VERSION "$Format:%h$"

NS_ :

BS_:

BU_: APB APP APS BCCEN BDY DAS DBG EAS EPAS EPAS2 EPAS3S EPB EPBM ESP GTW GTWU IBST IC MCU OCS PARK PARK3 RADAR RCM RT3000 SCCM SDM SEC TAS TAS2 TAS2DBG TOOL TPMS VCSEATD VCSEATP

BO_ 1412 SD_RS_SCCM: 8 SCCM
 SG_ SD_RS_SCCM : 7|64@0+ (1,0) [0|0] "" Vector__XXX

BO_ 1284 SG_APPL_SCCM: 8 SCCM
 SG_ SG_APPL_SCCM : 7|64@0+ (1,0) [0|0] "" Vector__XXX

BO_ 69 STW_ACTN_RQ: 8 SCCM
 SG_ SpdCtrlLvr_Stat : 0|6@1+ (1,0) [0|0] "" GTW,DAS,EPB
 SG_ VSL_Enbl_Rq : 6|1@1+ (1,0) [0|0] "" GTW,EPB,DAS
 SG_ SpdCtrlLvrStat_Inv : 7|1@1+ (1,0) [0|0] "" GTW
 SG_ DTR_Dist_Rq : 8|8@1+ (1,0) [0|200] "" GTW,DAS
 SG_ TurnIndLvr_Stat : 16|2@1+ (1,0) [0|0] "" DAS,BDY,GTW,PARK
 SG_ HiBmLvr_Stat : 18|2@1+ (1,0) [0|0] "" BDY,BCCEN,DAS,GTW
 SG_ WprWashSw_Psd : 20|2@1+ (1,0) [0|0] "" BDY,BCCEN,DAS,GTW
 SG_ WprWash_R_Sw_Posn_V2 : 22|2@1+ (1,0) [0|0] "" BDY,BCCEN,GTW
 SG_ StW_Lvr_Stat : 24|3@1+ (1,0) [0|0] "" GTW
 SG_ StW_Cond_Flt : 27|1@1+ (1,0) [0|0] "" GTW
 SG_ StW_Cond_Psd : 28|2@1+ (1,0) [0|0] "" GTW
 SG_ HrnSw_Psd : 30|2@1+ (1,0) [0|0] "" SEC,BDY,BCCEN,GTW,APP
 SG_ StW_Sw00_Psd : 32|1@1+ (1,0) [0|0] "" GTW,DAS
 SG_ StW_Sw01_Psd : 33|1@1+ (1,0) [0|0] "" GTW,DAS
 SG_ StW_Sw02_Psd : 34|1@1+ (1,0) [0|0] "" GTW,DAS
 SG_ StW_Sw03_Psd : 35|1@1+ (1,0) [0|0] "" GTW,DAS
 SG_ StW_Sw04_Psd : 36|1@1+ (1,0) [0|0] "" GTW,DAS
 SG_ StW_Sw05_Psd : 37|1@1+ (1,0) [0|0] "" GTW,DAS
 SG_ StW_Sw06_Psd : 38|1@1+ (1,0) [0|0] "" GTW,DAS
 SG_ StW_Sw07_Psd : 39|1@1+ (1,0) [0|0] "" GTW,DAS
 SG_ StW_Sw08_Psd : 40|1@1+ (1,0) [0|0] "" GTW,DAS
 SG_ StW_Sw09_Psd : 41|1@1+ (1,0) [0|0] "" GTW,DAS
 SG_ StW_Sw10_Psd : 42|1@1+ (1,0) [0|0] "" GTW,DAS
 SG_ StW_Sw11_Psd : 43|1@1+ (1,0) [0|0] "" GTW,DAS
 SG_ StW_Sw12_Psd : 44|1@1+ (1,0) [0|0] "" GTW,DAS
 SG_ StW_Sw13_Psd : 45|1@1+ (1,0) [0|0] "" GTW,DAS
 SG_ StW_Sw14_Psd : 46|1@1+ (1,0) [0|0] "" GTW
 SG_ StW_Sw15_Psd : 47|1@1+ (1,0) [0|0] "" GTW
 SG_ WprSw6Posn : 48|3@1+ (1,0) [0|0] "" BDY,BCCEN,GTW,APP
 SG_ MC_STW_ACTN_RQ : 52|4@1+ (1,0) [0|15] "" GTW
 SG_ CRC_STW_ACTN_RQ : 56|8@1+ (1,0) [0|0] "" GTW

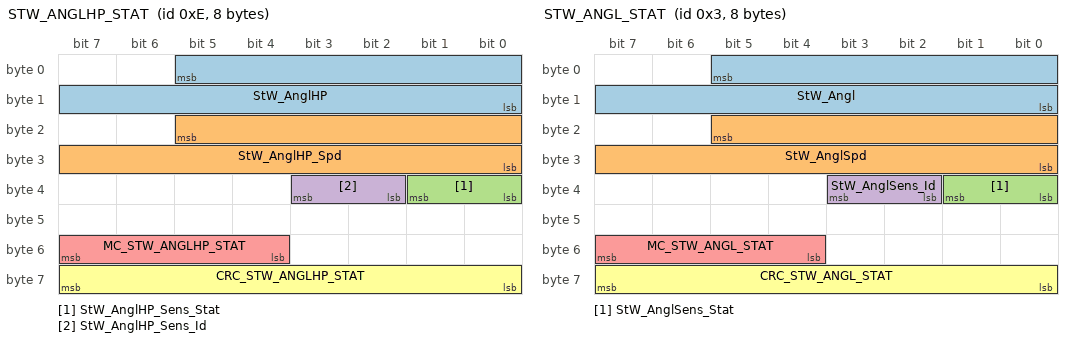
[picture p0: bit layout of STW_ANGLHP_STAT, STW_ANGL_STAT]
BO_ 14 STW_ANGLHP_STAT: 8 SCCM
 SG_ StW_AnglHP : 5|14@0+ (0.1,-819.2) [-819.2|819] "deg" DAS,GTW,ESP,RCM,PARK,EPAS,EPAS2,EPAS3S,TAS
 SG_ StW_AnglHP_Spd : 21|14@0+ (0.5,-4096) [-4096|4095.5] "deg/s" GTW,DAS,PARK,EPAS,EPAS2,EPAS3S,TAS
 SG_ StW_AnglHP_Sens_Stat : 33|2@0+ (1,0) [0|0] "" DAS,GTW,ESP,PARK,EPAS,EPAS2,EPAS3S,TAS,RCM
 SG_ StW_AnglHP_Sens_Id : 35|2@0+ (1,0) [0|0] "" GTW,PARK,EPAS,EPAS2,EPAS3S
 SG_ MC_STW_ANGLHP_STAT : 55|4@0+ (1,0) [0|15] "" GTW,ESP,RCM,PARK,EPAS,EPAS2,EPAS3S,TAS
 SG_ CRC_STW_ANGLHP_STAT : 63|8@0+ (1,0) [0|0] "" ESP,GTW,RCM,PARK,EPAS,EPAS2,EPAS3S,TAS

BO_ 3 STW_ANGL_STAT: 8 SCCM
 SG_ StW_Angl : 5|14@0+ (0.5,-2048) [-2048|2047] "deg" SDM,BDY,BCCEN,GTW
 SG_ StW_AnglSpd : 21|14@0+ (0.5,-2048) [-2048|2047] "/s" GTW
 SG_ StW_AnglSens_Stat : 33|2@0+ (1,0) [0|0] "" SDM,BDY,BCCEN,GTW
 SG_ StW_AnglSens_Id : 35|2@0+ (1,0) [0|0] "" GTW
 SG_ MC_STW_ANGL_STAT : 55|4@0+ (1,0) [0|15] "" SDM,GTW
 SG_ CRC_STW_ANGL_STAT : 63|8@0+ (1,0) [0|0] "" SDM,GTW

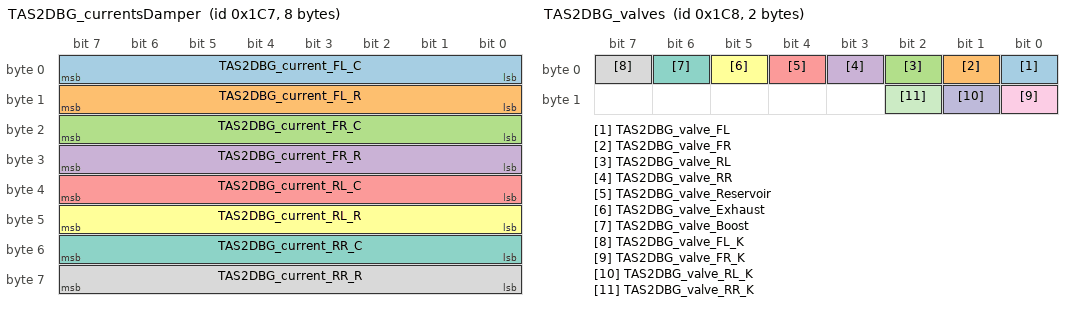
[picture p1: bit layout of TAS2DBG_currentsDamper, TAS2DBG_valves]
BO_ 455 TAS2DBG_currentsDamper: 8 TAS2DBG
 SG_ TAS2DBG_current_FL_C : 0|8@1+ (0.0075,0) [0|1.9125] "A" TAS2
 SG_ TAS2DBG_current_FL_R : 8|8@1+ (0.0075,0) [0|1.9125] "A" TAS2
 SG_ TAS2DBG_current_FR_C : 16|8@1+ (0.0075,0) [0|1.9125] "A" TAS2
 SG_ TAS2DBG_current_FR_R : 24|8@1+ (0.0075,0) [0|1.9125] "A" TAS2
 SG_ TAS2DBG_current_RL_C : 32|8@1+ (0.0075,0) [0|1.9125] "A" TAS2
 SG_ TAS2DBG_current_RL_R : 40|8@1+ (0.0075,0) [0|1.9125] "A" TAS2
 SG_ TAS2DBG_current_RR_C : 48|8@1+ (0.0075,0) [0|1.9125] "A" TAS2
 SG_ TAS2DBG_current_RR_R : 56|8@1+ (0.0075,0) [0|1.9125] "A" TAS2

BO_ 456 TAS2DBG_valves: 2 TAS2DBG
 SG_ TAS2DBG_valve_FL : 0|1@1+ (1,0) [0|1] "" TAS2
 SG_ TAS2DBG_valve_FR : 1|1@1+ (1,0) [0|1] "" TAS2
 SG_ TAS2DBG_valve_RL : 2|1@1+ (1,0) [0|1] "" TAS2
 SG_ TAS2DBG_valve_RR : 3|1@1+ (1,0) [0|1] "" TAS2
 SG_ TAS2DBG_valve_Reservoir : 4|1@1+ (1,0) [0|1] "" TAS2
 SG_ TAS2DBG_valve_Exhaust : 5|1@1+ (1,0) [0|1] "" TAS2
 SG_ TAS2DBG_valve_Boost : 6|1@1+ (1,0) [0|1] "" TAS2
 SG_ TAS2DBG_valve_FL_K : 7|1@1+ (1,0) [0|1] "" TAS2
 SG_ TAS2DBG_valve_FR_K : 8|1@1+ (1,0) [0|1] "" TAS2
 SG_ TAS2DBG_valve_RL_K : 9|1@1+ (1,0) [0|1] "" TAS2
 SG_ TAS2DBG_valve_RR_K : 10|1@1+ (1,0) [0|1] "" TAS2

BO_ 1340 TAS2_alertCleared: 2 TAS2
 SG_ TAS2_alertClearedID : 0|9@1+ (1,0) [0|317] "" Vector__XXX

BO_ 1293 TAS2_alertLog: 8 TAS2
 SG_ TAS2_alertID M : 0|9@1+ (1,0) [0|317] "" GTW
 SG_ TAS2_alertType : 15|1@1+ (1,0) [0|1] "" GTW
 SG_ TAS2_a000_alertDataW0 m0 : 16|16@1+ (1,0) [0|65535] "" Vector__XXX
 SG_ TAS2_a000_alertDataW1 m0 : 32|16@1+ (1,0) [0|65535] "" Vector__XXX
 SG_ TAS2_a000_alertDataW2 m0 : 48|16@1+ (1,0) [0|65535] "" Vector__XXX
 SG_ TAS2_a001_InternalWatchdog m1 : 16|1@1+ (1,0) [0|1] "" GTW
 SG_ TAS2_a002_CPUUndervoltage m2 : 16|1@1+ (1,0) [0|1] "" GTW
 SG_ TAS2_a002_PowerOnReset m2 : 17|1@1+ (1,0) [0|1] "" GTW
 SG_ TAS2_a003_AssertID m3 : 16|16@1+ (1,0) [0|65535] "" GTW
 SG_ TAS2_a003_LineNumber m3 : 32|16@1+ (1,0) [0|65535] "" GTW
 SG_ TAS2_a003_Data m3 : 48|16@1+ (1,0) [0|65535] "" GTW
 SG_ TAS2_a012_ClockError m12 : 16|1@1+ (1,0) [0|1] "" GTW
 SG_ TAS2_a012_FlashError m12 : 17|1@1+ (1,0) [0|1] "" GTW
 SG_ TAS2_a012_SoftwareReset m12 : 18|1@1+ (1,0) [0|1] "" GTW
 SG_ TAS2_a012_CheckstopReset m12 : 19|1@1+ (1,0) [0|1] "" GTW
 SG_ TAS2_a012_DebugReset m12 : 20|1@1+ (1,0) [0|1] "" GTW
 SG_ TAS2_a012_ExternalReset m12 : 21|1@1+ (1,0) [0|1] "" GTW
 SG_ TAS2_a015_NVMMRecordNotFound m15 : 16|1@1+ (1,0) [0|1] "" GTW
 SG_ TAS2_a015_NVMMCRCMismatch m15 : 17|1@1+ (1,0) [0|1] "" GTW
 SG_ TAS2_a015_NVMMVersionMismatch m15 : 18|1@1+ (1,0) [0|1] "" GTW
 SG_ TAS2_a015_NVMMRecordUpgraded m15 : 19|1@1+ (1,0) [0|1] "" GTW
 SG_ TAS2_a015_NVMMMemOverflow m15 : 20|1@1+ (1,0) [0|1] "" GTW
 SG_ TAS2_a015_NVMMWriteFailed m15 : 21|1@1+ (1,0) [0|1] "" GTW
 SG_ TAS2_a021_Task1msLate m21 : 16|1@1+ (1,0) [0|1] "" GTW
 SG_ TAS2_a021_Task1msStarved m21 : 17|1@1+ (1,0) [0|1] "" GTW
 SG_ TAS2_a021_Task1msMissed m21 : 18|1@1+ (1,0) [0|1] "" GTW
 SG_ TAS2_a021_Task10msLate m21 : 19|1@1+ (1,0) [0|1] "" GTW
 SG_ TAS2_a021_Task10msStarved m21 : 20|1@1+ (1,0) [0|1] "" GTW
 SG_ TAS2_a021_Task10msMissed m21 : 21|1@1+ (1,0) [0|1] "" GTW
 SG_ TAS2_a021_Task100msLate m21 : 22|1@1+ (1,0) [0|1] "" GTW
 SG_ TAS2_a021_Task100msStarved m21 : 23|1@1+ (1,0) [0|1] "" GTW
 SG_ TAS2_a021_Task100msMissed m21 : 24|1@1+ (1,0) [0|1] "" GTW
 SG_ TAS2_a021_Task1000msLate m21 : 25|1@1+ (1,0) [0|1] "" GTW
 SG_ TAS2_a021_Task1000msStarved m21 : 26|1@1+ (1,0) [0|1] "" GTW
 SG_ TAS2_a021_Task1000msMissed m21 : 27|1@1+ (1,0) [0|1] "" GTW
 SG_ TAS2_a022_TaskInitErrorCount m22 : 16|8@1+ (1,0) [0|255] "" GTW
 SG_ TAS2_a022_TaskInitError0 m22 : 24|8@1+ (1,0) [0|255] "" GTW
 SG_ TAS2_a022_TaskInitError1 m22 : 32|8@1+ (1,0) [0|255] "" GTW
 SG_ TAS2_a022_TaskInitError2 m22 : 40|8@1+ (1,0) [0|255] "" GTW
 SG_ TAS2_a022_TaskInitError3 m22 : 48|8@1+ (1,0) [0|255] "" GTW
 SG_ TAS2_a022_TaskInitError4 m22 : 56|8@1+ (1,0) [0|255] "" GTW
 SG_ TAS2_a025_vehicleLockAtCrash m25 : 16|1@1+ (1,0) [0|1] "" GTW
 SG_ TAS2_a025_CANCrashIsActive m25 : 17|1@1+ (1,0) [0|1] "" GTW
 SG_ TAS2_a025_appCrashIsActive m25 : 18|1@1+ (1,0) [0|1] "" GTW
 SG_ TAS2_a025_lastCrashEvent m25 : 24|32@1+ (1,0) [0|4294967295] "" GTW
 SG_ TAS2_a030_PWMdutyCycleFL m30 : 16|16@1+ (0.0025,0) [0|100] "%" GTW
 SG_ TAS2_a030_PWMfrequencyFL m30 : 32|16@1+ (0.025,0) [0|1000] "Hz" GTW
 SG_ TAS2_a030_PWMfaultFL m30 : 48|3@1+ (1,0) [0|6] "" GTW
 SG_ TAS2_a031_PWMdutyCycleFR m31 : 16|16@1+ (0.0025,0) [0|100] "%" GTW
 SG_ TAS2_a031_PWMfrequencyFR m31 : 32|16@1+ (0.025,0) [0|1000] "Hz" GTW
 SG_ TAS2_a031_PWMfaultFR m31 : 48|3@1+ (1,0) [0|6] "" GTW
 SG_ TAS2_a032_PWMdutyCycleRL m32 : 16|16@1+ (0.0025,0) [0|100] "%" GTW
 SG_ TAS2_a032_PWMfrequencyRL m32 : 32|16@1+ (0.025,0) [0|1000] "Hz" GTW
 SG_ TAS2_a032_PWMfaultRL m32 : 48|3@1+ (1,0) [0|6] "" GTW
 SG_ TAS2_a033_PWMdutyCycleRR m33 : 16|16@1+ (0.0025,0) [0|100] "%" GTW
 SG_ TAS2_a033_PWMfrequencyRR m33 : 32|16@1+ (0.025,0) [0|1000] "Hz" GTW
 SG_ TAS2_a033_PWMfaultRR m33 : 48|3@1+ (1,0) [0|6] "" GTW
 SG_ TAS2_a034_PWMdutyCycleFL m34 : 16|16@1+ (0.0025,0) [0|100] "%" GTW
 SG_ TAS2_a034_PWMfrequencyFL m34 : 32|16@1+ (0.025,0) [0|1000] "Hz" GTW
 SG_ TAS2_a034_PWMfaultFL m34 : 48|3@1+ (1,0) [0|6] "" GTW
 SG_ TAS2_a035_PWMdutyCycleFR m35 : 16|16@1+ (0.0025,0) [0|100] "%" GTW
 SG_ TAS2_a035_PWMfrequencyFR m35 : 32|16@1+ (0.025,0) [0|1000] "Hz" GTW
 SG_ TAS2_a035_PWMfaultFR m35 : 48|3@1+ (1,0) [0|6] "" GTW
 SG_ TAS2_a036_PWMdutyCycleRL m36 : 16|16@1+ (0.0025,0) [0|100] "%" GTW
 SG_ TAS2_a036_PWMfrequencyRL m36 : 32|16@1+ (0.025,0) [0|1000] "Hz" GTW
 SG_ TAS2_a036_PWMfaultRL m36 : 48|3@1+ (1,0) [0|6] "" GTW
 SG_ TAS2_a037_PWMdutyCycleRR m37 : 16|16@1+ (0.0025,0) [0|100] "%" GTW
 SG_ TAS2_a037_PWMfrequencyRR m37 : 32|16@1+ (0.025,0) [0|1000] "Hz" GTW
 SG_ TAS2_a037_PWMfaultRR m37 : 48|3@1+ (1,0) [0|6] "" GTW
 SG_ TAS2_a038_PWMdutyCycleFL m38 : 16|16@1+ (0.0025,0) [0|100] "%" GTW
 SG_ TAS2_a038_PWMfrequencyFL m38 : 32|16@1+ (0.025,0) [0|1000] "Hz" GTW
 SG_ TAS2_a038_PWMfaultFL m38 : 48|3@1+ (1,0) [0|6] "" GTW
 SG_ TAS2_a039_PWMdutyCycleFR m39 : 16|16@1+ (0.0025,0) [0|100] "%" GTW
 SG_ TAS2_a039_PWMfrequencyFR m39 : 32|16@1+ (0.025,0) [0|1000] "Hz" GTW
 SG_ TAS2_a039_PWMfaultFR m39 : 48|3@1+ (1,0) [0|6] "" GTW
 SG_ TAS2_a040_PWMdutyCycleRL m40 : 16|16@1+ (0.0025,0) [0|100] "%" GTW
 SG_ TAS2_a040_PWMfrequencyRL m40 : 32|16@1+ (0.025,0) [0|1000] "Hz" GTW
 SG_ TAS2_a040_PWMfaultRL m40 : 48|3@1+ (1,0) [0|6] "" GTW
 SG_ TAS2_a041_PWMdutyCycleRR m41 : 16|16@1+ (0.0025,0) [0|100] "%" GTW
 SG_ TAS2_a041_PWMfrequencyRR m41 : 32|16@1+ (0.025,0) [0|1000] "Hz" GTW
 SG_ TAS2_a041_PWMfaultRR m41 : 48|3@1+ (1,0) [0|6] "" GTW
 SG_ TAS2_a043_CallTrace0 m43 : 16|24@1+ (1,0) [0|16777215] "" GTW
 SG_ TAS2_a043_CallTrace1 m43 : 40|24@1+ (1,0) [0|16777215] "" GTW
 SG_ TAS2_a044_CallTrace0 m44 : 16|24@1+ (1,0) [0|16777215] "" GTW
 SG_ TAS2_a044_CallTrace1 m44 : 40|24@1+ (1,0) [0|16777215] "" GTW
 SG_ TAS2_a045_CallTrace0 m45 : 16|24@1+ (1,0) [0|16777215] "" GTW
 SG_ TAS2_a045_CallTrace1 m45 : 40|24@1+ (1,0) [0|16777215] "" GTW
 SG_ TAS2_a046_CallTrace0 m46 : 16|24@1+ (1,0) [0|16777215] "" GTW
 SG_ TAS2_a046_CallTrace1 m46 : 40|24@1+ (1,0) [0|16777215] "" GTW
 SG_ TAS2_a070_voltage12V m70 : 16|16@1+ (0.001,0) [0|32] "V" GTW
 SG_ TAS2_a071_voltage12V m71 : 16|16@1+ (0.001,0) [0|32] "V" GTW
 SG_ TAS2_a072_voltage5VOnBoard m72 : 16|16@1+ (0.001,0) [0|32] "V" GTW
 SG_ TAS2_a073_voltage5VOnBoard m73 : 16|16@1+ (0.001,0) [0|32] "V" GTW
 SG_ TAS2_a077_sensorVoltage m77 : 16|16@1+ (0.001,0) [0|32] "V" GTW
 SG_ TAS2_a077_sensorRefVoltage m77 : 32|16@1+ (0.001,0) [0|32] "V" GTW
 SG_ TAS2_a078_sensorVoltage m78 : 16|16@1+ (0.001,0) [0|32] "V" GTW
 SG_ TAS2_a078_sensorRefVoltage m78 : 32|16@1+ (0.001,0) [0|32] "V" GTW
 SG_ TAS2_a080_voltage5VHeight m80 : 16|16@1+ (0.001,0) [0|32] "V" GTW
 SG_ TAS2_a081_voltage5VHeight m81 : 16|16@1+ (0.001,0) [0|32] "V" GTW
 SG_ TAS2_a082_voltage5VHeight m82 : 16|16@1+ (0.001,0) [0|32] "V" GTW
 SG_ TAS2_a083_voltage5VAnalog m83 : 16|16@1+ (0.001,0) [0|32] "V" GTW
 SG_ TAS2_a084_voltage5VAnalog m84 : 16|16@1+ (0.001,0) [0|32] "V" GTW
 SG_ TAS2_a085_voltage5VAnalog m85 : 16|16@1+ (0.001,0) [0|32] "V" GTW
 SG_ TAS2_a086_voltage12VSwitched m86 : 16|16@1+ (0.001,0) [0|32] "V" GTW
 SG_ TAS2_a087_voltage12VSwitched m87 : 16|16@1+ (0.001,0) [0|32] "V" GTW
 SG_ TAS2_a093_readError m93 : 16|1@1+ (1,0) [0|1] "" GTW
 SG_ TAS2_a093_IVOR2Exception m93 : 17|1@1+ (1,0) [0|1] "" GTW
 SG_ TAS2_a094_DAS_status_MIA m94 : 16|1@1+ (1,0) [0|1] "" GTW
 SG_ TAS2_a095_DIS_torque1_MIA m95 : 16|1@1+ (1,0) [0|1] "" GTW
 SG_ TAS2_a096_IMU_ID1_MIA m96 : 16|1@1+ (1,0) [0|1] "" GTW
 SG_ TAS2_a096_IMU_ID2_MIA m96 : 17|1@1+ (1,0) [0|1] "" GTW
 SG_ TAS2_a096_IMU_ID5_MIA m96 : 18|1@1+ (1,0) [0|1] "" GTW
 SG_ TAS2_a096_IMU_ID6_MIA m96 : 19|1@1+ (1,0) [0|1] "" GTW
 SG_ TAS2_a097_RCM_ID1_MIA m97 : 16|1@1+ (1,0) [0|1] "" GTW
 SG_ TAS2_a097_RCM_ID2_MIA m97 : 17|1@1+ (1,0) [0|1] "" GTW
 SG_ TAS2_a097_RCM_ID5_MIA m97 : 18|1@1+ (1,0) [0|1] "" GTW
 SG_ TAS2_a097_RCM_ID6_MIA m97 : 19|1@1+ (1,0) [0|1] "" GTW
 SG_ TAS2_a098_MCU_chassisControl_MIA m98 : 16|1@1+ (1,0) [0|1] "" GTW
 SG_ TAS2_a098_MCU_utcTime_MIA m98 : 17|1@1+ (1,0) [0|1] "" GTW
 SG_ TAS2_a098_UI_drvrAsstMapData_MIA m98 : 18|1@1+ (1,0) [0|1] "" GTW
 SG_ TAS2_a098_UI_suspControl_MIA m98 : 19|1@1+ (1,0) [0|1] "" GTW
 SG_ TAS2_a099_EFUSE_status_MIA m99 : 16|1@1+ (1,0) [0|1] "" GTW
 SG_ TAS2_a100_STW_ANGLHP_STAT_MIA m100 : 16|1@1+ (1,0) [0|1] "" GTW
 SG_ TAS2_a101_ESP_115h_MIA m101 : 16|1@1+ (1,0) [0|1] "" GTW
 SG_ TAS2_a101_ESP_145h_MIA m101 : 17|1@1+ (1,0) [0|1] "" GTW
 SG_ TAS2_a101_ESP_B_MIA m101 : 18|1@1+ (1,0) [0|1] "" GTW
 SG_ TAS2_a101_ESP_C_MIA m101 : 19|1@1+ (1,0) [0|1] "" GTW
 SG_ TAS2_a101_ESP_brakeTorque_MIA m101 : 20|1@1+ (1,0) [0|1] "" GTW
 SG_ TAS2_a101_ESP_wheelSpeeds_MIA m101 : 21|1@1+ (1,0) [0|1] "" GTW
 SG_ TAS2_a102_DI_espControl_MIA m102 : 16|1@1+ (1,0) [0|1] "" GTW
 SG_ TAS2_a102_DI_state_MIA m102 : 17|1@1+ (1,0) [0|1] "" GTW
 SG_ TAS2_a102_DI_state2_MIA m102 : 18|1@1+ (1,0) [0|1] "" GTW
 SG_ TAS2_a102_DI_torque1_MIA m102 : 19|1@1+ (1,0) [0|1] "" GTW
 SG_ TAS2_a102_DI_torque2_MIA m102 : 20|1@1+ (1,0) [0|1] "" GTW
 SG_ TAS2_a103_GTW_ESP1_MIA m103 : 16|1@1+ (1,0) [0|1] "" GTW
 SG_ TAS2_a103_GTW_carConfig_MIA m103 : 17|1@1+ (1,0) [0|1] "" GTW
 SG_ TAS2_a103_GTW_carState_MIA m103 : 18|1@1+ (1,0) [0|1] "" GTW
 SG_ TAS2_a103_GTW_chNm_MIA m103 : 19|1@1+ (1,0) [0|1] "" GTW
 SG_ TAS2_a103_GTW_odo_MIA m103 : 20|1@1+ (1,0) [0|1] "" GTW
 SG_ TAS2_a103_GTW_status_MIA m103 : 21|1@1+ (1,0) [0|1] "" GTW
 SG_ TAS2_a103_VIN_MIA m103 : 22|1@1+ (1,0) [0|1] "" GTW
 SG_ TAS2_a106_CPULoadTotal m106 : 16|8@1+ (1,0) [0|255] "" GTW
 SG_ TAS2_a106_CPULoad1msTask m106 : 24|8@1+ (1,0) [0|255] "" GTW
 SG_ TAS2_a106_CPULoad10msTask m106 : 32|8@1+ (1,0) [0|255] "" GTW
 SG_ TAS2_a106_CPULoad100msTask m106 : 40|8@1+ (1,0) [0|255] "" GTW
 SG_ TAS2_a106_CPULoad1000msTask m106 : 48|8@1+ (1,0) [0|255] "" GTW
 SG_ TAS2_a106_CPULoadNVMMTask m106 : 56|8@1+ (1,0) [0|255] "" GTW
 SG_ TAS2_a107_Usage1msTask m107 : 16|8@1+ (1,0) [0|255] "" GTW
 SG_ TAS2_a107_Usage10msTask m107 : 24|8@1+ (1,0) [0|255] "" GTW
 SG_ TAS2_a107_Usage100msTask m107 : 32|8@1+ (1,0) [0|255] "" GTW
 SG_ TAS2_a107_Usage1000msTask m107 : 40|8@1+ (1,0) [0|255] "" GTW
 SG_ TAS2_a107_UsageUDSTask m107 : 48|8@1+ (1,0) [0|255] "" GTW
 SG_ TAS2_a107_UsageNVMMTask m107 : 56|8@1+ (1,0) [0|255] "" GTW
 SG_ TAS2_a121_dutyCycleFL m121 : 16|8@1+ (1,0) [0|100] "%" GTW
 SG_ TAS2_a121_ambientTemperature m121 : 24|8@1+ (1,-40) [-40|215] "degC" GTW
 SG_ TAS2_a121_12VtoValve m121 : 32|16@1+ (0.001,0) [0|32] "V" GTW
 SG_ TAS2_a122_dutyCycleFR m122 : 16|8@1+ (1,0) [0|100] "%" GTW
 SG_ TAS2_a122_ambientTemperature m122 : 24|8@1+ (1,-40) [-40|215] "degC" GTW
 SG_ TAS2_a122_12VtoValve m122 : 32|16@1+ (0.001,0) [0|32] "V" GTW
 SG_ TAS2_a123_dutyCycleRL m123 : 16|8@1+ (1,0) [0|100] "%" GTW
 SG_ TAS2_a123_ambientTemperature m123 : 24|8@1+ (1,-40) [-40|215] "degC" GTW
 SG_ TAS2_a123_12VtoValve m123 : 32|16@1+ (0.001,0) [0|32] "V" GTW
 SG_ TAS2_a124_dutyCycleRR m124 : 16|8@1+ (1,0) [0|100] "%" GTW
 SG_ TAS2_a124_ambientTemperature m124 : 24|8@1+ (1,-40) [-40|215] "degC" GTW
 SG_ TAS2_a124_12VtoValve m124 : 32|16@1+ (0.001,0) [0|32] "V" GTW
 SG_ TAS2_a125_dutyCycleReservoir m125 : 16|8@1+ (1,0) [0|100] "%" GTW
 SG_ TAS2_a125_ambientTemperature m125 : 24|8@1+ (1,-40) [-40|215] "degC" GTW
 SG_ TAS2_a125_12VtoValve m125 : 32|16@1+ (0.001,0) [0|32] "V" GTW
 SG_ TAS2_a126_dutyCycleExhaust m126 : 16|8@1+ (1,0) [0|100] "%" GTW
 SG_ TAS2_a126_ambientTemperature m126 : 24|8@1+ (1,-40) [-40|215] "degC" GTW
 SG_ TAS2_a126_12VtoValve m126 : 32|16@1+ (0.001,0) [0|32] "V" GTW
 SG_ TAS2_a127_dutyCycleBoost m127 : 16|8@1+ (1,0) [0|100] "%" GTW
 SG_ TAS2_a127_ambientTemperature m127 : 24|8@1+ (1,-40) [-40|215] "degC" GTW
 SG_ TAS2_a127_12VtoValve m127 : 32|16@1+ (0.001,0) [0|32] "V" GTW
 SG_ TAS2_a128_dutyCycleCompressor m128 : 16|8@1+ (1,0) [0|100] "%" GTW
 SG_ TAS2_a128_ambientTemperature m128 : 24|8@1+ (1,-40) [-40|215] "degC" GTW
 SG_ TAS2_a128_12VtoValve m128 : 32|16@1+ (0.001,0) [0|32] "V" GTW
 SG_ TAS2_a129_valveFaultType m129 : 16|3@1+ (1,0) [0|7] "" GTW
 SG_ TAS2_a129_valveVoltage m129 : 24|16@1+ (0.001,0) [0|32] "V" GTW
 SG_ TAS2_a129_valveCurrent m129 : 40|16@1+ (0.001,0) [0|32] "A" GTW
 SG_ TAS2_a130_valveFaultType m130 : 16|3@1+ (1,0) [0|7] "" GTW
 SG_ TAS2_a130_valveVoltage m130 : 24|16@1+ (0.001,0) [0|32] "V" GTW
 SG_ TAS2_a130_valveCurrent m130 : 40|16@1+ (0.001,0) [0|32] "A" GTW
 SG_ TAS2_a131_valveFaultType m131 : 16|3@1+ (1,0) [0|7] "" GTW
 SG_ TAS2_a131_valveVoltage m131 : 24|16@1+ (0.001,0) [0|32] "V" GTW
 SG_ TAS2_a131_valveCurrent m131 : 40|16@1+ (0.001,0) [0|32] "A" GTW
 SG_ TAS2_a132_valveFaultType m132 : 16|3@1+ (1,0) [0|7] "" GTW
 SG_ TAS2_a132_valveVoltage m132 : 24|16@1+ (0.001,0) [0|32] "V" GTW
 SG_ TAS2_a132_valveCurrent m132 : 40|16@1+ (0.001,0) [0|32] "A" GTW
 SG_ TAS2_a133_valveFaultType m133 : 16|3@1+ (1,0) [0|7] "" GTW
 SG_ TAS2_a133_valveVoltage m133 : 24|16@1+ (0.001,0) [0|32] "V" GTW
 SG_ TAS2_a133_valveCurrent m133 : 40|16@1+ (0.001,0) [0|32] "A" GTW
 SG_ TAS2_a134_valveFaultType m134 : 16|3@1+ (1,0) [0|7] "" GTW
 SG_ TAS2_a134_valveVoltage m134 : 24|16@1+ (0.001,0) [0|32] "V" GTW
 SG_ TAS2_a134_valveCurrent m134 : 40|16@1+ (0.001,0) [0|32] "A" GTW
 SG_ TAS2_a135_valveFaultType m135 : 16|3@1+ (1,0) [0|7] "" GTW
 SG_ TAS2_a135_valveVoltage m135 : 24|16@1+ (0.001,0) [0|32] "V" GTW
 SG_ TAS2_a135_valveCurrent m135 : 40|16@1+ (0.001,0) [0|32] "A" GTW
 SG_ TAS2_a136_valveFaultType m136 : 16|3@1+ (1,0) [0|7] "" GTW
 SG_ TAS2_a136_valveVoltage m136 : 24|16@1+ (0.001,0) [0|32] "V" GTW
 SG_ TAS2_a136_valveCurrent m136 : 40|16@1+ (0.001,0) [0|32] "A" GTW
 SG_ TAS2_a137_valveFaultType m137 : 16|3@1+ (1,0) [0|7] "" GTW
 SG_ TAS2_a137_valveVoltage m137 : 24|16@1+ (0.001,0) [0|32] "V" GTW
 SG_ TAS2_a137_valveCurrent m137 : 40|16@1+ (0.001,0) [0|32] "A" GTW
 SG_ TAS2_a138_valveFaultType m138 : 16|3@1+ (1,0) [0|7] "" GTW
 SG_ TAS2_a138_valveVoltage m138 : 24|16@1+ (0.001,0) [0|32] "V" GTW
 SG_ TAS2_a138_valveCurrent m138 : 40|16@1+ (0.001,0) [0|32] "A" GTW
 SG_ TAS2_a139_valveFaultType m139 : 16|3@1+ (1,0) [0|7] "" GTW
 SG_ TAS2_a139_valveVoltage m139 : 24|16@1+ (0.001,0) [0|32] "V" GTW
 SG_ TAS2_a139_valveCurrent m139 : 40|16@1+ (0.001,0) [0|32] "A" GTW
 SG_ TAS2_a140_valveFaultType m140 : 16|3@1+ (1,0) [0|7] "" GTW
 SG_ TAS2_a140_valveVoltage m140 : 24|16@1+ (0.001,0) [0|32] "V" GTW
 SG_ TAS2_a140_valveCurrent m140 : 40|16@1+ (0.001,0) [0|32] "A" GTW
 SG_ TAS2_a141_valveFaultType m141 : 16|3@1+ (1,0) [0|7] "" GTW
 SG_ TAS2_a141_valveVoltage m141 : 24|16@1+ (0.001,0) [0|32] "V" GTW
 SG_ TAS2_a141_valveCurrent m141 : 40|16@1+ (0.001,0) [0|32] "A" GTW
 SG_ TAS2_a142_valveFaultType m142 : 16|3@1+ (1,0) [0|7] "" GTW
 SG_ TAS2_a142_valveVoltage m142 : 24|16@1+ (0.001,0) [0|32] "V" GTW
 SG_ TAS2_a142_valveCurrent m142 : 40|16@1+ (0.001,0) [0|32] "A" GTW
 SG_ TAS2_a143_valveFaultType m143 : 16|3@1+ (1,0) [0|7] "" GTW
 SG_ TAS2_a143_valveVoltage m143 : 24|16@1+ (0.001,0) [0|32] "V" GTW
 SG_ TAS2_a143_valveCurrent m143 : 40|16@1+ (0.001,0) [0|32] "A" GTW
 SG_ TAS2_a144_valveFaultType m144 : 16|3@1+ (1,0) [0|7] "" GTW
 SG_ TAS2_a144_valveVoltage m144 : 24|16@1+ (0.001,0) [0|32] "V" GTW
 SG_ TAS2_a144_valveCurrent m144 : 40|16@1+ (0.001,0) [0|32] "A" GTW
 SG_ TAS2_a145_valveFaultType m145 : 16|3@1+ (1,0) [0|7] "" GTW
 SG_ TAS2_a145_valveVoltage m145 : 24|16@1+ (0.001,0) [0|32] "V" GTW
 SG_ TAS2_a145_valveCurrent m145 : 40|16@1+ (0.001,0) [0|32] "A" GTW
 SG_ TAS2_a146_valveFaultType m146 : 16|3@1+ (1,0) [0|7] "" GTW
 SG_ TAS2_a146_valveVoltage m146 : 24|16@1+ (0.001,0) [0|32] "V" GTW
 SG_ TAS2_a146_valveCurrent m146 : 40|16@1+ (0.001,0) [0|32] "A" GTW
 SG_ TAS2_a147_valveFaultType m147 : 16|3@1+ (1,0) [0|7] "" GTW
 SG_ TAS2_a147_valveVoltage m147 : 24|16@1+ (0.001,0) [0|32] "V" GTW
 SG_ TAS2_a147_valveCurrent m147 : 40|16@1+ (0.001,0) [0|32] "A" GTW
 SG_ TAS2_a148_valveFaultType m148 : 16|3@1+ (1,0) [0|7] "" GTW
 SG_ TAS2_a148_valveVoltage m148 : 24|16@1+ (0.001,0) [0|32] "V" GTW
 SG_ TAS2_a148_valveCurrent m148 : 40|16@1+ (0.001,0) [0|32] "A" GTW
 SG_ TAS2_a149_valveFaultType m149 : 16|3@1+ (1,0) [0|7] "" GTW
 SG_ TAS2_a149_valveVoltage m149 : 24|16@1+ (0.001,0) [0|32] "V" GTW
 SG_ TAS2_a149_valveCurrent m149 : 40|16@1+ (0.001,0) [0|32] "A" GTW
 SG_ TAS2_a150_valveFaultType m150 : 16|3@1+ (1,0) [0|7] "" GTW
 SG_ TAS2_a150_valveVoltage m150 : 24|16@1+ (0.001,0) [0|32] "V" GTW
 SG_ TAS2_a150_valveCurrent m150 : 40|16@1+ (0.001,0) [0|32] "A" GTW
 SG_ TAS2_a151_valveFaultType m151 : 16|3@1+ (1,0) [0|7] "" GTW
 SG_ TAS2_a151_valveVoltage m151 : 24|16@1+ (0.001,0) [0|32] "V" GTW
 SG_ TAS2_a151_valveCurrent m151 : 40|16@1+ (0.001,0) [0|32] "A" GTW
 SG_ TAS2_a152_valveFaultType m152 : 16|3@1+ (1,0) [0|7] "" GTW
 SG_ TAS2_a152_valveVoltage m152 : 24|16@1+ (0.001,0) [0|32] "V" GTW
 SG_ TAS2_a152_valveCurrent m152 : 40|16@1+ (0.001,0) [0|32] "A" GTW
 SG_ TAS2_a153_valveFaultType m153 : 16|3@1+ (1,0) [0|7] "" GTW
 SG_ TAS2_a153_valveVoltage m153 : 24|16@1+ (0.001,0) [0|32] "V" GTW
 SG_ TAS2_a153_valveCurrent m153 : 40|16@1+ (0.001,0) [0|32] "A" GTW
 SG_ TAS2_a154_valveFaultType m154 : 16|3@1+ (1,0) [0|7] "" GTW
 SG_ TAS2_a154_valveVoltage m154 : 24|16@1+ (0.001,0) [0|32] "V" GTW
 SG_ TAS2_a154_valveCurrent m154 : 40|16@1+ (0.001,0) [0|32] "A" GTW
 SG_ TAS2_a155_valveFaultType m155 : 16|3@1+ (1,0) [0|7] "" GTW
 SG_ TAS2_a155_valveVoltage m155 : 24|16@1+ (0.001,0) [0|32] "V" GTW
 SG_ TAS2_a155_valveCurrent m155 : 40|16@1+ (0.001,0) [0|32] "A" GTW
 SG_ TAS2_a156_valveFaultType m156 : 16|3@1+ (1,0) [0|7] "" GTW
 SG_ TAS2_a156_valveVoltage m156 : 24|16@1+ (0.001,0) [0|32] "V" GTW
 SG_ TAS2_a156_valveCurrent m156 : 40|16@1+ (0.001,0) [0|32] "A" GTW
 SG_ TAS2_a157_valveFaultType m157 : 16|3@1+ (1,0) [0|7] "" GTW
 SG_ TAS2_a157_valveVoltage m157 : 24|16@1+ (0.001,0) [0|32] "V" GTW
 SG_ TAS2_a157_valveCurrent m157 : 40|16@1+ (0.001,0) [0|32] "A" GTW
 SG_ TAS2_a158_valveFaultType m158 : 16|3@1+ (1,0) [0|7] "" GTW
 SG_ TAS2_a158_valveVoltage m158 : 24|16@1+ (0.001,0) [0|32] "V" GTW
 SG_ TAS2_a158_valveCurrent m158 : 40|16@1+ (0.001,0) [0|32] "A" GTW
 SG_ TAS2_a159_valveFaultType m159 : 16|3@1+ (1,0) [0|7] "" GTW
 SG_ TAS2_a159_valveVoltage m159 : 24|16@1+ (0.001,0) [0|32] "V" GTW
 SG_ TAS2_a159_valveCurrent m159 : 40|16@1+ (0.001,0) [0|32] "A" GTW
 SG_ TAS2_a160_valveFaultType m160 : 16|3@1+ (1,0) [0|7] "" GTW
 SG_ TAS2_a160_valveVoltage m160 : 24|16@1+ (0.001,0) [0|32] "V" GTW
 SG_ TAS2_a160_valveCurrent m160 : 40|16@1+ (0.001,0) [0|32] "A" GTW
 SG_ TAS2_a165_damperValveFault m165 : 16|4@1+ (1,0) [0|10] "" GTW
 SG_ TAS2_a166_damperValveFault m166 : 16|4@1+ (1,0) [0|10] "" GTW
 SG_ TAS2_a167_damperValveFault m167 : 16|4@1+ (1,0) [0|10] "" GTW
 SG_ TAS2_a168_damperValveFault m168 : 16|4@1+ (1,0) [0|10] "" GTW
 SG_ TAS2_a169_damperValveFault m169 : 16|4@1+ (1,0) [0|10] "" GTW
 SG_ TAS2_a170_damperValveFault m170 : 16|4@1+ (1,0) [0|10] "" GTW
 SG_ TAS2_a171_damperValveFault m171 : 16|4@1+ (1,0) [0|10] "" GTW
 SG_ TAS2_a172_damperValveFault m172 : 16|4@1+ (1,0) [0|10] "" GTW
 SG_ TAS2_a173_heightDelta_mm m173 : 16|8@1+ (1,-128) [-128|127] "mm" GTW
 SG_ TAS2_a174_heightDelta_mm m174 : 16|8@1+ (1,-128) [-128|127] "mm" GTW
 SG_ TAS2_a175_heightDelta_mm m175 : 16|8@1+ (1,-128) [-128|127] "mm" GTW
 SG_ TAS2_a176_heightDelta_mm m176 : 16|8@1+ (1,-128) [-128|127] "mm" GTW
 SG_ TAS2_a210_heightSensorDeltaFL m210 : 16|8@1+ (1,-128) [-128|127] "mm" GTW
 SG_ TAS2_a210_heightSensorDeltaFR m210 : 24|8@1+ (1,-128) [-128|127] "mm" GTW
 SG_ TAS2_a210_heightSensorDeltaRL m210 : 32|8@1+ (1,-128) [-128|127] "mm" GTW
 SG_ TAS2_a210_heightSensorDeltaRR m210 : 40|8@1+ (1,-128) [-128|127] "mm" GTW
 SG_ TAS2_a220_galleryPressure m220 : 16|8@1+ (0.1,0) [0|25.5] "bara" GTW
 SG_ TAS2_a221_galleryPressureDelta m221 : 16|8@1+ (0.1,0) [0|25.5] "bar" GTW
 SG_ TAS2_a221_timeInIdle m221 : 24|32@1+ (1,0) [0|4294967295] "" GTW
 SG_ TAS2_a222_galleryPressureDelta m222 : 16|8@1+ (0.1,0) [0|25.5] "bar" GTW
 SG_ TAS2_a223_galleryPressure m223 : 16|8@1+ (0.1,0) [0|25.5] "bara" GTW
 SG_ TAS2_a223_valveOnFL m223 : 24|1@1+ (1,0) [0|1] "" GTW
 SG_ TAS2_a223_valveOnFR m223 : 25|1@1+ (1,0) [0|1] "" GTW
 SG_ TAS2_a223_valveOnRL m223 : 26|1@1+ (1,0) [0|1] "" GTW
 SG_ TAS2_a223_valveOnRR m223 : 27|1@1+ (1,0) [0|1] "" GTW
 SG_ TAS2_a223_valveOnReservoir m223 : 28|1@1+ (1,0) [0|1] "" GTW
 SG_ TAS2_a224_galleryPressure m224 : 16|8@1+ (0.1,0) [0|25.5] "bara" GTW
 SG_ TAS2_a224_valveOnFL m224 : 24|1@1+ (1,0) [0|1] "" GTW
 SG_ TAS2_a224_valveOnFR m224 : 25|1@1+ (1,0) [0|1] "" GTW
 SG_ TAS2_a224_valveOnRL m224 : 26|1@1+ (1,0) [0|1] "" GTW
 SG_ TAS2_a224_valveOnRR m224 : 27|1@1+ (1,0) [0|1] "" GTW
 SG_ TAS2_a224_valveOnReservoir m224 : 28|1@1+ (1,0) [0|1] "" GTW
 SG_ TAS2_a225_galleryPressure m225 : 16|8@1+ (0.1,0) [0|25.5] "bara" GTW
 SG_ TAS2_a226_PWMdutyCycleFL m226 : 16|16@1+ (0.0025,0) [0|100] "%" GTW
 SG_ TAS2_a226_PWMfrequencyFL m226 : 32|16@1+ (0.025,0) [0|1000] "Hz" GTW
 SG_ TAS2_a226_PWMfaultFL m226 : 48|3@1+ (1,0) [0|6] "" GTW
 SG_ TAS2_a227_PWMdutyCycleFR m227 : 16|16@1+ (0.0025,0) [0|100] "%" GTW
 SG_ TAS2_a227_PWMfrequencyFR m227 : 32|16@1+ (0.025,0) [0|1000] "Hz" GTW
 SG_ TAS2_a227_PWMfaultFR m227 : 48|3@1+ (1,0) [0|6] "" GTW
 SG_ TAS2_a228_PWMdutyCycleRL m228 : 16|16@1+ (0.0025,0) [0|100] "%" GTW
 SG_ TAS2_a228_PWMfrequencyRL m228 : 32|16@1+ (0.025,0) [0|1000] "Hz" GTW
 SG_ TAS2_a228_PWMfaultRL m228 : 48|3@1+ (1,0) [0|6] "" GTW
 SG_ TAS2_a229_PWMdutyCycleRR m229 : 16|16@1+ (0.0025,0) [0|100] "%" GTW
 SG_ TAS2_a229_PWMfrequencyRR m229 : 32|16@1+ (0.025,0) [0|1000] "Hz" GTW
 SG_ TAS2_a229_PWMfaultRR m229 : 48|3@1+ (1,0) [0|6] "" GTW
 SG_ TAS2_a286_inflationCountFL m286 : 16|8@1+ (1,0) [0|255] "times" GTW
 SG_ TAS2_a286_inflationCountFR m286 : 24|8@1+ (1,0) [0|255] "times" GTW
 SG_ TAS2_a286_inflationCountRL m286 : 32|8@1+ (1,0) [0|255] "times" GTW
 SG_ TAS2_a286_inflationCountRR m286 : 40|8@1+ (1,0) [0|255] "times" GTW
 SG_ TAS2_a286_driveCycleLength m286 : 48|16@1+ (1,0) [0|65535] "s" GTW
 SG_ TAS2_a287_deflationCountFL m287 : 16|8@1+ (1,0) [0|255] "times" GTW
 SG_ TAS2_a287_deflationCountFR m287 : 24|8@1+ (1,0) [0|255] "times" GTW
 SG_ TAS2_a287_deflationCountRL m287 : 32|8@1+ (1,0) [0|255] "times" GTW
 SG_ TAS2_a287_deflationCountRR m287 : 40|8@1+ (1,0) [0|255] "times" GTW
 SG_ TAS2_a287_crossPressure m287 : 48|8@1+ (0.05,-6.4) [-6.4|6.35] "bara" GTW
 SG_ TAS2_a288_inflationTimeFL m288 : 16|12@1+ (1,0) [0|4095] "sec" GTW
 SG_ TAS2_a288_inflationTimeFR m288 : 28|12@1+ (1,0) [0|4095] "sec" GTW
 SG_ TAS2_a288_inflationTimeRL m288 : 40|12@1+ (1,0) [0|4095] "sec" GTW
 SG_ TAS2_a288_inflationTimeRR m288 : 52|12@1+ (1,0) [0|4095] "sec" GTW
 SG_ TAS2_a289_deflationTimeFL m289 : 16|12@1+ (1,0) [0|4095] "sec" GTW
 SG_ TAS2_a289_deflationTimeFR m289 : 28|12@1+ (1,0) [0|4095] "sec" GTW
 SG_ TAS2_a289_deflationTimeRL m289 : 40|12@1+ (1,0) [0|4095] "sec" GTW
 SG_ TAS2_a289_deflationTimeRR m289 : 52|12@1+ (1,0) [0|4095] "sec" GTW
 SG_ TAS2_a290_twistLevel m290 : 16|8@1+ (1,-128) [-128|127] "mm" GTW
 SG_ TAS2_a291_frontAxleHeight m291 : 16|8@1+ (1,-128) [-128|127] "mm" GTW
 SG_ TAS2_a292_rearAxleHeight m292 : 16|8@1+ (1,-128) [-128|127] "mm" GTW
 SG_ TAS2_a293_frontAxleHeight m293 : 16|8@1+ (1,-128) [-128|127] "mm" GTW
 SG_ TAS2_a294_rearAxleHeight m294 : 16|8@1+ (1,-128) [-128|127] "mm" GTW
 SG_ TAS2_a295_targetHeight m295 : 16|8@1+ (1,-128) [-128|127] "mm" GTW
 SG_ TAS2_a296_detectedChassisType m296 : 16|2@1+ (1,0) [0|3] "" GTW
 SG_ TAS2_a296_expectedChassisType m296 : 18|2@1+ (1,0) [0|3] "" GTW
 SG_ TAS2_a299_corner m299 : 16|2@1+ (1,0) [0|3] "" GTW
 SG_ TAS2_a299_type m299 : 18|1@1+ (1,0) [0|1] "" GTW
 SG_ TAS2_a299_massEstimate m299 : 19|12@1+ (1,1000) [1000|5095] "kg" GTW
 SG_ TAS2_a299_vehicleSpeed m299 : 32|12@1+ (0.0625,-55) [-55|200] "mph" GTW
 SG_ TAS2_a299_currentRideHeight m299 : 44|3@1+ (1,0) [0|4] "" GTW
 SG_ TAS2_a299_twistDetected m299 : 47|1@1+ (1,0) [0|1] "" GTW
 SG_ TAS2_a300_offsetFL m300 : 16|12@1- (0.001,0) [-2|2] "m" GTW
 SG_ TAS2_a300_offsetFR m300 : 28|12@1- (0.001,0) [-2|2] "m" GTW
 SG_ TAS2_a300_offsetRL m300 : 40|12@1- (0.001,0) [-2|2] "m" GTW
 SG_ TAS2_a300_offsetRR m300 : 52|12@1- (0.001,0) [-2|2] "m" GTW
 SG_ TAS2_a301_steadyStateOffsetFL m301 : 16|12@1- (0.001,0) [-2|2] "m" GTW
 SG_ TAS2_a301_steadyStateOffsetFR m301 : 28|12@1- (0.001,0) [-2|2] "m" GTW
 SG_ TAS2_a301_steadyStateOffsetRL m301 : 40|12@1- (0.001,0) [-2|2] "m" GTW
 SG_ TAS2_a301_steadyStateOffsetRR m301 : 52|12@1- (0.001,0) [-2|2] "m" GTW
 SG_ TAS2_a303_massEstimate m303 : 16|12@1+ (1,1000) [1000|5095] "kg" GTW
 SG_ TAS2_a303_heaveForceFromHeights m303 : 28|12@1- (0.025,0) [-50|50] "kN" GTW
 SG_ TAS2_a303_heaveForceFromDynamics m303 : 40|12@1- (0.025,0) [-50|50] "kN" GTW
 SG_ TAS2_a303_currentRideHeight m303 : 52|3@1+ (1,0) [0|4] "" GTW
 SG_ TAS2_a303_twistDetected m303 : 55|1@1+ (1,0) [0|1] "" GTW
 SG_ TAS2_a304_springForceFL m304 : 16|12@1+ (0.002,2) [2|10] "kN" GTW
 SG_ TAS2_a304_springForceFR m304 : 28|12@1+ (0.002,2) [2|10] "kN" GTW
 SG_ TAS2_a304_springForceRL m304 : 40|12@1+ (0.002,2) [2|10] "kN" GTW
 SG_ TAS2_a304_springForceRR m304 : 52|12@1+ (0.002,2) [2|10] "kN" GTW
 SG_ TAS2_a305_corner m305 : 16|2@1+ (1,0) [0|3] "" GTW
 SG_ TAS2_a305_position m305 : 18|12@1- (0.00075,0) [-1.5|1.5] "m" GTW
 SG_ TAS2_a306_corner m306 : 16|2@1+ (1,0) [0|3] "" GTW
 SG_ TAS2_a306_direction m306 : 18|1@1+ (1,0) [0|1] "" GTW
 SG_ TAS2_a306_currentTarget m306 : 19|12@1+ (0.0005,0) [0|1.8] "A" GTW
 SG_ TAS2_a307_compressionFL m307 : 16|12@1- (0.05,0) [-102.4|102.3] "mm" GTW
 SG_ TAS2_a307_compressionFR m307 : 28|12@1- (0.05,0) [-102.4|102.3] "mm" GTW
 SG_ TAS2_a307_compressionRL m307 : 40|12@1- (0.05,0) [-102.4|102.3] "mm" GTW
 SG_ TAS2_a307_compressionRR m307 : 52|12@1- (0.05,0) [-102.4|102.3] "mm" GTW
 SG_ TAS2_a308_reboundFL m308 : 16|12@1- (0.05,0) [-102.4|102.3] "mm" GTW
 SG_ TAS2_a308_reboundFR m308 : 28|12@1- (0.05,0) [-102.4|102.3] "mm" GTW
 SG_ TAS2_a308_reboundRL m308 : 40|12@1- (0.05,0) [-102.4|102.3] "mm" GTW
 SG_ TAS2_a308_reboundRR m308 : 52|12@1- (0.05,0) [-102.4|102.3] "mm" GTW
 SG_ TAS2_a309_corner m309 : 16|2@1+ (1,0) [0|3] "" GTW
 SG_ TAS2_a309_direction m309 : 18|1@1+ (1,0) [0|1] "" GTW
 SG_ TAS2_a309_currentCommand m309 : 19|12@1+ (0.0005,0) [0|1.8] "A" GTW
 SG_ TAS2_a309_arbitrationBase m309 : 32|12@1+ (0.0005,0) [0|1.8] "A" GTW
 SG_ TAS2_a309_currentRideHeight m309 : 44|3@1+ (1,0) [0|4] "" GTW
 SG_ TAS2_a309_roadCondition m309 : 48|8@1+ (0.005,0) [0|1.275] "-" GTW
 SG_ TAS2_a310_feedForwardLo m310 : 16|12@1+ (0.0005,0) [0|1.8] "A" GTW
 SG_ TAS2_a310_feedBackLo m310 : 28|12@1+ (0.0005,0) [0|1.8] "A" GTW
 SG_ TAS2_a310_modeTransitionHi m310 : 40|12@1+ (0.0005,0) [0|1.8] "A" GTW
 SG_ TAS2_a310_modeTransitionLo m310 : 52|12@1+ (0.0005,0) [0|1.8] "A" GTW
 SG_ TAS2_a315_temperature m315 : 16|8@1+ (1,-40) [-40|125] "C" GTW
 SG_ TAS2_a316_distanceTraveled m316 : 16|8@1+ (5,0) [0|1275] "km" GTW
 SG_ TAS2_a316_offsetAx m316 : 24|9@1- (0.01,0) [-2.56|2.55] "mps2" GTW
 SG_ TAS2_a316_offsetAy m316 : 33|9@1- (0.01,0) [-2.56|2.55] "mps2" GTW
 SG_ TAS2_a316_offsetAz m316 : 42|9@1- (0.01,0) [-2.56|2.55] "mps2" GTW
 SG_ TAS2_a317_offsetRollRate m317 : 16|8@1- (0.01,0) [-0.128|0.127] "rps" GTW
 SG_ TAS2_a317_offsetPitchRate m317 : 24|8@1- (0.01,0) [-0.128|0.127] "rps" GTW
 SG_ TAS2_a317_offsetYawRate m317 : 32|8@1- (0.01,0) [-0.128|0.127] "rps" GTW

BO_ 1292 TAS2_alertMatrix: 8 TAS2
 SG_ TAS2_matrixIndex M : 0|4@1+ (1,0) [0|15] "" GTW
 SG_ TAS2_a001_WatchdogReset m0 : 4|1@1+ (1,0) [0|1] "" GTW
 SG_ TAS2_a002_PowerLossReset m0 : 5|1@1+ (1,0) [0|1] "" GTW
 SG_ TAS2_a003_SWAssertion m0 : 6|1@1+ (1,0) [0|1] "" GTW
 SG_ TAS2_a012_CPUReset m0 : 15|1@1+ (1,0) [0|1] "" GTW
 SG_ TAS2_a015_NVMMAlert m0 : 18|1@1+ (1,0) [0|1] "" GTW
 SG_ TAS2_a021_TaskSchedulerError m0 : 24|1@1+ (1,0) [0|1] "" GTW
 SG_ TAS2_a022_TaskInitError m0 : 25|1@1+ (1,0) [0|1] "" GTW
 SG_ TAS2_a025_CrashEvent m0 : 28|1@1+ (1,0) [0|1] "" GTW
 SG_ TAS2_a030_PWMerrorFL m0 : 33|1@1+ (1,0) [0|1] "" GTW
 SG_ TAS2_a031_PWMerrorFR m0 : 34|1@1+ (1,0) [0|1] "" GTW
 SG_ TAS2_a032_PWMerrorRL m0 : 35|1@1+ (1,0) [0|1] "" GTW
 SG_ TAS2_a033_PWMerrorRR m0 : 36|1@1+ (1,0) [0|1] "" GTW
 SG_ TAS2_a034_PWMshortFL m0 : 37|1@1+ (1,0) [0|1] "" GTW
 SG_ TAS2_a035_PWMshortFR m0 : 38|1@1+ (1,0) [0|1] "" GTW
 SG_ TAS2_a036_PWMshortRL m0 : 39|1@1+ (1,0) [0|1] "" GTW
 SG_ TAS2_a037_PWMshortRR m0 : 40|1@1+ (1,0) [0|1] "" GTW
 SG_ TAS2_a038_PWMopenFL m0 : 41|1@1+ (1,0) [0|1] "" GTW
 SG_ TAS2_a039_PWMopenFR m0 : 42|1@1+ (1,0) [0|1] "" GTW
 SG_ TAS2_a040_PWMopenRL m0 : 43|1@1+ (1,0) [0|1] "" GTW
 SG_ TAS2_a041_PWMopenRR m0 : 44|1@1+ (1,0) [0|1] "" GTW
 SG_ TAS2_a043_Task1msError m0 : 46|1@1+ (1,0) [0|1] "" GTW
 SG_ TAS2_a044_Task10msError m0 : 47|1@1+ (1,0) [0|1] "" GTW
 SG_ TAS2_a045_Task100msError m0 : 48|1@1+ (1,0) [0|1] "" GTW
 SG_ TAS2_a046_Task1000msError m0 : 49|1@1+ (1,0) [0|1] "" GTW
 SG_ TAS2_a061_XCPConnected m1 : 4|1@1+ (1,0) [0|1] "" GTW
 SG_ TAS2_a062_XCPWasConnected m1 : 5|1@1+ (1,0) [0|1] "" GTW
 SG_ TAS2_a070_underVoltage12V m1 : 13|1@1+ (1,0) [0|1] "" GTW
 SG_ TAS2_a071_overVoltage12V m1 : 14|1@1+ (1,0) [0|1] "" GTW
 SG_ TAS2_a072_shortCircuit5VOnBoard m1 : 15|1@1+ (1,0) [0|1] "" GTW
 SG_ TAS2_a073_underVoltage5VOnBoard m1 : 16|1@1+ (1,0) [0|1] "" GTW
 SG_ TAS2_a077_pressureSigVTooLow m1 : 20|1@1+ (1,0) [0|1] "" GTW
 SG_ TAS2_a078_pressureSigVTooHigh m1 : 21|1@1+ (1,0) [0|1] "" GTW
 SG_ TAS2_a080_shortCircuit5VHeight m1 : 23|1@1+ (1,0) [0|1] "" GTW
 SG_ TAS2_a081_underVoltage5VHeight m1 : 24|1@1+ (1,0) [0|1] "" GTW
 SG_ TAS2_a082_overVoltage5VHeight m1 : 25|1@1+ (1,0) [0|1] "" GTW
 SG_ TAS2_a083_shortCircuit5VAnalog m1 : 26|1@1+ (1,0) [0|1] "" GTW
 SG_ TAS2_a084_underVoltage5VAnalog m1 : 27|1@1+ (1,0) [0|1] "" GTW
 SG_ TAS2_a085_overVoltage5VAnalog m1 : 28|1@1+ (1,0) [0|1] "" GTW
 SG_ TAS2_a086_underVoltage12VSwtchd m1 : 29|1@1+ (1,0) [0|1] "" GTW
 SG_ TAS2_a087_overVoltage12VSwtchd m1 : 30|1@1+ (1,0) [0|1] "" GTW
 SG_ TAS2_a093_OTPError m1 : 36|1@1+ (1,0) [0|1] "" GTW
 SG_ TAS2_a094_DAS_MIA m1 : 37|1@1+ (1,0) [0|1] "" GTW
 SG_ TAS2_a095_DIS_MIA m1 : 38|1@1+ (1,0) [0|1] "" GTW
 SG_ TAS2_a096_IMU_MIA m1 : 39|1@1+ (1,0) [0|1] "" GTW
 SG_ TAS2_a097_RCM_MIA m1 : 40|1@1+ (1,0) [0|1] "" GTW
 SG_ TAS2_a098_MCU_MIA m1 : 41|1@1+ (1,0) [0|1] "" GTW
 SG_ TAS2_a099_EFUSE_MIA m1 : 42|1@1+ (1,0) [0|1] "" GTW
 SG_ TAS2_a100_SCCM_MIA m1 : 43|1@1+ (1,0) [0|1] "" GTW
 SG_ TAS2_a101_ESP_MIA m1 : 44|1@1+ (1,0) [0|1] "" GTW
 SG_ TAS2_a102_DI_MIA m1 : 45|1@1+ (1,0) [0|1] "" GTW
 SG_ TAS2_a103_GTW_MIA m1 : 46|1@1+ (1,0) [0|1] "" GTW
 SG_ TAS2_a106_HighCPULoad m1 : 49|1@1+ (1,0) [0|1] "" GTW
 SG_ TAS2_a107_HighStackUsage m1 : 50|1@1+ (1,0) [0|1] "" GTW
 SG_ TAS2_a121_maxDutyFL m2 : 4|1@1+ (1,0) [0|1] "" GTW
 SG_ TAS2_a122_maxDutyFR m2 : 5|1@1+ (1,0) [0|1] "" GTW
 SG_ TAS2_a123_maxDutyRL m2 : 6|1@1+ (1,0) [0|1] "" GTW
 SG_ TAS2_a124_maxDutyRR m2 : 7|1@1+ (1,0) [0|1] "" GTW
 SG_ TAS2_a125_maxDutyReservoir m2 : 8|1@1+ (1,0) [0|1] "" GTW
 SG_ TAS2_a126_maxDutyExhaust m2 : 9|1@1+ (1,0) [0|1] "" GTW
 SG_ TAS2_a127_maxDutyBoost m2 : 10|1@1+ (1,0) [0|1] "" GTW
 SG_ TAS2_a128_maxDutyCompressor m2 : 11|1@1+ (1,0) [0|1] "" GTW
 SG_ TAS2_a129_openCircuitFL m2 : 12|1@1+ (1,0) [0|1] "" GTW
 SG_ TAS2_a130_openCircuitFR m2 : 13|1@1+ (1,0) [0|1] "" GTW
 SG_ TAS2_a131_openCircuitRL m2 : 14|1@1+ (1,0) [0|1] "" GTW
 SG_ TAS2_a132_openCircuitRR m2 : 15|1@1+ (1,0) [0|1] "" GTW
 SG_ TAS2_a133_openCircuitReservoir m2 : 16|1@1+ (1,0) [0|1] "" GTW
 SG_ TAS2_a134_openCircuitExhaust m2 : 17|1@1+ (1,0) [0|1] "" GTW
 SG_ TAS2_a135_openCircuitBoost m2 : 18|1@1+ (1,0) [0|1] "" GTW
 SG_ TAS2_a136_openCircuitCompressor m2 : 19|1@1+ (1,0) [0|1] "" GTW
 SG_ TAS2_a137_shortCircuitFL m2 : 20|1@1+ (1,0) [0|1] "" GTW
 SG_ TAS2_a138_shortCircuitFR m2 : 21|1@1+ (1,0) [0|1] "" GTW
 SG_ TAS2_a139_shortCircuitRL m2 : 22|1@1+ (1,0) [0|1] "" GTW
 SG_ TAS2_a140_shortCircuitRR m2 : 23|1@1+ (1,0) [0|1] "" GTW
 SG_ TAS2_a141_shortCircuitReservoir m2 : 24|1@1+ (1,0) [0|1] "" GTW
 SG_ TAS2_a142_shortCircuitExhaust m2 : 25|1@1+ (1,0) [0|1] "" GTW
 SG_ TAS2_a143_shortCircuitBoost m2 : 26|1@1+ (1,0) [0|1] "" GTW
 SG_ TAS2_a144_shortCircuitCompressor m2 : 27|1@1+ (1,0) [0|1] "" GTW
 SG_ TAS2_a145_boardFaultFL m2 : 28|1@1+ (1,0) [0|1] "" GTW
 SG_ TAS2_a146_boardFaultFR m2 : 29|1@1+ (1,0) [0|1] "" GTW
 SG_ TAS2_a147_boardFaultRL m2 : 30|1@1+ (1,0) [0|1] "" GTW
 SG_ TAS2_a148_boardFaultRR m2 : 31|1@1+ (1,0) [0|1] "" GTW
 SG_ TAS2_a149_boardFaultReservoir m2 : 32|1@1+ (1,0) [0|1] "" GTW
 SG_ TAS2_a150_boardFaultExhaust m2 : 33|1@1+ (1,0) [0|1] "" GTW
 SG_ TAS2_a151_boardFaultBoost m2 : 34|1@1+ (1,0) [0|1] "" GTW
 SG_ TAS2_a152_boardFaultCompressor m2 : 35|1@1+ (1,0) [0|1] "" GTW
 SG_ TAS2_a153_otherCircuitFL m2 : 36|1@1+ (1,0) [0|1] "" GTW
 SG_ TAS2_a154_otherCircuitFR m2 : 37|1@1+ (1,0) [0|1] "" GTW
 SG_ TAS2_a155_otherCircuitRL m2 : 38|1@1+ (1,0) [0|1] "" GTW
 SG_ TAS2_a156_otherCircuitRR m2 : 39|1@1+ (1,0) [0|1] "" GTW
 SG_ TAS2_a157_otherCircuitReservoir m2 : 40|1@1+ (1,0) [0|1] "" GTW
 SG_ TAS2_a158_otherCircuitExhaust m2 : 41|1@1+ (1,0) [0|1] "" GTW
 SG_ TAS2_a159_otherCircuitBoost m2 : 42|1@1+ (1,0) [0|1] "" GTW
 SG_ TAS2_a160_otherCircuitCompressor m2 : 43|1@1+ (1,0) [0|1] "" GTW
 SG_ TAS2_a161_valveBlockOpenGND m2 : 44|1@1+ (1,0) [0|1] "" GTW
 SG_ TAS2_a162_compressorValveOpenGND m2 : 45|1@1+ (1,0) [0|1] "" GTW
 SG_ TAS2_a163_reservoirFillDisabled m2 : 46|1@1+ (1,0) [0|1] "" GTW
 SG_ TAS2_a165_damperValveCompFL m2 : 48|1@1+ (1,0) [0|1] "" GTW
 SG_ TAS2_a166_damperValveRbndFL m2 : 49|1@1+ (1,0) [0|1] "" GTW
 SG_ TAS2_a167_damperValveCompFR m2 : 50|1@1+ (1,0) [0|1] "" GTW
 SG_ TAS2_a168_damperValveRbndFR m2 : 51|1@1+ (1,0) [0|1] "" GTW
 SG_ TAS2_a169_damperValveCompRL m2 : 52|1@1+ (1,0) [0|1] "" GTW
 SG_ TAS2_a170_damperValveRbndRL m2 : 53|1@1+ (1,0) [0|1] "" GTW
 SG_ TAS2_a171_damperValveCompRR m2 : 54|1@1+ (1,0) [0|1] "" GTW
 SG_ TAS2_a172_damperValveRbndRR m2 : 55|1@1+ (1,0) [0|1] "" GTW
 SG_ TAS2_a173_staticLeakDetectFL m2 : 56|1@1+ (1,0) [0|1] "" GTW
 SG_ TAS2_a174_staticLeakDetectFR m2 : 57|1@1+ (1,0) [0|1] "" GTW
 SG_ TAS2_a175_staticLeakDetectRL m2 : 58|1@1+ (1,0) [0|1] "" GTW
 SG_ TAS2_a176_staticLeakDetectRR m2 : 59|1@1+ (1,0) [0|1] "" GTW
 SG_ TAS2_a200_jackModeActive m3 : 23|1@1+ (1,0) [0|1] "" GTW
 SG_ TAS2_a201_lowHVBattery m3 : 24|1@1+ (1,0) [0|1] "" GTW
 SG_ TAS2_a210_outOfRangeCalibration m3 : 33|1@1+ (1,0) [0|1] "" GTW
 SG_ TAS2_a211_noRideHeightCalib m3 : 34|1@1+ (1,0) [0|1] "" GTW
 SG_ TAS2_a213_yellowWarningLamp m3 : 36|1@1+ (1,0) [0|1] "" GTW
 SG_ TAS2_a214_redWarningLamp m3 : 37|1@1+ (1,0) [0|1] "" GTW
 SG_ TAS2_a215_limpHomeMode10 m3 : 38|1@1+ (1,0) [0|1] "" GTW
 SG_ TAS2_a216_limpHomeMode20 m3 : 39|1@1+ (1,0) [0|1] "" GTW
 SG_ TAS2_a217_limpHomeMode30 m3 : 40|1@1+ (1,0) [0|1] "" GTW
 SG_ TAS2_a218_limpHomeMode40 m3 : 41|1@1+ (1,0) [0|1] "" GTW
 SG_ TAS2_a220_exhaustGalleryFault m3 : 43|1@1+ (1,0) [0|1] "" GTW
 SG_ TAS2_a221_valveLeakDetected m3 : 44|1@1+ (1,0) [0|1] "" GTW
 SG_ TAS2_a222_compressorPrefillFault m3 : 45|1@1+ (1,0) [0|1] "" GTW
 SG_ TAS2_a223_blockedAirline m3 : 46|1@1+ (1,0) [0|1] "" GTW
 SG_ TAS2_a224_openAirline m3 : 47|1@1+ (1,0) [0|1] "" GTW
 SG_ TAS2_a225_galleryPressureTooHigh m3 : 48|1@1+ (1,0) [0|1] "" GTW
 SG_ TAS2_a226_PWMfastDetectFL m3 : 49|1@1+ (1,0) [0|1] "" GTW
 SG_ TAS2_a227_PWMfastDetectFR m3 : 50|1@1+ (1,0) [0|1] "" GTW
 SG_ TAS2_a228_PWMfastDetectRL m3 : 51|1@1+ (1,0) [0|1] "" GTW
 SG_ TAS2_a229_PWMfastDetectRR m3 : 52|1@1+ (1,0) [0|1] "" GTW
 SG_ TAS2_a230_geofenceNotification m3 : 53|1@1+ (1,0) [0|1] "" GTW
 SG_ TAS2_a286_driveCycleStats1 m4 : 49|1@1+ (1,0) [0|1] "" GTW
 SG_ TAS2_a287_driveCycleStats2 m4 : 50|1@1+ (1,0) [0|1] "" GTW
 SG_ TAS2_a288_driveCycleStats3 m4 : 51|1@1+ (1,0) [0|1] "" GTW
 SG_ TAS2_a289_driveCycleStats4 m4 : 52|1@1+ (1,0) [0|1] "" GTW
 SG_ TAS2_a290_twistSustainedAtSpeed m4 : 53|1@1+ (1,0) [0|1] "" GTW
 SG_ TAS2_a291_frontAxleTooHigh m4 : 54|1@1+ (1,0) [0|1] "" GTW
 SG_ TAS2_a292_rearAxleTooHigh m4 : 55|1@1+ (1,0) [0|1] "" GTW
 SG_ TAS2_a293_frontAxleTooLow m4 : 56|1@1+ (1,0) [0|1] "" GTW
 SG_ TAS2_a294_rearAxleTooLow m4 : 57|1@1+ (1,0) [0|1] "" GTW
 SG_ TAS2_a295_targetHeightNotMet m4 : 58|1@1+ (1,0) [0|1] "" GTW
 SG_ TAS2_a296_chassisTypeMismatch m4 : 59|1@1+ (1,0) [0|1] "" GTW
 SG_ TAS2_a297_vinMismatch m4 : 60|1@1+ (1,0) [0|1] "" GTW
 SG_ TAS2_a298_vinNotLearned m4 : 61|1@1+ (1,0) [0|1] "" GTW
 SG_ TAS2_a299_offsetEstimateTooLarge m4 : 62|1@1+ (1,0) [0|1] "" GTW
 SG_ TAS2_a300_offsetEstimateData1 m4 : 63|1@1+ (1,0) [0|1] "" GTW
 SG_ TAS2_a301_offsetEstimateData2 m5 : 4|1@1+ (1,0) [0|1] "" GTW
 SG_ TAS2_a303_massEstimateFrozen m5 : 6|1@1+ (1,0) [0|1] "" GTW
 SG_ TAS2_a304_massEstimateFrozenData m5 : 7|1@1+ (1,0) [0|1] "" GTW
 SG_ TAS2_a305_newEndstopPosition m5 : 8|1@1+ (1,0) [0|1] "" GTW
 SG_ TAS2_a306_endstopProtectFrozen m5 : 9|1@1+ (1,0) [0|1] "" GTW
 SG_ TAS2_a307_endstopBoundaryComp m5 : 10|1@1+ (1,0) [0|1] "" GTW
 SG_ TAS2_a308_endstopBoundaryRbnd m5 : 11|1@1+ (1,0) [0|1] "" GTW
 SG_ TAS2_a309_controlFrozen m5 : 12|1@1+ (1,0) [0|1] "" GTW
 SG_ TAS2_a310_controlFrozenData m5 : 13|1@1+ (1,0) [0|1] "" GTW
 SG_ TAS2_a311_accelsMIA m5 : 14|1@1+ (1,0) [0|1] "" GTW
 SG_ TAS2_a312_rotationalRatesMIA m5 : 15|1@1+ (1,0) [0|1] "" GTW
 SG_ TAS2_a313_dampingCntrlDisabled m5 : 16|1@1+ (1,0) [0|1] "" GTW
 SG_ TAS2_a314_dampingReduced m5 : 17|1@1+ (1,0) [0|1] "" GTW
 SG_ TAS2_a315_pcbaHighTemp m5 : 18|1@1+ (1,0) [0|1] "" GTW
 SG_ TAS2_a316_offsetsAccels m5 : 19|1@1+ (1,0) [0|1] "" GTW
 SG_ TAS2_a317_offsetsRotationalRates m5 : 20|1@1+ (1,0) [0|1] "" GTW

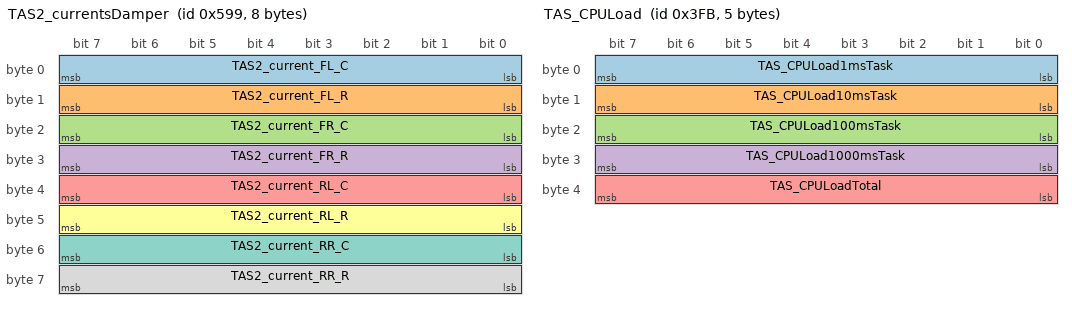
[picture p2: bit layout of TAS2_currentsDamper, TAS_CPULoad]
BO_ 1433 TAS2_currentsDamper: 8 TAS2
 SG_ TAS2_current_FL_C : 0|8@1+ (0.01,0) [0|2.55] "A" Vector__XXX
 SG_ TAS2_current_FL_R : 8|8@1+ (0.01,0) [0|2.55] "A" Vector__XXX
 SG_ TAS2_current_FR_C : 16|8@1+ (0.01,0) [0|2.55] "A" Vector__XXX
 SG_ TAS2_current_FR_R : 24|8@1+ (0.01,0) [0|2.55] "A" Vector__XXX
 SG_ TAS2_current_RL_C : 32|8@1+ (0.01,0) [0|2.55] "A" Vector__XXX
 SG_ TAS2_current_RL_R : 40|8@1+ (0.01,0) [0|2.55] "A" Vector__XXX
 SG_ TAS2_current_RR_C : 48|8@1+ (0.01,0) [0|2.55] "A" Vector__XXX
 SG_ TAS2_current_RR_R : 56|8@1+ (0.01,0) [0|2.55] "A" Vector__XXX

BO_ 1398 TAS2_dampingStates: 7 TAS2
 SG_ TAS2_endstopState : 0|1@1+ (1,0) [0|1] "" GTW
 SG_ TAS2_continuousControlState : 1|1@1+ (1,0) [0|1] "" GTW
 SG_ TAS2_roadCondition : 8|8@1+ (0.005,0) [0|1.275] "-" APP,GTW
 SG_ TAS2_McQueenBoostAxleFront : 16|2@1+ (1,0) [0|3] "" GTW
 SG_ TAS2_McQueenBoostAxleRear : 18|2@1+ (1,0) [0|3] "" GTW
 SG_ TAS2_speedBumpAxleFront : 20|2@1+ (1,0) [0|3] "" APP,GTW
 SG_ TAS2_speedBumpAxleRear : 22|2@1+ (1,0) [0|3] "" GTW
 SG_ TAS2_holeProtectFL : 24|2@1+ (1,0) [0|3] "" APP,GTW
 SG_ TAS2_holeProtectFR : 26|2@1+ (1,0) [0|3] "" APP,GTW
 SG_ TAS2_holeProtectRL : 28|2@1+ (1,0) [0|3] "" GTW
 SG_ TAS2_holeProtectRR : 30|2@1+ (1,0) [0|3] "" GTW
 SG_ TAS2_stepProtectFL : 32|2@1+ (1,0) [0|3] "" APP,GTW
 SG_ TAS2_stepProtectFR : 34|2@1+ (1,0) [0|3] "" APP,GTW
 SG_ TAS2_stepProtectRL : 36|2@1+ (1,0) [0|3] "" GTW
 SG_ TAS2_stepProtectRR : 38|2@1+ (1,0) [0|3] "" GTW
 SG_ TAS2_FDUTorqueCorruptionScale : 40|4@1+ (0.075,0) [0|1.125] "-" GTW
 SG_ TAS2_dampingStatesCounter : 44|4@1+ (1,0) [0|15] "" GTW
 SG_ TAS2_dampingStatesChecksum : 48|8@1+ (1,0) [0|255] "" GTW

BO_ 1019 TAS_CPULoad: 5 TAS
 SG_ TAS_CPULoad1msTask : 0|8@1+ (1,0) [0|255] "" Vector__XXX
 SG_ TAS_CPULoad10msTask : 8|8@1+ (1,0) [0|255] "" Vector__XXX
 SG_ TAS_CPULoad100msTask : 16|8@1+ (1,0) [0|255] "" Vector__XXX
 SG_ TAS_CPULoad1000msTask : 24|8@1+ (1,0) [0|255] "" Vector__XXX
 SG_ TAS_CPULoadTotal : 32|8@1+ (1,0) [0|255] "" Vector__XXX

BO_ 1339 TAS_alertCleared: 2 TAS
 SG_ TAS_alertClearedID : 0|16@1+ (1,0) [0|65535] "" Vector__XXX

BO_ 1291 TAS_alertLog: 8 TAS
 SG_ TAS_alertID M : 0|9@1+ (1,0) [0|295] "" GTW
 SG_ TAS_alertType : 15|1@1+ (1,0) [0|1] "" GTW
 SG_ TAS_a000_alertDataW0 m0 : 16|16@1+ (1,0) [0|65535] "" Vector__XXX
 SG_ TAS_a000_alertDataW1 m0 : 32|16@1+ (1,0) [0|65535] "" Vector__XXX
 SG_ TAS_a000_alertDataW2 m0 : 48|16@1+ (1,0) [0|65535] "" Vector__XXX
 SG_ TAS_a001_InternalWatchdog m1 : 16|1@1+ (1,0) [0|1] "" GTW
 SG_ TAS_a002_CPUUndervoltage m2 : 16|1@1+ (1,0) [0|1] "" GTW
 SG_ TAS_a002_PowerOnReset m2 : 17|1@1+ (1,0) [0|1] "" GTW
 SG_ TAS_a003_AssertID m3 : 16|16@1+ (1,0) [0|65535] "" GTW
 SG_ TAS_a003_LineNumber m3 : 32|16@1+ (1,0) [0|65535] "" GTW
 SG_ TAS_a003_Data m3 : 48|16@1+ (1,0) [0|65535] "" GTW
 SG_ TAS_a012_ClockError m12 : 16|1@1+ (1,0) [0|1] "" GTW
 SG_ TAS_a012_FlashError m12 : 17|1@1+ (1,0) [0|1] "" GTW
 SG_ TAS_a012_SoftwareReset m12 : 18|1@1+ (1,0) [0|1] "" GTW
 SG_ TAS_a012_CheckstopReset m12 : 19|1@1+ (1,0) [0|1] "" GTW
 SG_ TAS_a012_DebugReset m12 : 20|1@1+ (1,0) [0|1] "" GTW
 SG_ TAS_a012_ExternalReset m12 : 21|1@1+ (1,0) [0|1] "" GTW
 SG_ TAS_a015_NVMMRecordNotFound m15 : 16|1@1+ (1,0) [0|1] "" GTW
 SG_ TAS_a015_NVMMCRCMismatch m15 : 17|1@1+ (1,0) [0|1] "" GTW
 SG_ TAS_a015_NVMMVersionMismatch m15 : 18|1@1+ (1,0) [0|1] "" GTW
 SG_ TAS_a015_NVMMRecordUpgraded m15 : 19|1@1+ (1,0) [0|1] "" GTW
 SG_ TAS_a015_NVMMMemOverflow m15 : 20|1@1+ (1,0) [0|1] "" GTW
 SG_ TAS_a015_NVMMWriteFailed m15 : 21|1@1+ (1,0) [0|1] "" GTW
 SG_ TAS_a021_Task1msLate m21 : 16|1@1+ (1,0) [0|1] "" GTW
 SG_ TAS_a021_Task1msStarved m21 : 17|1@1+ (1,0) [0|1] "" GTW
 SG_ TAS_a021_Task1msMissed m21 : 18|1@1+ (1,0) [0|1] "" GTW
 SG_ TAS_a021_Task10msLate m21 : 19|1@1+ (1,0) [0|1] "" GTW
 SG_ TAS_a021_Task10msStarved m21 : 20|1@1+ (1,0) [0|1] "" GTW
 SG_ TAS_a021_Task10msMissed m21 : 21|1@1+ (1,0) [0|1] "" GTW
 SG_ TAS_a021_Task100msLate m21 : 22|1@1+ (1,0) [0|1] "" GTW
 SG_ TAS_a021_Task100msStarved m21 : 23|1@1+ (1,0) [0|1] "" GTW
 SG_ TAS_a021_Task100msMissed m21 : 24|1@1+ (1,0) [0|1] "" GTW
 SG_ TAS_a021_Task1000msLate m21 : 25|1@1+ (1,0) [0|1] "" GTW
 SG_ TAS_a021_Task1000msStarved m21 : 26|1@1+ (1,0) [0|1] "" GTW
 SG_ TAS_a021_Task1000msMissed m21 : 27|1@1+ (1,0) [0|1] "" GTW
 SG_ TAS_a022_TaskInitErrorCount m22 : 16|8@1+ (1,0) [0|255] "" GTW
 SG_ TAS_a022_TaskInitError0 m22 : 24|8@1+ (1,0) [0|255] "" GTW
 SG_ TAS_a022_TaskInitError1 m22 : 32|8@1+ (1,0) [0|255] "" GTW
 SG_ TAS_a022_TaskInitError2 m22 : 40|8@1+ (1,0) [0|255] "" GTW
 SG_ TAS_a022_TaskInitError3 m22 : 48|8@1+ (1,0) [0|255] "" GTW
 SG_ TAS_a022_TaskInitError4 m22 : 56|8@1+ (1,0) [0|255] "" GTW
 SG_ TAS_a025_vehicleLockAtCrash m25 : 16|1@1+ (1,0) [0|1] "" GTW
 SG_ TAS_a025_CANCrashIsActive m25 : 17|1@1+ (1,0) [0|1] "" GTW
 SG_ TAS_a025_appCrashIsActive m25 : 18|1@1+ (1,0) [0|1] "" GTW
 SG_ TAS_a025_lastCrashEvent m25 : 24|32@1+ (1,0) [0|4294967295] "" GTW
 SG_ TAS_a030_PWMdutyCycleFL m30 : 16|16@1+ (0.0025,0) [0|100] "%" GTW
 SG_ TAS_a030_PWMfrequencyFL m30 : 32|16@1+ (0.025,0) [0|1000] "Hz" GTW
 SG_ TAS_a030_PWMfaultFL m30 : 48|3@1+ (1,0) [0|6] "" GTW
 SG_ TAS_a031_PWMdutyCycleFR m31 : 16|16@1+ (0.0025,0) [0|100] "%" GTW
 SG_ TAS_a031_PWMfrequencyFR m31 : 32|16@1+ (0.025,0) [0|1000] "Hz" GTW
 SG_ TAS_a031_PWMfaultFR m31 : 48|3@1+ (1,0) [0|6] "" GTW
 SG_ TAS_a032_PWMdutyCycleRL m32 : 16|16@1+ (0.0025,0) [0|100] "%" GTW
 SG_ TAS_a032_PWMfrequencyRL m32 : 32|16@1+ (0.025,0) [0|1000] "Hz" GTW
 SG_ TAS_a032_PWMfaultRL m32 : 48|3@1+ (1,0) [0|6] "" GTW
 SG_ TAS_a033_PWMdutyCycleRR m33 : 16|16@1+ (0.0025,0) [0|100] "%" GTW
 SG_ TAS_a033_PWMfrequencyRR m33 : 32|16@1+ (0.025,0) [0|1000] "Hz" GTW
 SG_ TAS_a033_PWMfaultRR m33 : 48|3@1+ (1,0) [0|6] "" GTW
 SG_ TAS_a034_PWMdutyCycleFL m34 : 16|16@1+ (0.0025,0) [0|100] "%" GTW
 SG_ TAS_a034_PWMfrequencyFL m34 : 32|16@1+ (0.025,0) [0|1000] "Hz" GTW
 SG_ TAS_a034_PWMfaultFL m34 : 48|3@1+ (1,0) [0|6] "" GTW
 SG_ TAS_a035_PWMdutyCycleFR m35 : 16|16@1+ (0.0025,0) [0|100] "%" GTW
 SG_ TAS_a035_PWMfrequencyFR m35 : 32|16@1+ (0.025,0) [0|1000] "Hz" GTW
 SG_ TAS_a035_PWMfaultFR m35 : 48|3@1+ (1,0) [0|6] "" GTW
 SG_ TAS_a036_PWMdutyCycleRL m36 : 16|16@1+ (0.0025,0) [0|100] "%" GTW
 SG_ TAS_a036_PWMfrequencyRL m36 : 32|16@1+ (0.025,0) [0|1000] "Hz" GTW
 SG_ TAS_a036_PWMfaultRL m36 : 48|3@1+ (1,0) [0|6] "" GTW
 SG_ TAS_a037_PWMdutyCycleRR m37 : 16|16@1+ (0.0025,0) [0|100] "%" GTW
 SG_ TAS_a037_PWMfrequencyRR m37 : 32|16@1+ (0.025,0) [0|1000] "Hz" GTW
 SG_ TAS_a037_PWMfaultRR m37 : 48|3@1+ (1,0) [0|6] "" GTW
 SG_ TAS_a038_PWMdutyCycleFL m38 : 16|16@1+ (0.0025,0) [0|100] "%" GTW
 SG_ TAS_a038_PWMfrequencyFL m38 : 32|16@1+ (0.025,0) [0|1000] "Hz" GTW
 SG_ TAS_a038_PWMfaultFL m38 : 48|3@1+ (1,0) [0|6] "" GTW
 SG_ TAS_a039_PWMdutyCycleFR m39 : 16|16@1+ (0.0025,0) [0|100] "%" GTW
 SG_ TAS_a039_PWMfrequencyFR m39 : 32|16@1+ (0.025,0) [0|1000] "Hz" GTW
 SG_ TAS_a039_PWMfaultFR m39 : 48|3@1+ (1,0) [0|6] "" GTW
 SG_ TAS_a040_PWMdutyCycleRL m40 : 16|16@1+ (0.0025,0) [0|100] "%" GTW
 SG_ TAS_a040_PWMfrequencyRL m40 : 32|16@1+ (0.025,0) [0|1000] "Hz" GTW
 SG_ TAS_a040_PWMfaultRL m40 : 48|3@1+ (1,0) [0|6] "" GTW
 SG_ TAS_a041_PWMdutyCycleRR m41 : 16|16@1+ (0.0025,0) [0|100] "%" GTW
 SG_ TAS_a041_PWMfrequencyRR m41 : 32|16@1+ (0.025,0) [0|1000] "Hz" GTW
 SG_ TAS_a041_PWMfaultRR m41 : 48|3@1+ (1,0) [0|6] "" GTW
 SG_ TAS_a043_CallTrace0 m43 : 16|24@1+ (1,0) [0|16777215] "" GTW
 SG_ TAS_a043_CallTrace1 m43 : 40|24@1+ (1,0) [0|16777215] "" GTW
 SG_ TAS_a044_CallTrace0 m44 : 16|24@1+ (1,0) [0|16777215] "" GTW
 SG_ TAS_a044_CallTrace1 m44 : 40|24@1+ (1,0) [0|16777215] "" GTW
 SG_ TAS_a045_CallTrace0 m45 : 16|24@1+ (1,0) [0|16777215] "" GTW
 SG_ TAS_a045_CallTrace1 m45 : 40|24@1+ (1,0) [0|16777215] "" GTW
 SG_ TAS_a046_CallTrace0 m46 : 16|24@1+ (1,0) [0|16777215] "" GTW
 SG_ TAS_a046_CallTrace1 m46 : 40|24@1+ (1,0) [0|16777215] "" GTW
 SG_ TAS_a070_voltage12V m70 : 16|16@1+ (0.001,0) [0|32] "V" GTW
 SG_ TAS_a071_voltage12V m71 : 16|16@1+ (0.001,0) [0|32] "V" GTW
 SG_ TAS_a072_voltage5VOnBoard m72 : 16|16@1+ (0.001,0) [0|32] "V" GTW
 SG_ TAS_a073_voltage5VOnBoard m73 : 16|16@1+ (0.001,0) [0|32] "V" GTW
 SG_ TAS_a074_voltage5VOffBoard m74 : 16|16@1+ (0.001,0) [0|32] "V" GTW
 SG_ TAS_a075_voltage5VOffBoard m75 : 16|16@1+ (0.001,0) [0|32] "V" GTW
 SG_ TAS_a076_voltage5VOffBoard m76 : 16|16@1+ (0.001,0) [0|32] "V" GTW
 SG_ TAS_a077_sensorVoltage m77 : 16|16@1+ (0.001,0) [0|32] "V" GTW
 SG_ TAS_a077_sensorRefVoltage m77 : 32|16@1+ (0.001,0) [0|32] "V" GTW
 SG_ TAS_a078_sensorVoltage m78 : 16|16@1+ (0.001,0) [0|32] "V" GTW
 SG_ TAS_a078_sensorRefVoltage m78 : 32|16@1+ (0.001,0) [0|32] "V" GTW
 SG_ TAS_a093_readError m93 : 16|1@1+ (1,0) [0|1] "" GTW
 SG_ TAS_a093_IVOR2Exception m93 : 17|1@1+ (1,0) [0|1] "" GTW
 SG_ TAS_a098_MCU_chassisControl_MIA m98 : 16|1@1+ (1,0) [0|1] "" GTW
 SG_ TAS_a098_MCU_utcTime_MIA m98 : 17|1@1+ (1,0) [0|1] "" GTW
 SG_ TAS_a098_UI_drvrAsstMapData_MIA m98 : 18|1@1+ (1,0) [0|1] "" GTW
 SG_ TAS_a098_UI_suspControl_MIA m98 : 19|1@1+ (1,0) [0|1] "" GTW
 SG_ TAS_a099_EFUSE_status_MIA m99 : 16|1@1+ (1,0) [0|1] "" GTW
 SG_ TAS_a100_STW_ANGLHP_STAT_MIA m100 : 16|1@1+ (1,0) [0|1] "" GTW
 SG_ TAS_a101_ESP_145h_MIA m101 : 16|1@1+ (1,0) [0|1] "" GTW
 SG_ TAS_a101_ESP_B_MIA m101 : 17|1@1+ (1,0) [0|1] "" GTW
 SG_ TAS_a102_DI_state_MIA m102 : 16|1@1+ (1,0) [0|1] "" GTW
 SG_ TAS_a102_DI_torque2_MIA m102 : 17|1@1+ (1,0) [0|1] "" GTW
 SG_ TAS_a103_GTW_ESP1_MIA m103 : 16|1@1+ (1,0) [0|1] "" GTW
 SG_ TAS_a103_GTW_carConfig_MIA m103 : 17|1@1+ (1,0) [0|1] "" GTW
 SG_ TAS_a103_GTW_carState_MIA m103 : 18|1@1+ (1,0) [0|1] "" GTW
 SG_ TAS_a103_GTW_chNm_MIA m103 : 19|1@1+ (1,0) [0|1] "" GTW
 SG_ TAS_a103_GTW_odo_MIA m103 : 20|1@1+ (1,0) [0|1] "" GTW
 SG_ TAS_a103_GTW_status_MIA m103 : 21|1@1+ (1,0) [0|1] "" GTW
 SG_ TAS_a106_CPULoadTotal m106 : 16|8@1+ (1,0) [0|255] "" GTW
 SG_ TAS_a106_CPULoad1msTask m106 : 24|8@1+ (1,0) [0|255] "" GTW
 SG_ TAS_a106_CPULoad10msTask m106 : 32|8@1+ (1,0) [0|255] "" GTW
 SG_ TAS_a106_CPULoad100msTask m106 : 40|8@1+ (1,0) [0|255] "" GTW
 SG_ TAS_a106_CPULoad1000msTask m106 : 48|8@1+ (1,0) [0|255] "" GTW
 SG_ TAS_a106_CPULoadNVMMTask m106 : 56|8@1+ (1,0) [0|255] "" GTW
 SG_ TAS_a107_Usage1msTask m107 : 16|8@1+ (1,0) [0|255] "" GTW
 SG_ TAS_a107_Usage10msTask m107 : 24|8@1+ (1,0) [0|255] "" GTW
 SG_ TAS_a107_Usage100msTask m107 : 32|8@1+ (1,0) [0|255] "" GTW
 SG_ TAS_a107_Usage1000msTask m107 : 40|8@1+ (1,0) [0|255] "" GTW
 SG_ TAS_a107_UsageUDSTask m107 : 48|8@1+ (1,0) [0|255] "" GTW
 SG_ TAS_a107_UsageNVMMTask m107 : 56|8@1+ (1,0) [0|255] "" GTW
 SG_ TAS_a121_dutyCycleFL m121 : 16|8@1+ (1,0) [0|100] "%" GTW
 SG_ TAS_a121_ambientTemperature m121 : 24|8@1+ (1,-40) [-40|215] "degC" GTW
 SG_ TAS_a121_12VtoValve m121 : 32|16@1+ (0.001,0) [0|32] "V" GTW
 SG_ TAS_a122_dutyCycleFR m122 : 16|8@1+ (1,0) [0|100] "%" GTW
 SG_ TAS_a122_ambientTemperature m122 : 24|8@1+ (1,-40) [-40|215] "degC" GTW
 SG_ TAS_a122_12VtoValve m122 : 32|16@1+ (0.001,0) [0|32] "V" GTW
 SG_ TAS_a123_dutyCycleRL m123 : 16|8@1+ (1,0) [0|100] "%" GTW
 SG_ TAS_a123_ambientTemperature m123 : 24|8@1+ (1,-40) [-40|215] "degC" GTW
 SG_ TAS_a123_12VtoValve m123 : 32|16@1+ (0.001,0) [0|32] "V" GTW
 SG_ TAS_a124_dutyCycleRR m124 : 16|8@1+ (1,0) [0|100] "%" GTW
 SG_ TAS_a124_ambientTemperature m124 : 24|8@1+ (1,-40) [-40|215] "degC" GTW
 SG_ TAS_a124_12VtoValve m124 : 32|16@1+ (0.001,0) [0|32] "V" GTW
 SG_ TAS_a125_dutyCycleReservoir m125 : 16|8@1+ (1,0) [0|100] "%" GTW
 SG_ TAS_a125_ambientTemperature m125 : 24|8@1+ (1,-40) [-40|215] "degC" GTW
 SG_ TAS_a125_12VtoValve m125 : 32|16@1+ (0.001,0) [0|32] "V" GTW
 SG_ TAS_a126_dutyCycleExhaust m126 : 16|8@1+ (1,0) [0|100] "%" GTW
 SG_ TAS_a126_ambientTemperature m126 : 24|8@1+ (1,-40) [-40|215] "degC" GTW
 SG_ TAS_a126_12VtoValve m126 : 32|16@1+ (0.001,0) [0|32] "V" GTW
 SG_ TAS_a127_dutyCycleBoost m127 : 16|8@1+ (1,0) [0|100] "%" GTW
 SG_ TAS_a127_ambientTemperature m127 : 24|8@1+ (1,-40) [-40|215] "degC" GTW
 SG_ TAS_a127_12VtoValve m127 : 32|16@1+ (0.001,0) [0|32] "V" GTW
 SG_ TAS_a128_dutyCycleCompressor m128 : 16|8@1+ (1,0) [0|100] "%" GTW
 SG_ TAS_a128_ambientTemperature m128 : 24|8@1+ (1,-40) [-40|215] "degC" GTW
 SG_ TAS_a128_12VtoValve m128 : 32|16@1+ (0.001,0) [0|32] "V" GTW
 SG_ TAS_a129_valveFaultType m129 : 16|3@1+ (1,0) [0|7] "" GTW
 SG_ TAS_a129_valveVoltage m129 : 24|16@1+ (0.001,0) [0|32] "V" GTW
 SG_ TAS_a129_valveCurrent m129 : 40|16@1+ (0.001,0) [0|32] "A" GTW
 SG_ TAS_a130_valveFaultType m130 : 16|3@1+ (1,0) [0|7] "" GTW
 SG_ TAS_a130_valveVoltage m130 : 24|16@1+ (0.001,0) [0|32] "V" GTW
 SG_ TAS_a130_valveCurrent m130 : 40|16@1+ (0.001,0) [0|32] "A" GTW
 SG_ TAS_a131_valveFaultType m131 : 16|3@1+ (1,0) [0|7] "" GTW
 SG_ TAS_a131_valveVoltage m131 : 24|16@1+ (0.001,0) [0|32] "V" GTW
 SG_ TAS_a131_valveCurrent m131 : 40|16@1+ (0.001,0) [0|32] "A" GTW
 SG_ TAS_a132_valveFaultType m132 : 16|3@1+ (1,0) [0|7] "" GTW
 SG_ TAS_a132_valveVoltage m132 : 24|16@1+ (0.001,0) [0|32] "V" GTW
 SG_ TAS_a132_valveCurrent m132 : 40|16@1+ (0.001,0) [0|32] "A" GTW
 SG_ TAS_a133_valveFaultType m133 : 16|3@1+ (1,0) [0|7] "" GTW
 SG_ TAS_a133_valveVoltage m133 : 24|16@1+ (0.001,0) [0|32] "V" GTW
 SG_ TAS_a133_valveCurrent m133 : 40|16@1+ (0.001,0) [0|32] "A" GTW
 SG_ TAS_a134_valveFaultType m134 : 16|3@1+ (1,0) [0|7] "" GTW
 SG_ TAS_a134_valveVoltage m134 : 24|16@1+ (0.001,0) [0|32] "V" GTW
 SG_ TAS_a134_valveCurrent m134 : 40|16@1+ (0.001,0) [0|32] "A" GTW
 SG_ TAS_a135_valveFaultType m135 : 16|3@1+ (1,0) [0|7] "" GTW
 SG_ TAS_a135_valveVoltage m135 : 24|16@1+ (0.001,0) [0|32] "V" GTW
 SG_ TAS_a135_valveCurrent m135 : 40|16@1+ (0.001,0) [0|32] "A" GTW
 SG_ TAS_a136_valveFaultType m136 : 16|3@1+ (1,0) [0|7] "" GTW
 SG_ TAS_a136_valveVoltage m136 : 24|16@1+ (0.001,0) [0|32] "V" GTW
 SG_ TAS_a136_valveCurrent m136 : 40|16@1+ (0.001,0) [0|32] "A" GTW
 SG_ TAS_a137_valveFaultType m137 : 16|3@1+ (1,0) [0|7] "" GTW
 SG_ TAS_a137_valveVoltage m137 : 24|16@1+ (0.001,0) [0|32] "V" GTW
 SG_ TAS_a137_valveCurrent m137 : 40|16@1+ (0.001,0) [0|32] "A" GTW
 SG_ TAS_a138_valveFaultType m138 : 16|3@1+ (1,0) [0|7] "" GTW
 SG_ TAS_a138_valveVoltage m138 : 24|16@1+ (0.001,0) [0|32] "V" GTW
 SG_ TAS_a138_valveCurrent m138 : 40|16@1+ (0.001,0) [0|32] "A" GTW
 SG_ TAS_a139_valveFaultType m139 : 16|3@1+ (1,0) [0|7] "" GTW
 SG_ TAS_a139_valveVoltage m139 : 24|16@1+ (0.001,0) [0|32] "V" GTW
 SG_ TAS_a139_valveCurrent m139 : 40|16@1+ (0.001,0) [0|32] "A" GTW
 SG_ TAS_a140_valveFaultType m140 : 16|3@1+ (1,0) [0|7] "" GTW
 SG_ TAS_a140_valveVoltage m140 : 24|16@1+ (0.001,0) [0|32] "V" GTW
 SG_ TAS_a140_valveCurrent m140 : 40|16@1+ (0.001,0) [0|32] "A" GTW
 SG_ TAS_a141_valveFaultType m141 : 16|3@1+ (1,0) [0|7] "" GTW
 SG_ TAS_a141_valveVoltage m141 : 24|16@1+ (0.001,0) [0|32] "V" GTW
 SG_ TAS_a141_valveCurrent m141 : 40|16@1+ (0.001,0) [0|32] "A" GTW
 SG_ TAS_a142_valveFaultType m142 : 16|3@1+ (1,0) [0|7] "" GTW
 SG_ TAS_a142_valveVoltage m142 : 24|16@1+ (0.001,0) [0|32] "V" GTW
 SG_ TAS_a142_valveCurrent m142 : 40|16@1+ (0.001,0) [0|32] "A" GTW
 SG_ TAS_a143_valveFaultType m143 : 16|3@1+ (1,0) [0|7] "" GTW
 SG_ TAS_a143_valveVoltage m143 : 24|16@1+ (0.001,0) [0|32] "V" GTW
 SG_ TAS_a143_valveCurrent m143 : 40|16@1+ (0.001,0) [0|32] "A" GTW
 SG_ TAS_a144_valveFaultType m144 : 16|3@1+ (1,0) [0|7] "" GTW
 SG_ TAS_a144_valveVoltage m144 : 24|16@1+ (0.001,0) [0|32] "V" GTW
 SG_ TAS_a144_valveCurrent m144 : 40|16@1+ (0.001,0) [0|32] "A" GTW
 SG_ TAS_a145_valveFaultType m145 : 16|3@1+ (1,0) [0|7] "" GTW
 SG_ TAS_a145_valveVoltage m145 : 24|16@1+ (0.001,0) [0|32] "V" GTW
 SG_ TAS_a145_valveCurrent m145 : 40|16@1+ (0.001,0) [0|32] "A" GTW
 SG_ TAS_a146_valveFaultType m146 : 16|3@1+ (1,0) [0|7] "" GTW
 SG_ TAS_a146_valveVoltage m146 : 24|16@1+ (0.001,0) [0|32] "V" GTW
 SG_ TAS_a146_valveCurrent m146 : 40|16@1+ (0.001,0) [0|32] "A" GTW
 SG_ TAS_a147_valveFaultType m147 : 16|3@1+ (1,0) [0|7] "" GTW
 SG_ TAS_a147_valveVoltage m147 : 24|16@1+ (0.001,0) [0|32] "V" GTW
 SG_ TAS_a147_valveCurrent m147 : 40|16@1+ (0.001,0) [0|32] "A" GTW
 SG_ TAS_a148_valveFaultType m148 : 16|3@1+ (1,0) [0|7] "" GTW
 SG_ TAS_a148_valveVoltage m148 : 24|16@1+ (0.001,0) [0|32] "V" GTW
 SG_ TAS_a148_valveCurrent m148 : 40|16@1+ (0.001,0) [0|32] "A" GTW
 SG_ TAS_a149_valveFaultType m149 : 16|3@1+ (1,0) [0|7] "" GTW
 SG_ TAS_a149_valveVoltage m149 : 24|16@1+ (0.001,0) [0|32] "V" GTW
 SG_ TAS_a149_valveCurrent m149 : 40|16@1+ (0.001,0) [0|32] "A" GTW
 SG_ TAS_a150_valveFaultType m150 : 16|3@1+ (1,0) [0|7] "" GTW
 SG_ TAS_a150_valveVoltage m150 : 24|16@1+ (0.001,0) [0|32] "V" GTW
 SG_ TAS_a150_valveCurrent m150 : 40|16@1+ (0.001,0) [0|32] "A" GTW
 SG_ TAS_a151_valveFaultType m151 : 16|3@1+ (1,0) [0|7] "" GTW
 SG_ TAS_a151_valveVoltage m151 : 24|16@1+ (0.001,0) [0|32] "V" GTW
 SG_ TAS_a151_valveCurrent m151 : 40|16@1+ (0.001,0) [0|32] "A" GTW
 SG_ TAS_a152_valveFaultType m152 : 16|3@1+ (1,0) [0|7] "" GTW
 SG_ TAS_a152_valveVoltage m152 : 24|16@1+ (0.001,0) [0|32] "V" GTW
 SG_ TAS_a152_valveCurrent m152 : 40|16@1+ (0.001,0) [0|32] "A" GTW
 SG_ TAS_a153_valveFaultType m153 : 16|3@1+ (1,0) [0|7] "" GTW
 SG_ TAS_a153_valveVoltage m153 : 24|16@1+ (0.001,0) [0|32] "V" GTW
 SG_ TAS_a153_valveCurrent m153 : 40|16@1+ (0.001,0) [0|32] "A" GTW
 SG_ TAS_a154_valveFaultType m154 : 16|3@1+ (1,0) [0|7] "" GTW
 SG_ TAS_a154_valveVoltage m154 : 24|16@1+ (0.001,0) [0|32] "V" GTW
 SG_ TAS_a154_valveCurrent m154 : 40|16@1+ (0.001,0) [0|32] "A" GTW
 SG_ TAS_a155_valveFaultType m155 : 16|3@1+ (1,0) [0|7] "" GTW
 SG_ TAS_a155_valveVoltage m155 : 24|16@1+ (0.001,0) [0|32] "V" GTW
 SG_ TAS_a155_valveCurrent m155 : 40|16@1+ (0.001,0) [0|32] "A" GTW
 SG_ TAS_a156_valveFaultType m156 : 16|3@1+ (1,0) [0|7] "" GTW
 SG_ TAS_a156_valveVoltage m156 : 24|16@1+ (0.001,0) [0|32] "V" GTW
 SG_ TAS_a156_valveCurrent m156 : 40|16@1+ (0.001,0) [0|32] "A" GTW
 SG_ TAS_a157_valveFaultType m157 : 16|3@1+ (1,0) [0|7] "" GTW
 SG_ TAS_a157_valveVoltage m157 : 24|16@1+ (0.001,0) [0|32] "V" GTW
 SG_ TAS_a157_valveCurrent m157 : 40|16@1+ (0.001,0) [0|32] "A" GTW
 SG_ TAS_a158_valveFaultType m158 : 16|3@1+ (1,0) [0|7] "" GTW
 SG_ TAS_a158_valveVoltage m158 : 24|16@1+ (0.001,0) [0|32] "V" GTW
 SG_ TAS_a158_valveCurrent m158 : 40|16@1+ (0.001,0) [0|32] "A" GTW
 SG_ TAS_a159_valveFaultType m159 : 16|3@1+ (1,0) [0|7] "" GTW
 SG_ TAS_a159_valveVoltage m159 : 24|16@1+ (0.001,0) [0|32] "V" GTW
 SG_ TAS_a159_valveCurrent m159 : 40|16@1+ (0.001,0) [0|32] "A" GTW
 SG_ TAS_a160_valveFaultType m160 : 16|3@1+ (1,0) [0|7] "" GTW
 SG_ TAS_a160_valveVoltage m160 : 24|16@1+ (0.001,0) [0|32] "V" GTW
 SG_ TAS_a160_valveCurrent m160 : 40|16@1+ (0.001,0) [0|32] "A" GTW
 SG_ TAS_a173_heightDelta_mm m173 : 16|8@1+ (1,-128) [-128|127] "mm" GTW
 SG_ TAS_a174_heightDelta_mm m174 : 16|8@1+ (1,-128) [-128|127] "mm" GTW
 SG_ TAS_a175_heightDelta_mm m175 : 16|8@1+ (1,-128) [-128|127] "mm" GTW
 SG_ TAS_a176_heightDelta_mm m176 : 16|8@1+ (1,-128) [-128|127] "mm" GTW
 SG_ TAS_a210_heightSensorDeltaFL m210 : 16|8@1+ (1,-128) [-128|127] "mm" GTW
 SG_ TAS_a210_heightSensorDeltaFR m210 : 24|8@1+ (1,-128) [-128|127] "mm" GTW
 SG_ TAS_a210_heightSensorDeltaRL m210 : 32|8@1+ (1,-128) [-128|127] "mm" GTW
 SG_ TAS_a210_heightSensorDeltaRR m210 : 40|8@1+ (1,-128) [-128|127] "mm" GTW
 SG_ TAS_a220_galleryPressure m220 : 16|8@1+ (0.1,0) [0|25.5] "bara" GTW
 SG_ TAS_a221_galleryPressureDelta m221 : 16|8@1+ (0.1,0) [0|25.5] "bar" GTW
 SG_ TAS_a221_timeInIdle m221 : 24|32@1+ (1,0) [0|4294967295] "" GTW
 SG_ TAS_a222_galleryPressureDelta m222 : 16|8@1+ (0.1,0) [0|25.5] "bar" GTW
 SG_ TAS_a223_galleryPressure m223 : 16|8@1+ (0.1,0) [0|25.5] "bara" GTW
 SG_ TAS_a223_valveOnFL m223 : 24|1@1+ (1,0) [0|1] "" GTW
 SG_ TAS_a223_valveOnFR m223 : 25|1@1+ (1,0) [0|1] "" GTW
 SG_ TAS_a223_valveOnRL m223 : 26|1@1+ (1,0) [0|1] "" GTW
 SG_ TAS_a223_valveOnRR m223 : 27|1@1+ (1,0) [0|1] "" GTW
 SG_ TAS_a223_valveOnReservoir m223 : 28|1@1+ (1,0) [0|1] "" GTW
 SG_ TAS_a224_galleryPressure m224 : 16|8@1+ (0.1,0) [0|25.5] "bara" GTW
 SG_ TAS_a224_valveOnFL m224 : 24|1@1+ (1,0) [0|1] "" GTW
 SG_ TAS_a224_valveOnFR m224 : 25|1@1+ (1,0) [0|1] "" GTW
 SG_ TAS_a224_valveOnRL m224 : 26|1@1+ (1,0) [0|1] "" GTW
 SG_ TAS_a224_valveOnRR m224 : 27|1@1+ (1,0) [0|1] "" GTW
 SG_ TAS_a224_valveOnReservoir m224 : 28|1@1+ (1,0) [0|1] "" GTW
 SG_ TAS_a225_galleryPressure m225 : 16|8@1+ (0.1,0) [0|25.5] "bara" GTW
 SG_ TAS_a226_PWMdutyCycleFL m226 : 16|16@1+ (0.0025,0) [0|100] "%" GTW
 SG_ TAS_a226_PWMfrequencyFL m226 : 32|16@1+ (0.025,0) [0|1000] "Hz" GTW
 SG_ TAS_a226_PWMfaultFL m226 : 48|3@1+ (1,0) [0|6] "" GTW
 SG_ TAS_a227_PWMdutyCycleFR m227 : 16|16@1+ (0.0025,0) [0|100] "%" GTW
 SG_ TAS_a227_PWMfrequencyFR m227 : 32|16@1+ (0.025,0) [0|1000] "Hz" GTW
 SG_ TAS_a227_PWMfaultFR m227 : 48|3@1+ (1,0) [0|6] "" GTW
 SG_ TAS_a228_PWMdutyCycleRL m228 : 16|16@1+ (0.0025,0) [0|100] "%" GTW
 SG_ TAS_a228_PWMfrequencyRL m228 : 32|16@1+ (0.025,0) [0|1000] "Hz" GTW
 SG_ TAS_a228_PWMfaultRL m228 : 48|3@1+ (1,0) [0|6] "" GTW
 SG_ TAS_a229_PWMdutyCycleRR m229 : 16|16@1+ (0.0025,0) [0|100] "%" GTW
 SG_ TAS_a229_PWMfrequencyRR m229 : 32|16@1+ (0.025,0) [0|1000] "Hz" GTW
 SG_ TAS_a229_PWMfaultRR m229 : 48|3@1+ (1,0) [0|6] "" GTW
 SG_ TAS_a286_inflationCountFL m286 : 16|8@1+ (1,0) [0|255] "times" GTW
 SG_ TAS_a286_inflationCountFR m286 : 24|8@1+ (1,0) [0|255] "times" GTW
 SG_ TAS_a286_inflationCountRL m286 : 32|8@1+ (1,0) [0|255] "times" GTW
 SG_ TAS_a286_inflationCountRR m286 : 40|8@1+ (1,0) [0|255] "times" GTW
 SG_ TAS_a286_driveCycleLength m286 : 48|16@1+ (1,0) [0|65535] "s" GTW
 SG_ TAS_a287_deflationCountFL m287 : 16|8@1+ (1,0) [0|255] "times" GTW
 SG_ TAS_a287_deflationCountFR m287 : 24|8@1+ (1,0) [0|255] "times" GTW
 SG_ TAS_a287_deflationCountRL m287 : 32|8@1+ (1,0) [0|255] "times" GTW
 SG_ TAS_a287_deflationCountRR m287 : 40|8@1+ (1,0) [0|255] "times" GTW
 SG_ TAS_a287_crossPressure m287 : 48|8@1+ (0.05,-6.4) [-6.4|6.35] "bara" GTW
 SG_ TAS_a288_inflationTimeFL m288 : 16|12@1+ (1,0) [0|4095] "sec" GTW
 SG_ TAS_a288_inflationTimeFR m288 : 28|12@1+ (1,0) [0|4095] "sec" GTW
 SG_ TAS_a288_inflationTimeRL m288 : 40|12@1+ (1,0) [0|4095] "sec" GTW
 SG_ TAS_a288_inflationTimeRR m288 : 52|12@1+ (1,0) [0|4095] "sec" GTW
 SG_ TAS_a289_deflationTimeFL m289 : 16|12@1+ (1,0) [0|4095] "sec" GTW
 SG_ TAS_a289_deflationTimeFR m289 : 28|12@1+ (1,0) [0|4095] "sec" GTW
 SG_ TAS_a289_deflationTimeRL m289 : 40|12@1+ (1,0) [0|4095] "sec" GTW
 SG_ TAS_a289_deflationTimeRR m289 : 52|12@1+ (1,0) [0|4095] "sec" GTW
 SG_ TAS_a290_twistLevel m290 : 16|8@1+ (1,-128) [-128|127] "mm" GTW
 SG_ TAS_a291_frontAxleHeight m291 : 16|8@1+ (1,-128) [-128|127] "mm" GTW
 SG_ TAS_a292_rearAxleHeight m292 : 16|8@1+ (1,-128) [-128|127] "mm" GTW
 SG_ TAS_a293_frontAxleHeight m293 : 16|8@1+ (1,-128) [-128|127] "mm" GTW
 SG_ TAS_a294_rearAxleHeight m294 : 16|8@1+ (1,-128) [-128|127] "mm" GTW
 SG_ TAS_a295_targetHeight m295 : 16|8@1+ (1,-128) [-128|127] "mm" GTW

BO_ 523 TAS_axleData: 7 TAS
 SG_ TAS_axleIndex M : 0|4@1+ (1,0) [5|10] "" GTW
 SG_ TAS_fastFilteredHeightFL m5 : 8|8@1+ (1,-128) [-128|127] "mm" GTW
 SG_ TAS_modeFilteredHeightFL m5 : 16|8@1+ (1,-128) [-128|127] "mm" GTW
 SG_ TAS_componentPressureFL m5 : 24|8@1+ (0.1,0) [0|25.5] "bara" GTW
 SG_ TAS_fastFilteredHeightFR m5 : 32|8@1+ (1,-128) [-128|127] "mm" GTW
 SG_ TAS_modeFilteredHeightFR m5 : 40|8@1+ (1,-128) [-128|127] "mm" GTW
 SG_ TAS_componentPressureFR m5 : 48|8@1+ (0.1,0) [0|25.5] "bara" GTW
 SG_ TAS_fastFilteredHeightRL m10 : 8|8@1+ (1,-128) [-128|127] "mm" GTW
 SG_ TAS_modeFilteredHeightRL m10 : 16|8@1+ (1,-128) [-128|127] "mm" GTW
 SG_ TAS_componentPressureRL m10 : 24|8@1+ (0.1,0) [0|25.5] "bara" GTW
 SG_ TAS_fastFilteredHeightRR m10 : 32|8@1+ (1,-128) [-128|127] "mm" GTW
 SG_ TAS_modeFilteredHeightRR m10 : 40|8@1+ (1,-128) [-128|127] "mm" GTW
 SG_ TAS_componentPressureRR m10 : 48|8@1+ (0.1,0) [0|25.5] "bara" GTW

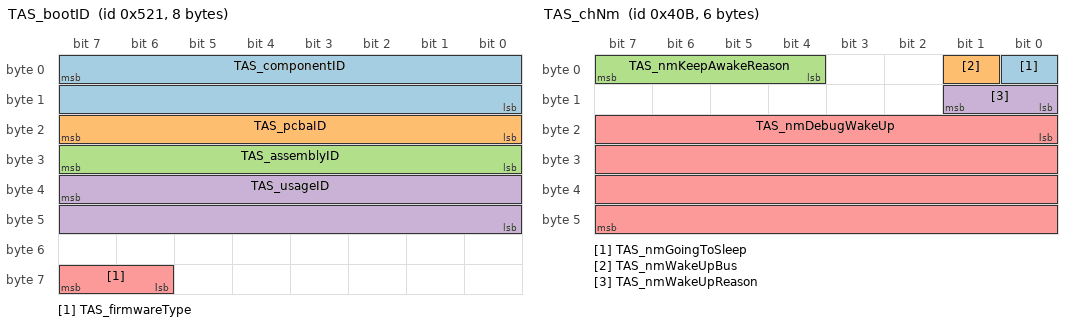
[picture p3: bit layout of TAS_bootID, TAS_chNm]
BO_ 1313 TAS_bootID: 8 TAS
 SG_ TAS_componentID : 7|16@0+ (1,0) [0|65535] "" Vector__XXX
 SG_ TAS_pcbaID : 23|8@0+ (1,0) [0|255] "" Vector__XXX
 SG_ TAS_assemblyID : 31|8@0+ (1,0) [0|255] "" Vector__XXX
 SG_ TAS_usageID : 39|16@0+ (1,0) [0|65535] "" Vector__XXX
 SG_ TAS_firmwareType : 63|2@0+ (1,0) [0|2] "" Vector__XXX

BO_ 1035 TAS_chNm: 6 TAS
 SG_ TAS_nmGoingToSleep : 0|1@1+ (1,0) [0|1] "" Vector__XXX
 SG_ TAS_nmWakeUpBus : 1|1@1+ (1,0) [0|1] "" Vector__XXX
 SG_ TAS_nmKeepAwakeReason : 4|4@1+ (1,0) [0|15] "" GTW
 SG_ TAS_nmWakeUpReason : 8|2@1+ (1,0) [0|3] "" GTW
 SG_ TAS_nmDebugWakeUp : 16|32@1+ (1,0) [0|4294967295] "" GTW

BO_ 546 TAS_compTemp: 2 TAS
 SG_ TAS_compTempSensor : 0|8@1+ (1,-40) [-40|120] "C" GTW
 SG_ TAS_compTempModel : 8|8@1+ (1,-40) [-40|120] "C" GTW

CM_ BO_ 1292 "TAS2 alert matrix";
CM_ SG_ 1412 SD_RS_SCCM "Systemdiagnostic Response";
CM_ SG_ 1284 SG_APPL_SCCM "ECU to external application";
CM_ SG_ 69 SpdCtrlLvr_Stat "Speed control lever status (For cruise control).";
CM_ SG_ 69 VSL_Enbl_Rq "Enable variable speed limiter request";
CM_ SG_ 69 SpdCtrlLvrStat_Inv "Speed control lever state invalid";
CM_ SG_ 69 DTR_Dist_Rq "Distronic distance factor request";
CM_ SG_ 69 TurnIndLvr_Stat "Turn indicator lever state";
CM_ SG_ 69 HiBmLvr_Stat "High beam lever state";
CM_ SG_ 69 WprWashSw_Psd "Wiper/washer switch pressed";
CM_ SG_ 69 WprWash_R_Sw_Posn_V2 "Backlite wiper/washer switch position";
CM_ SG_ 69 StW_Lvr_Stat "Steering wheel lever state";
CM_ SG_ 69 StW_Cond_Flt "Steering wheel conditioning fault";
CM_ SG_ 69 StW_Cond_Psd "Steering wheel conditioning pressed";
CM_ SG_ 69 HrnSw_Psd "Horn switch pressed";
CM_ SG_ 69 StW_Sw00_Psd "Steering wheel tip switch 0 pressed";
CM_ SG_ 69 StW_Sw01_Psd "Steering wheel tip switch 1 pressed";
CM_ SG_ 69 StW_Sw02_Psd "Steering wheel tip switch 2 pressed";
CM_ SG_ 69 StW_Sw03_Psd "Steering wheel tip switch 3 pressed";
CM_ SG_ 69 StW_Sw04_Psd "Steering wheel tip switch 4 pressed";
CM_ SG_ 69 StW_Sw05_Psd "Steering wheel tip switch 5 pressed";
CM_ SG_ 69 StW_Sw06_Psd "Steering wheel tip switch 6 pressed";
CM_ SG_ 69 StW_Sw07_Psd "Steering wheel tip switch 7 pressed";
CM_ SG_ 69 StW_Sw08_Psd "Steering wheel tip switch 8 pressed";
CM_ SG_ 69 StW_Sw09_Psd "Steering wheel tip switch 9 pressed";
CM_ SG_ 69 StW_Sw10_Psd "Steering wheel tip switch 10 pressed";
CM_ SG_ 69 StW_Sw11_Psd "Steering wheel tip switch 11 pressed";
CM_ SG_ 69 StW_Sw12_Psd "Steering wheel tip switch 12 pressed";
CM_ SG_ 69 StW_Sw13_Psd "Steering wheel tip switch 13 pressed";
CM_ SG_ 69 StW_Sw14_Psd "Steering wheel tip switch 14 pressed";
CM_ SG_ 69 StW_Sw15_Psd "Steering wheel tip switch 15 pressed";
CM_ SG_ 69 WprSw6Posn "Wiper switch (6 stages) position";
CM_ SG_ 69 MC_STW_ACTN_RQ "Message counter";
CM_ SG_ 69 CRC_STW_ACTN_RQ "CRC-checksum byte 1 to 7 according to SAE J1850";
CM_ SG_ 14 StW_AnglHP "Steering wheel angle with high precision";
CM_ SG_ 14 StW_AnglHP_Spd "Steering wheel angle speed with high precision.";
CM_ SG_ 14 StW_AnglHP_Sens_Stat "Steering wheel angle with high presision sensor state";
CM_ SG_ 14 StW_AnglHP_Sens_Id "Steering wheel angle with high precision sensor identification";
CM_ SG_ 14 MC_STW_ANGLHP_STAT "Message counter";
CM_ SG_ 14 CRC_STW_ANGLHP_STAT "CRC-checksum byte 1 to 7 according to SAE J1850";
CM_ SG_ 3 StW_Angl "Steering wheel angle";
CM_ SG_ 3 StW_AnglSpd "Steering wheel angle speed";
CM_ SG_ 3 StW_AnglSens_Stat "Steering wheel angle sensor state";
CM_ SG_ 3 StW_AnglSens_Id "Steering wheel angle sensor identification";
CM_ SG_ 3 MC_STW_ANGL_STAT "Message counter";
CM_ SG_ 3 CRC_STW_ANGL_STAT "CRC-checksum byte 1 to 7 according to SAE J1850";
CM_ SG_ 1293 TAS2_alertID "Numeric ID that identifies the alert.";
CM_ SG_ 1293 TAS2_alertType "TAS2 alert state (set or cleared)";
CM_ SG_ 1293 TAS2_a000_alertDataW0 "Generic word access to alert data W0.";
CM_ SG_ 1293 TAS2_a000_alertDataW1 "Generic word access to alert data W1.";
CM_ SG_ 1293 TAS2_a000_alertDataW2 "Generic word access to alert data W2.";
CM_ SG_ 1292 TAS2_matrixIndex "Alert Matrix multiplexer index";
CM_ SG_ 1292 TAS2_a001_WatchdogReset "Warns if the processor has experienced a reset due to watchdog reset.";
CM_ SG_ 1292 TAS2_a002_PowerLossReset "Warns if the processor has experienced a reset due to power loss.";
CM_ SG_ 1292 TAS2_a003_SWAssertion "An internal software assertion has failed.";
CM_ SG_ 1292 TAS2_a012_CPUReset "CPU detected a reset.";
CM_ SG_ 1292 TAS2_a015_NVMMAlert "An issue is indicated from the NVRAM Manager.";
CM_ SG_ 1292 TAS2_a021_TaskSchedulerError "If a task was not able to run at the appropriate time.";
CM_ SG_ 1292 TAS2_a022_TaskInitError "If a task failed to initialize.";
CM_ SG_ 1292 TAS2_a025_CrashEvent "Air suspension functionality is disabled due to vehicle crash reported by restraint module.";
CM_ SG_ 1292 TAS2_a030_PWMerrorFL "Abnormal PWM signal received from front left PWM height sensor.";
CM_ SG_ 1292 TAS2_a031_PWMerrorFR "Abnormal PWM signal received from front right PWM height sensor.";
CM_ SG_ 1292 TAS2_a032_PWMerrorRL "Abnormal PWM signal received from rear left PWM height sensor.";
CM_ SG_ 1292 TAS2_a033_PWMerrorRR "Abnormal PWM signal received from rear right PWM height sensor.";
CM_ SG_ 1292 TAS2_a034_PWMshortFL "Signal line from front left PWM height sensor shorted to ground.";
CM_ SG_ 1292 TAS2_a035_PWMshortFR "Signal line from front right PWM height sensor shorted to ground.";
CM_ SG_ 1292 TAS2_a036_PWMshortRL "Signal line from rear left PWM height sensor shorted to ground.";
CM_ SG_ 1292 TAS2_a037_PWMshortRR "Signal line from rear right PWM height sensor shorted to ground.";
CM_ SG_ 1292 TAS2_a038_PWMopenFL "Front left height sensor disconnected, or signal line from front left PWM height sensor floating.";
CM_ SG_ 1292 TAS2_a039_PWMopenFR "Front right height sensor disconnected, or signal line from front right PWM height sensor floating.";
CM_ SG_ 1292 TAS2_a040_PWMopenRL "Rear left height sensor disconnected, or signal line from rear left PWM height sensor floating.";
CM_ SG_ 1292 TAS2_a041_PWMopenRR "Rear right height sensor disconnected, or signal line from rear right PWM height sensor floating.";
CM_ SG_ 1292 TAS2_a043_Task1msError "Debug information for 1ms task errors. Set along with TaskSchedulerError.";
CM_ SG_ 1292 TAS2_a044_Task10msError "Debug information for 10ms task errors. Set along with TaskSchedulerError.";
CM_ SG_ 1292 TAS2_a045_Task100msError "Debug information for 100ms task errors. Set along with TaskSchedulerError.";
CM_ SG_ 1292 TAS2_a046_Task1000msError "Debug information for 1000ms task errors. Set along with TaskSchedulerError.";
CM_ SG_ 1292 TAS2_a061_XCPConnected "Indicates an active connection to the XCP state machine";
CM_ SG_ 1292 TAS2_a062_XCPWasConnected "Indicates there was an active connection to the XCP state machine";
CM_ SG_ 1292 TAS2_a070_underVoltage12V "Supply voltage to ECU is below 8.5V";
CM_ SG_ 1292 TAS2_a071_overVoltage12V "Supply voltage to ECU is above 16.5V";
CM_ SG_ 1292 TAS2_a072_shortCircuit5VOnBoard "On board 5V switched supply is measured to be approximately 0V.";
CM_ SG_ 1292 TAS2_a073_underVoltage5VOnBoard "On board 5V switched supply is measured to be below 4.5V.";
CM_ SG_ 1292 TAS2_a077_pressureSigVTooLow "Pressure sensor signal voltage too low; likely disconnected.";
CM_ SG_ 1292 TAS2_a078_pressureSigVTooHigh "Pressure sensor signal voltage too high.";
CM_ SG_ 1292 TAS2_a080_shortCircuit5VHeight "Off board 5V ride height sensor switched supply is measured to be approximately 0V.";
CM_ SG_ 1292 TAS2_a081_underVoltage5VHeight "Off board 5V ride height sensor switched supply is measured to be under 4.5V.";
CM_ SG_ 1292 TAS2_a082_overVoltage5VHeight "Off board 5V ride height sensor switched supply is measured to be over 5.5V.";
CM_ SG_ 1292 TAS2_a083_shortCircuit5VAnalog "Off board 5V pressure sensor switched supply is measured to be approximately 0V.";
CM_ SG_ 1292 TAS2_a084_underVoltage5VAnalog "Off board 5V pressure sensor switched supply is measured to be under 4.5V.";
CM_ SG_ 1292 TAS2_a085_overVoltage5VAnalog "Off board 5V pressure sensor switched supply is measured to be over 5.5V.";
CM_ SG_ 1292 TAS2_a086_underVoltage12VSwtchd "Switched 12V supply measured considerably lower than input 12V supply.";
CM_ SG_ 1292 TAS2_a087_overVoltage12VSwtchd "Switched 12V supply measured considerably higher than input 12V supply.";
CM_ SG_ 1292 TAS2_a093_OTPError "The one time programmable memory driver has encountered an error.";
CM_ SG_ 1292 TAS2_a094_DAS_MIA "One or more CAN messages from DAS are not being received by the ECU.";
CM_ SG_ 1292 TAS2_a095_DIS_MIA "One or more CAN messages from DIS are not being received by the ECU.";
CM_ SG_ 1292 TAS2_a096_IMU_MIA "One or more CAN messages from IMU are not being received by the ECU.";
CM_ SG_ 1292 TAS2_a097_RCM_MIA "One or more CAN messages from RCM are not being received by the ECU.";
CM_ SG_ 1292 TAS2_a098_MCU_MIA "One or more CAN messages from MCU are not being received by the ECU.";
CM_ SG_ 1292 TAS2_a099_EFUSE_MIA "One or more CAN messages from EFUSE are not being received by the ECU.";
CM_ SG_ 1292 TAS2_a100_SCCM_MIA "One or more CAN messages from SCCM are not being received by the ECU.";
CM_ SG_ 1292 TAS2_a101_ESP_MIA "One or more CAN messages from ESP are not being received by the ECU.";
CM_ SG_ 1292 TAS2_a102_DI_MIA "One or more CAN messages from DI are not being received by the ECU.";
CM_ SG_ 1292 TAS2_a103_GTW_MIA "One or more CAN messages from GTW are not being received by the ECU.";
CM_ SG_ 1292 TAS2_a106_HighCPULoad "to do";
CM_ SG_ 1292 TAS2_a107_HighStackUsage "to do";
CM_ SG_ 1292 TAS2_a121_maxDutyFL "Front left air valve has reached its duty cycle (on time) limit.";
CM_ SG_ 1292 TAS2_a122_maxDutyFR "Front right air valve has reached its duty cycle (on time) limit.";
CM_ SG_ 1292 TAS2_a123_maxDutyRL "Rear left air valve has reached its duty cycle (on time) limit.";
CM_ SG_ 1292 TAS2_a124_maxDutyRR "Rear right air valve has reached its duty cycle (on time) limit.";
CM_ SG_ 1292 TAS2_a125_maxDutyReservoir "Reservoir air valve has reached its duty cycle (on time) limit.";
CM_ SG_ 1292 TAS2_a126_maxDutyExhaust "Exhaust air valve has reached its duty cycle (on time) limit.";
CM_ SG_ 1292 TAS2_a127_maxDutyBoost "Boost air valve has reached its duty cycle (on time) limit.";
CM_ SG_ 1292 TAS2_a128_maxDutyCompressor "Air compressor has reached its duty cycle (on time) limit.";
CM_ SG_ 1292 TAS2_a129_openCircuitFL "Front left air valve detected open circuit.";
CM_ SG_ 1292 TAS2_a130_openCircuitFR "Front right air valve detected open circuit.";
CM_ SG_ 1292 TAS2_a131_openCircuitRL "Rear left air valve detected open circuit.";
CM_ SG_ 1292 TAS2_a132_openCircuitRR "Rear right air valve detected open circuit.";
CM_ SG_ 1292 TAS2_a133_openCircuitReservoir "Reservoir air valve detected open circuit.";
CM_ SG_ 1292 TAS2_a134_openCircuitExhaust "Exhaust air valve detected open circuit.";
CM_ SG_ 1292 TAS2_a135_openCircuitBoost "Boost air valve detected open circuit.";
CM_ SG_ 1292 TAS2_a136_openCircuitCompressor "Air compressor or air compressor relay detected open circuit.";
CM_ SG_ 1292 TAS2_a137_shortCircuitFL "Front left air valve detected short circuit.";
CM_ SG_ 1292 TAS2_a138_shortCircuitFR "Front right air valve detected short circuit.";
CM_ SG_ 1292 TAS2_a139_shortCircuitRL "Rear left air valve detected short circuit.";
CM_ SG_ 1292 TAS2_a140_shortCircuitRR "Rear right air valve detected short circuit.";
CM_ SG_ 1292 TAS2_a141_shortCircuitReservoir "Reservoir air valve detected short circuit.";
CM_ SG_ 1292 TAS2_a142_shortCircuitExhaust "Exhaust air valve detected short circuit.";
CM_ SG_ 1292 TAS2_a143_shortCircuitBoost "Boost air valve detected short circuit.";
CM_ SG_ 1292 TAS2_a144_shortCircuitCompressor "Air compressor or air compressor relay detected short circuit.";
CM_ SG_ 1292 TAS2_a145_boardFaultFL "Implausible condition detected on front left air valve circuit, possibly due to ECU hardware failure.";
CM_ SG_ 1292 TAS2_a146_boardFaultFR "Implausible condition detected on front right air valve circuit, possibly due to ECU hardware failure.";
CM_ SG_ 1292 TAS2_a147_boardFaultRL "Implausible condition detected on rear left air valve circuit, possibly due to ECU hardware failure.";
CM_ SG_ 1292 TAS2_a148_boardFaultRR "Implausible condition detected on rear right air valve circuit, possibly due to ECU hardware failure.";
CM_ SG_ 1292 TAS2_a149_boardFaultReservoir "Implausible condition detected on reservoir air valve circuit, possibly due to ECU hardware failure.";
CM_ SG_ 1292 TAS2_a150_boardFaultExhaust "Implausible condition detected on exhaust air valve circuit, possibly due to ECU hardware failure.";
CM_ SG_ 1292 TAS2_a151_boardFaultBoost "Implausible condition detected on boost air valve circuit, possibly due to ECU hardware failure.";
CM_ SG_ 1292 TAS2_a152_boardFaultCompressor "Implausible condition detected on air compressor or air compressor relay circuit, possibly due to ECU hardware failure.";
CM_ SG_ 1292 TAS2_a153_otherCircuitFL "Implausible condition detected on front left air valve circuit.";
CM_ SG_ 1292 TAS2_a154_otherCircuitFR "Implausible condition detected on front right air valve circuit.";
CM_ SG_ 1292 TAS2_a155_otherCircuitRL "Implausible condition detected on rear left air valve circuit.";
CM_ SG_ 1292 TAS2_a156_otherCircuitRR "Implausible condition detected on rear right air valve circuit.";
CM_ SG_ 1292 TAS2_a157_otherCircuitReservoir "Implausible condition detected on reservoir air valve circuit.";
CM_ SG_ 1292 TAS2_a158_otherCircuitExhaust "Implausible condition detected on exhaust air valve circuit.";
CM_ SG_ 1292 TAS2_a159_otherCircuitBoost "Implausible condition detected on boost air valve circuit.";
CM_ SG_ 1292 TAS2_a160_otherCircuitCompressor "Implausible condition detected on air compressor or air compressor relay circuit.";
CM_ SG_ 1292 TAS2_a161_valveBlockOpenGND "Ground return wire from corner/reservoir valve block detected disconnected.";
CM_ SG_ 1292 TAS2_a162_compressorValveOpenGND "Ground return wire from exhaust/boost valve block detected disconnected.";
CM_ SG_ 1292 TAS2_a163_reservoirFillDisabled "useless!";
CM_ SG_ 1292 TAS2_a165_damperValveCompFL "Front left compression damper valve detected to be unplugged, shorted, pin-swapped, or otherwise faulted.";
CM_ SG_ 1292 TAS2_a166_damperValveRbndFL "Front left rebound damper valve detected to be unplugged, shorted, pin-swapped, or otherwise faulted.";
CM_ SG_ 1292 TAS2_a167_damperValveCompFR "Front right compression damper valve detected to be unplugged, shorted, pin-swapped, or otherwise faulted.";
CM_ SG_ 1292 TAS2_a168_damperValveRbndFR "Front right rebound damper valve detected to be unplugged, shorted, pin-swapped, or otherwise faulted.";
CM_ SG_ 1292 TAS2_a169_damperValveCompRL "Rear left compression damper valve detected to be unplugged, shorted, pin-swapped, or otherwise faulted.";
CM_ SG_ 1292 TAS2_a170_damperValveRbndRL "Rear left rebound damper valve detected to be unplugged, shorted, pin-swapped, or otherwise faulted.";
CM_ SG_ 1292 TAS2_a171_damperValveCompRR "Rear right compression damper valve detected to be unplugged, shorted, pin-swapped, or otherwise faulted.";
CM_ SG_ 1292 TAS2_a172_damperValveRbndRR "Rear right rebound damper valve detected to be unplugged, shorted, pin-swapped, or otherwise faulted.";
CM_ SG_ 1292 TAS2_a173_staticLeakDetectFL "Static vehicle spring leak check detected a spring leak on the front left air spring.";
CM_ SG_ 1292 TAS2_a174_staticLeakDetectFR "Static vehicle spring leak check detected a spring leak on the front right air spring.";
CM_ SG_ 1292 TAS2_a175_staticLeakDetectRL "Static vehicle spring leak check detected a spring leak on the rear left air spring.";
CM_ SG_ 1292 TAS2_a176_staticLeakDetectRR "Static vehicle spring leak check detected a spring leak on the rear right air spring.";
CM_ SG_ 1292 TAS2_a200_jackModeActive "Air suspension is in jack mode.";
CM_ SG_ 1292 TAS2_a201_lowHVBattery "Received a 12V low shed request.";
CM_ SG_ 1292 TAS2_a210_outOfRangeCalibration "Received ride height sensor calibration values are outside of allowable range.";
CM_ SG_ 1292 TAS2_a211_noRideHeightCalib "No valid ride height sensor calibrations have been saved to the ECU.";
CM_ SG_ 1292 TAS2_a213_yellowWarningLamp "ECU has requested suspension yellow warning lamp to be displayed.";
CM_ SG_ 1292 TAS2_a214_redWarningLamp "ECU has requested suspension red warning lamp to be displayed.";
CM_ SG_ 1292 TAS2_a215_limpHomeMode10 "Air suspension system is operating under limp home mode 10 restrictions.";
CM_ SG_ 1292 TAS2_a216_limpHomeMode20 "Air suspension system is operating under limp home mode 20 restrictions.";
CM_ SG_ 1292 TAS2_a217_limpHomeMode30 "Air suspension system is operating under limp home mode 30 restrictions.";
CM_ SG_ 1292 TAS2_a218_limpHomeMode40 "Air suspension system is operating under limp home mode 40 restrictions.";
CM_ SG_ 1292 TAS2_a220_exhaustGalleryFault "Fault occurred while attempting to exhaust the air gallery.";
CM_ SG_ 1292 TAS2_a221_valveLeakDetected "Internal air spring or air reservoir valve leak detected.";
CM_ SG_ 1292 TAS2_a222_compressorPrefillFault "Air compressor failed to build pressure when powered.";
CM_ SG_ 1292 TAS2_a223_blockedAirline "An airline to the air springs or air reservoir has been detected blocked/crushed.";
CM_ SG_ 1292 TAS2_a224_openAirline "An airline to the air springs or air reservoir has been detected disconnected/open.";
CM_ SG_ 1292 TAS2_a225_galleryPressureTooHigh "Gallery pressure too high.";
CM_ SG_ 1292 TAS2_a226_PWMfastDetectFL "Abnormal PWM signal received from front left PWM height sensor. More sensitive than other ride height sensor alerts.";
CM_ SG_ 1292 TAS2_a227_PWMfastDetectFR "Abnormal PWM signal received from front right PWM height sensor. More sensitive than other ride height sensor alerts.";
CM_ SG_ 1292 TAS2_a228_PWMfastDetectRL "Abnormal PWM signal received from rear left PWM height sensor. More sensitive than other ride height sensor alerts.";
CM_ SG_ 1292 TAS2_a229_PWMfastDetectRR "Abnormal PWM signal received from rear right PWM height sensor. More sensitive than other ride height sensor alerts.";
CM_ SG_ 1292 TAS2_a230_geofenceNotification "Signal to UI to show suspension geofence notification.";
CM_ SG_ 1292 TAS2_a286_driveCycleStats1 "Drive cycle statistics.";
CM_ SG_ 1292 TAS2_a287_driveCycleStats2 "Drive cycle statistics.";
CM_ SG_ 1292 TAS2_a288_driveCycleStats3 "Drive cycle statistics.";
CM_ SG_ 1292 TAS2_a289_driveCycleStats4 "Drive cycle statistics.";
CM_ SG_ 1292 TAS2_a290_twistSustainedAtSpeed "Ride height sensors are measured to be in twisted or implausible state.";
CM_ SG_ 1292 TAS2_a291_frontAxleTooHigh "Front axle has been measured to be higher than any reasonable height.";
CM_ SG_ 1292 TAS2_a292_rearAxleTooHigh "Rear axle has been measured to be higher than any reasonable height.";
CM_ SG_ 1292 TAS2_a293_frontAxleTooLow "Front axle has been measured to be lower than any reasonable height.";
CM_ SG_ 1292 TAS2_a294_rearAxleTooLow "Rear axle has been measured to be lower than any reasonable height.";
CM_ SG_ 1292 TAS2_a295_targetHeightNotMet "Air suspension failed to adjust to target ride height.";
CM_ SG_ 1292 TAS2_a296_chassisTypeMismatch "Firmware's supported chassis type does not match chassis type reported by vehicle's gateway.";
CM_ SG_ 1292 TAS2_a297_vinMismatch "Learned VIN does not match VIN reported by vehicle's gateway.";
CM_ SG_ 1292 TAS2_a298_vinNotLearned "VIN has not been learned via vehicle's gateway.";
CM_ SG_ 1292 TAS2_a299_offsetEstimateTooLarge "Firmware debug alert.";
CM_ SG_ 1292 TAS2_a300_offsetEstimateData1 "Firmware debug alert.";
CM_ SG_ 1292 TAS2_a301_offsetEstimateData2 "Firmware debug alert.";
CM_ SG_ 1292 TAS2_a303_massEstimateFrozen "Firmware debug alert.";
CM_ SG_ 1292 TAS2_a304_massEstimateFrozenData "Firmware debug alert.";
CM_ SG_ 1292 TAS2_a305_newEndstopPosition "Firmware debug alert.";
CM_ SG_ 1292 TAS2_a306_endstopProtectFrozen "Firmware debug alert.";
CM_ SG_ 1292 TAS2_a307_endstopBoundaryComp "Firmware debug alert.";
CM_ SG_ 1292 TAS2_a308_endstopBoundaryRbnd "Firmware debug alert.";
CM_ SG_ 1292 TAS2_a309_controlFrozen "Firmware debug alert.";
CM_ SG_ 1292 TAS2_a310_controlFrozenData "Firmware debug alert.";
CM_ SG_ 1292 TAS2_a311_accelsMIA "Vehicle body accelerations are unknown.";
CM_ SG_ 1292 TAS2_a312_rotationalRatesMIA "Vehicle body rotational rates are unknown.";
CM_ SG_ 1292 TAS2_a313_dampingCntrlDisabled "Active damping control is disabled.";
CM_ SG_ 1292 TAS2_a314_dampingReduced "All dampers are unpowered.";
CM_ SG_ 1292 TAS2_a315_pcbaHighTemp "Firmware debug alert.";
CM_ SG_ 1292 TAS2_a316_offsetsAccels "Debug alert 316 for inertial accelerometer offsets";
CM_ SG_ 1292 TAS2_a317_offsetsRotationalRates "Debug alert 316 for inertial accelerometer offsets";
CM_ SG_ 1398 TAS2_endstopState "SW-237496";
CM_ SG_ 1398 TAS2_continuousControlState "SW-237496";
CM_ SG_ 1398 TAS2_roadCondition "SW-237496";
CM_ SG_ 1398 TAS2_McQueenBoostAxleFront "SW-237496";
CM_ SG_ 1398 TAS2_McQueenBoostAxleRear "SW-237496";
CM_ SG_ 1398 TAS2_speedBumpAxleFront "SW-237496";
CM_ SG_ 1398 TAS2_speedBumpAxleRear "SW-237496";
CM_ SG_ 1398 TAS2_holeProtectFL "SW-237496";
CM_ SG_ 1398 TAS2_holeProtectFR "SW-237496";
CM_ SG_ 1398 TAS2_holeProtectRL "SW-237496";
CM_ SG_ 1398 TAS2_holeProtectRR "SW-237496";
CM_ SG_ 1398 TAS2_stepProtectFL "SW-237496";
CM_ SG_ 1398 TAS2_stepProtectFR "SW-237496";
CM_ SG_ 1398 TAS2_stepProtectRL "SW-237496";
CM_ SG_ 1398 TAS2_stepProtectRR "SW-237496";
CM_ SG_ 1291 TAS_alertID "Numeric ID that identifies the alert.";
CM_ SG_ 1291 TAS_alertType "TAS alert state (set or cleared)";
CM_ SG_ 1291 TAS_a000_alertDataW0 "Generic word access to alert data W0.";
CM_ SG_ 1291 TAS_a000_alertDataW1 "Generic word access to alert data W1.";
CM_ SG_ 1291 TAS_a000_alertDataW2 "Generic word access to alert data W2.";
CM_ SG_ 523 TAS_fastFilteredHeightFL "to do";
CM_ SG_ 523 TAS_modeFilteredHeightFL "to do";
CM_ SG_ 523 TAS_fastFilteredHeightFR "to do";
CM_ SG_ 523 TAS_modeFilteredHeightFR "to do";
CM_ SG_ 523 TAS_fastFilteredHeightRL "to do";
CM_ SG_ 523 TAS_modeFilteredHeightRL "to do";
CM_ SG_ 523 TAS_fastFilteredHeightRR "to do";
CM_ SG_ 523 TAS_modeFilteredHeightRR "to do";
CM_ SG_ 1035 TAS_nmKeepAwakeReason "to do";
CM_ SG_ 1035 TAS_nmWakeUpReason "to do";
CM_ SG_ 1035 TAS_nmDebugWakeUp "to do";
CM_ SG_ 546 TAS_compTempSensor "to do";
CM_ SG_ 546 TAS_compTempModel "to do";
BA_DEF_ BO_ "AlertLogSubSystemId" INT 0 0;
BA_DEF_ BO_ "AlertType" INT 0 4;
BA_DEF_ BO_ "AppBotschaft" ENUM "nein","ja";
BA_DEF_ BO_ "DiagRequest" ENUM "No","Yes";
BA_DEF_ BO_ "DiagResponse" ENUM "No","Yes";
BA_DEF_ BO_ "ETHGatewayMessageSendType" ENUM "UseGenMsgSendType","onWrite","noAutoCode";
BA_DEF_ BO_ "ETHId" STRING ;
BA_DEF_ BO_ "GatewayHandlerEnum" ENUM "noHandler","uds","alertLog","messageLogOnReception","udsClient";
BA_DEF_ BO_ "GatewayMessageAtomic" ENUM "No","Yes";
BA_DEF_ BO_ "GatewayMessageSendType" ENUM "UseGenMsgSendType","onWrite","noAutoCode";
BA_DEF_ BO_ "GenMsgCycleTime" INT 0 0;
BA_DEF_ BO_ "GenMsgCycleTimeFast" INT 0 0;
BA_DEF_ BO_ "GenMsgDelayTime" INT 0 0;
BA_DEF_ BO_ "GenMsgForceMiaCheck" ENUM "No","Yes";
BA_DEF_ BO_ "GenMsgGatewayNotification" STRING ;
BA_DEF_ BO_ "GenMsgILSupport" ENUM "No","Yes";
BA_DEF_ BO_ "GenMsgSaltingFunction" ENUM "No","Yes";
BA_DEF_ BO_ "GenMsgSendType" ENUM "Cyclic","NotUsed","NotUsed","NotUsed","NotUsed","NotUsed","NotUsed","IfActive","NoMsgSendType","Sporadic";
BA_DEF_ BO_ "GenMsgStartValue" STRING ;
BA_DEF_ BO_ "GenMsgTimeOut" INT 0 0;
BA_DEF_ BO_ "MessageIdType" ENUM "normal","udsRequest","udsResponse","udsReserved","udsFunctionalRequest","networkManagement","bootloader","xcp","dtc","diagnostic","vendorExempt";
BA_DEF_ BO_ "NWMBotschaft" ENUM "nein","ja";
BA_DEF_ BO_ "NmMessage" ENUM "No","Yes";
BA_DEF_ BO_ "SubSystemId" INT 0 256;
BA_DEF_ BO_ "UsesChecksum" ENUM "No","Yes";
BA_DEF_ SG_ "FieldType" STRING ;
BA_DEF_ SG_ "FlexKomComment" STRING ;
BA_DEF_ SG_ "FlexKomIsMotorola" ENUM "nein","ja";
BA_DEF_ SG_ "FlexKomSID" INT 0 2147483647;
BA_DEF_ SG_ "FlexKomSigLaenge" INT 0 64;
BA_DEF_ SG_ "FlexKomSigName" STRING ;
BA_DEF_ SG_ "FlexKomSigStartPos" INT 0 63;
BA_DEF_ SG_ "FlexKomSigStartValue" STRING ;
BA_DEF_ SG_ "Gatewaysignal" INT 0 1;
BA_DEF_ SG_ "GenSigCycleTime" INT 0 0;
BA_DEF_ SG_ "GenSigCycleTimeActive" INT 0 0;
BA_DEF_ SG_ "GenSigPersistent" ENUM "No","Yes";
BA_DEF_ SG_ "GenSigSNA" STRING ;
BA_DEF_ SG_ "GenSigSendType" ENUM "Cyclic","OnWrite","OnWriteWithRepetition","OnChange","OnChangeWithRepetition","IfActive","IfActiveWithRepetition","NoSigSendType","NotUsed","NotUsed","NotUsed","NotUsed","NotUsed";
BA_DEF_ SG_ "GenSigStartValue" INT 0 0;
BA_DEF_ SG_ "GenSigTimeout_CGW" INT 0 65535;
BA_DEF_ SG_ "GenSigTimeout_DRVU" INT 0 65535;
BA_DEF_ SG_ "GenSigTimeout_ECM" INT 0 65535;
BA_DEF_ SG_ "GenSigTimeout_EIS" INT 0 65535;
BA_DEF_ SG_ "GenSigTimeout_EPS" INT 0 65535;
BA_DEF_ SG_ "GenSigTimeout_ESP_ABR" INT 0 65535;
BA_DEF_ SG_ "GenSigTimeout_IC" INT 0 65535;
BA_DEF_ SG_ "GenSigTimeout_MPC" INT 0 65535;
BA_DEF_ SG_ "GenSigTimeout_NV" INT 0 65535;
BA_DEF_ SG_ "GenSigTimeout_ORC" INT 0 65535;
BA_DEF_ SG_ "GenSigTimeout_PTS" INT 0 65535;
BA_DEF_ SG_ "GenSigTimeout_RBTM_FL" INT 0 65535;
BA_DEF_ SG_ "GenSigTimeout_RBTM_FR" INT 0 65535;
BA_DEF_ SG_ "GenSigTimeout_RDU" INT 0 65535;
BA_DEF_ SG_ "GenSigTimeout_SCCM" INT 0 65535;
BA_DEF_ SG_ "GenSigTimeout_SPC" INT 0 65535;
BA_DEF_ SG_ "GenSigTimeout_TPM" INT 0 65535;
BA_DEF_ SG_ "LogSignal" STRING ;
BA_DEF_ SG_ "PektronUpdateBitType" ENUM "Not used","Has update bit","Is update bit";
BA_DEF_REL_ BU_SG_REL_ "GenSigTimeoutTime" INT 0 0;

BA_DEF_DEF_ "AlertLogSubSystemId" 0;
BA_DEF_DEF_ "AlertType" 4;
BA_DEF_DEF_ "AppBotschaft" "nein";
BA_DEF_DEF_ "DiagRequest" "No";
BA_DEF_DEF_ "DiagResponse" "No";
BA_DEF_DEF_ "ETHGatewayMessageSendType" "UseGenMsgSendType";
BA_DEF_DEF_ "ETHId" "";
BA_DEF_DEF_ "FieldType" "";
BA_DEF_DEF_ "FlexKomComment" "";
BA_DEF_DEF_ "FlexKomIsMotorola" "";
BA_DEF_DEF_ "FlexKomSID" 0;
BA_DEF_DEF_ "FlexKomSigLaenge" 0;
BA_DEF_DEF_ "FlexKomSigName" "";
BA_DEF_DEF_ "FlexKomSigStartPos" 0;
BA_DEF_DEF_ "FlexKomSigStartValue" "";
BA_DEF_DEF_ "GatewayHandlerEnum" "noHandler";
BA_DEF_DEF_ "GatewayMessageAtomic" "No";
BA_DEF_DEF_ "GatewayMessageSendType" "UseGenMsgSendType";
BA_DEF_DEF_ "Gatewaysignal" 0;
BA_DEF_DEF_ "GenMsgCycleTime" 0;
BA_DEF_DEF_ "GenMsgCycleTimeFast" 0;
BA_DEF_DEF_ "GenMsgDelayTime" 0;
BA_DEF_DEF_ "GenMsgForceMiaCheck" "No";
BA_DEF_DEF_ "GenMsgGatewayNotification" "";
BA_DEF_DEF_ "GenMsgILSupport" "Yes";
BA_DEF_DEF_ "GenMsgSaltingFunction" "No";
BA_DEF_DEF_ "GenMsgSendType" "Cyclic";
BA_DEF_DEF_ "GenMsgStartValue" "";
BA_DEF_DEF_ "GenMsgTimeOut" 0;
BA_DEF_DEF_ "GenSigCycleTime" 0;
BA_DEF_DEF_ "GenSigCycleTimeActive" 0;
BA_DEF_DEF_ "GenSigPersistent" "No";
BA_DEF_DEF_ "GenSigSNA" "";
BA_DEF_DEF_ "GenSigSendType" "Cyclic";
BA_DEF_DEF_ "GenSigStartValue" 0;
BA_DEF_DEF_ "GenSigTimeout_CGW" 0;
BA_DEF_DEF_ "GenSigTimeout_DRVU" 0;
BA_DEF_DEF_ "GenSigTimeout_ECM" 0;
BA_DEF_DEF_ "GenSigTimeout_EIS" 0;
BA_DEF_DEF_ "GenSigTimeout_EPS" 0;
BA_DEF_DEF_ "GenSigTimeout_ESP_ABR" 0;
BA_DEF_DEF_ "GenSigTimeout_IC" 0;
BA_DEF_DEF_ "GenSigTimeout_MPC" 0;
BA_DEF_DEF_ "GenSigTimeout_NV" 0;
BA_DEF_DEF_ "GenSigTimeout_ORC" 0;
BA_DEF_DEF_ "GenSigTimeout_PTS" 0;
BA_DEF_DEF_ "GenSigTimeout_RBTM_FL" 0;
BA_DEF_DEF_ "GenSigTimeout_RBTM_FR" 0;
BA_DEF_DEF_ "GenSigTimeout_RDU" 0;
BA_DEF_DEF_ "GenSigTimeout_SCCM" 0;
BA_DEF_DEF_ "GenSigTimeout_SPC" 0;
BA_DEF_DEF_ "GenSigTimeout_TPM" 0;
BA_DEF_DEF_ "LogSignal" "";
BA_DEF_DEF_ "MessageIdType" "normal";
BA_DEF_DEF_ "NWMBotschaft" "nein";
BA_DEF_DEF_ "NmMessage" "No";
BA_DEF_DEF_ "PektronUpdateBitType" "Not used";
BA_DEF_DEF_ "SubSystemId" 0;
BA_DEF_DEF_ "UsesChecksum" "No";
BA_DEF_DEF_REL_ "GenSigTimeoutTime" 0;
BA_ "GenMsgCycleTime" BO_ 1412 200;
BA_ "GenMsgStartValue" BO_ 1412 "0000000000000000h";
BA_ "MessageIdType" BO_ 1412 10;
BA_ "AppBotschaft" BO_ 1284 1;
BA_ "GenMsgCycleTime" BO_ 1284 100;
BA_ "GenMsgSendType" BO_ 1284 7;
BA_ "GenMsgStartValue" BO_ 1284 "0000000000000000h";
BA_ "MessageIdType" BO_ 1284 10;
BA_ "GenMsgCycleTime" BO_ 69 100;
BA_ "GenMsgStartValue" BO_ 69 "00FF0000000007FFh";
BA_ "MessageIdType" BO_ 69 10;
BA_ "UsesChecksum" BO_ 69 1;
BA_ "GenMsgCycleTime" BO_ 14 10;
BA_ "GenMsgStartValue" BO_ 14 "3FFF3FFF03FF00FFh";
BA_ "MessageIdType" BO_ 14 10;
BA_ "GenMsgCycleTime" BO_ 3 10;
BA_ "GenMsgStartValue" BO_ 3 "3FFF3FFF03FF00FFh";
BA_ "MessageIdType" BO_ 3 10;
BA_ "GenMsgCycleTime" BO_ 455 10;
BA_ "GenMsgCycleTime" BO_ 456 10;
BA_ "AlertLogSubSystemId" BO_ 1293 266;
BA_ "GatewayHandlerEnum" BO_ 1293 2;
BA_ "AlertType" BO_ 1292 3;
BA_ "GatewayMessageSendType" BO_ 1292 1;
BA_ "GenMsgCycleTime" BO_ 1292 100;
BA_ "GenMsgCycleTime" BO_ 1433 50;
BA_ "GatewayMessageSendType" BO_ 1398 1;
BA_ "GenMsgCycleTime" BO_ 1398 100;
BA_ "GenMsgCycleTime" BO_ 1019 1000;
BA_ "AlertLogSubSystemId" BO_ 1291 229;
BA_ "GatewayHandlerEnum" BO_ 1291 2;
BA_ "GatewayMessageSendType" BO_ 523 1;
BA_ "GenMsgCycleTime" BO_ 523 100;
BA_ "GenMsgCycleTime" BO_ 1035 100;
BA_ "GenMsgCycleTime" BO_ 546 10000;
BA_ "FlexKomComment" SG_ 1412 SD_RS_SCCM "Systemdiagnostic Response";
BA_ "FlexKomIsMotorola" SG_ 1412 SD_RS_SCCM 1;
BA_ "FlexKomSID" SG_ 1412 SD_RS_SCCM 117441587;
BA_ "FlexKomSigLaenge" SG_ 1412 SD_RS_SCCM 64;
BA_ "FlexKomSigName" SG_ 1412 SD_RS_SCCM "SD_RS_SCCM";
BA_ "FlexKomSigStartPos" SG_ 1412 SD_RS_SCCM 7;
BA_ "FlexKomSigStartValue" SG_ 1412 SD_RS_SCCM "0000000000000000h";
BA_ "GenSigCycleTime" SG_ 1412 SD_RS_SCCM 200;
BA_ "GenSigSendType" SG_ 1412 SD_RS_SCCM 9;
BA_ "FlexKomComment" SG_ 1284 SG_APPL_SCCM "ECU to external application";
BA_ "FlexKomIsMotorola" SG_ 1284 SG_APPL_SCCM 1;
BA_ "FlexKomSID" SG_ 1284 SG_APPL_SCCM 117441589;
BA_ "FlexKomSigLaenge" SG_ 1284 SG_APPL_SCCM 64;
BA_ "FlexKomSigName" SG_ 1284 SG_APPL_SCCM "SG_APPL_SCCM";
BA_ "FlexKomSigStartPos" SG_ 1284 SG_APPL_SCCM 7;
BA_ "FlexKomSigStartValue" SG_ 1284 SG_APPL_SCCM "0000000000000000h";
BA_ "GenSigSendType" SG_ 1284 SG_APPL_SCCM 1;
BA_ "FlexKomComment" SG_ 69 SpdCtrlLvr_Stat "Steering wheel actuation request";
BA_ "FlexKomIsMotorola" SG_ 69 SpdCtrlLvr_Stat 1;
BA_ "FlexKomSID" SG_ 69 SpdCtrlLvr_Stat 117440568;
BA_ "FlexKomSigLaenge" SG_ 69 SpdCtrlLvr_Stat 64;
BA_ "FlexKomSigName" SG_ 69 SpdCtrlLvr_Stat "StW_Actn_Rq";
BA_ "FlexKomSigStartPos" SG_ 69 SpdCtrlLvr_Stat 7;
BA_ "FlexKomSigStartValue" SG_ 69 SpdCtrlLvr_Stat "00FF0000000007FFh";
BA_ "GenSigCycleTime" SG_ 69 SpdCtrlLvr_Stat 100;
BA_ "GenSigSendType" SG_ 69 SpdCtrlLvr_Stat 5;
BA_ "GenSigTimeout_CGW" SG_ 69 SpdCtrlLvr_Stat 1050;
BA_ "GenSigTimeout_ESP_ABR" SG_ 69 SpdCtrlLvr_Stat 550;
BA_ "LogSignal" SG_ 69 SpdCtrlLvr_Stat "onChange";
BA_ "FlexKomComment" SG_ 69 VSL_Enbl_Rq "Steering wheel actuation request";
BA_ "FlexKomIsMotorola" SG_ 69 VSL_Enbl_Rq 1;
BA_ "FlexKomSID" SG_ 69 VSL_Enbl_Rq 117440568;
BA_ "FlexKomSigLaenge" SG_ 69 VSL_Enbl_Rq 64;
BA_ "FlexKomSigName" SG_ 69 VSL_Enbl_Rq "StW_Actn_Rq";
BA_ "FlexKomSigStartPos" SG_ 69 VSL_Enbl_Rq 7;
BA_ "FlexKomSigStartValue" SG_ 69 VSL_Enbl_Rq "00FF0000000007FFh";
BA_ "GenSigCycleTime" SG_ 69 VSL_Enbl_Rq 100;
BA_ "GenSigSendType" SG_ 69 VSL_Enbl_Rq 5;
BA_ "GenSigTimeout_CGW" SG_ 69 VSL_Enbl_Rq 1050;
BA_ "GenSigTimeout_ESP_ABR" SG_ 69 VSL_Enbl_Rq 550;
BA_ "GenSigTimeout_MPC" SG_ 69 VSL_Enbl_Rq 1050;
BA_ "LogSignal" SG_ 69 VSL_Enbl_Rq "onChange";
BA_ "FlexKomComment" SG_ 69 SpdCtrlLvrStat_Inv "Steering wheel actuation request";
BA_ "FlexKomIsMotorola" SG_ 69 SpdCtrlLvrStat_Inv 1;
BA_ "FlexKomSID" SG_ 69 SpdCtrlLvrStat_Inv 117440568;
BA_ "FlexKomSigLaenge" SG_ 69 SpdCtrlLvrStat_Inv 64;
BA_ "FlexKomSigName" SG_ 69 SpdCtrlLvrStat_Inv "StW_Actn_Rq";
BA_ "FlexKomSigStartPos" SG_ 69 SpdCtrlLvrStat_Inv 7;
BA_ "FlexKomSigStartValue" SG_ 69 SpdCtrlLvrStat_Inv "00FF0000000007FFh";
BA_ "GenSigCycleTime" SG_ 69 SpdCtrlLvrStat_Inv 100;
BA_ "GenSigSendType" SG_ 69 SpdCtrlLvrStat_Inv 5;
BA_ "GenSigTimeout_CGW" SG_ 69 SpdCtrlLvrStat_Inv 1050;
BA_ "GenSigTimeout_ESP_ABR" SG_ 69 SpdCtrlLvrStat_Inv 550;
BA_ "FlexKomComment" SG_ 69 DTR_Dist_Rq "Steering wheel actuation request";
BA_ "FlexKomIsMotorola" SG_ 69 DTR_Dist_Rq 1;
BA_ "FlexKomSID" SG_ 69 DTR_Dist_Rq 117440568;
BA_ "FlexKomSigLaenge" SG_ 69 DTR_Dist_Rq 64;
BA_ "FlexKomSigName" SG_ 69 DTR_Dist_Rq "StW_Actn_Rq";
BA_ "FlexKomSigStartPos" SG_ 69 DTR_Dist_Rq 7;
BA_ "FlexKomSigStartValue" SG_ 69 DTR_Dist_Rq "00FF0000000007FFh";
BA_ "GenSigSNA" SG_ 69 DTR_Dist_Rq "255";
BA_ "GenSigSendType" SG_ 69 DTR_Dist_Rq 10;
BA_ "GenSigStartValue" SG_ 69 DTR_Dist_Rq 255;
BA_ "GenSigTimeout_CGW" SG_ 69 DTR_Dist_Rq 1050;
BA_ "GenSigTimeout_ESP_ABR" SG_ 69 DTR_Dist_Rq 550;
BA_ "LogSignal" SG_ 69 DTR_Dist_Rq "onChange";
BA_ "FlexKomComment" SG_ 69 TurnIndLvr_Stat "Steering wheel actuation request";
BA_ "FlexKomIsMotorola" SG_ 69 TurnIndLvr_Stat 1;
BA_ "FlexKomSID" SG_ 69 TurnIndLvr_Stat 117440568;
BA_ "FlexKomSigLaenge" SG_ 69 TurnIndLvr_Stat 64;
BA_ "FlexKomSigName" SG_ 69 TurnIndLvr_Stat "StW_Actn_Rq";
BA_ "FlexKomSigStartPos" SG_ 69 TurnIndLvr_Stat 7;
BA_ "FlexKomSigStartValue" SG_ 69 TurnIndLvr_Stat "00FF0000000007FFh";
BA_ "GenSigCycleTime" SG_ 69 TurnIndLvr_Stat 100;
BA_ "GenSigSNA" SG_ 69 TurnIndLvr_Stat "3";
BA_ "GenSigSendType" SG_ 69 TurnIndLvr_Stat 5;
BA_ "GenSigTimeout_CGW" SG_ 69 TurnIndLvr_Stat 1050;
BA_ "GenSigTimeout_ESP_ABR" SG_ 69 TurnIndLvr_Stat 550;
BA_ "GenSigTimeout_MPC" SG_ 69 TurnIndLvr_Stat 1050;
BA_ "GenSigTimeout_PTS" SG_ 69 TurnIndLvr_Stat 550;
BA_ "FlexKomComment" SG_ 69 HiBmLvr_Stat "Steering wheel actuation request";
BA_ "FlexKomIsMotorola" SG_ 69 HiBmLvr_Stat 1;
BA_ "FlexKomSID" SG_ 69 HiBmLvr_Stat 117440568;
BA_ "FlexKomSigLaenge" SG_ 69 HiBmLvr_Stat 64;
BA_ "FlexKomSigName" SG_ 69 HiBmLvr_Stat "StW_Actn_Rq";
BA_ "FlexKomSigStartPos" SG_ 69 HiBmLvr_Stat 7;
BA_ "FlexKomSigStartValue" SG_ 69 HiBmLvr_Stat "00FF0000000007FFh";
BA_ "GenSigCycleTime" SG_ 69 HiBmLvr_Stat 100;
BA_ "GenSigSNA" SG_ 69 HiBmLvr_Stat "3";
BA_ "GenSigSendType" SG_ 69 HiBmLvr_Stat 5;
BA_ "GenSigTimeout_CGW" SG_ 69 HiBmLvr_Stat 1050;
BA_ "GenSigTimeout_ESP_ABR" SG_ 69 HiBmLvr_Stat 550;
BA_ "FlexKomComment" SG_ 69 WprWashSw_Psd "Steering wheel actuation request";
BA_ "FlexKomIsMotorola" SG_ 69 WprWashSw_Psd 1;
BA_ "FlexKomSID" SG_ 69 WprWashSw_Psd 117440568;
BA_ "FlexKomSigLaenge" SG_ 69 WprWashSw_Psd 64;
BA_ "FlexKomSigName" SG_ 69 WprWashSw_Psd "StW_Actn_Rq";
BA_ "FlexKomSigStartPos" SG_ 69 WprWashSw_Psd 7;
BA_ "FlexKomSigStartValue" SG_ 69 WprWashSw_Psd "00FF0000000007FFh";
BA_ "GenSigCycleTime" SG_ 69 WprWashSw_Psd 100;
BA_ "GenSigSNA" SG_ 69 WprWashSw_Psd "3";
BA_ "GenSigSendType" SG_ 69 WprWashSw_Psd 5;
BA_ "GenSigTimeout_CGW" SG_ 69 WprWashSw_Psd 1050;
BA_ "GenSigTimeout_ESP_ABR" SG_ 69 WprWashSw_Psd 550;
BA_ "GenSigTimeout_MPC" SG_ 69 WprWashSw_Psd 1050;
BA_ "FlexKomComment" SG_ 69 WprWash_R_Sw_Posn_V2 "Steering wheel actuation request";
BA_ "FlexKomIsMotorola" SG_ 69 WprWash_R_Sw_Posn_V2 1;
BA_ "FlexKomSID" SG_ 69 WprWash_R_Sw_Posn_V2 117440568;
BA_ "FlexKomSigLaenge" SG_ 69 WprWash_R_Sw_Posn_V2 64;
BA_ "FlexKomSigName" SG_ 69 WprWash_R_Sw_Posn_V2 "StW_Actn_Rq";
BA_ "FlexKomSigStartPos" SG_ 69 WprWash_R_Sw_Posn_V2 7;
BA_ "FlexKomSigStartValue" SG_ 69 WprWash_R_Sw_Posn_V2 "00FF0000000007FFh";
BA_ "GenSigCycleTime" SG_ 69 WprWash_R_Sw_Posn_V2 100;
BA_ "GenSigSNA" SG_ 69 WprWash_R_Sw_Posn_V2 "3";
BA_ "GenSigSendType" SG_ 69 WprWash_R_Sw_Posn_V2 5;
BA_ "GenSigTimeout_CGW" SG_ 69 WprWash_R_Sw_Posn_V2 1050;
BA_ "GenSigTimeout_ESP_ABR" SG_ 69 WprWash_R_Sw_Posn_V2 550;
BA_ "FlexKomComment" SG_ 69 StW_Lvr_Stat "Steering wheel actuation request";
BA_ "FlexKomIsMotorola" SG_ 69 StW_Lvr_Stat 1;
BA_ "FlexKomSID" SG_ 69 StW_Lvr_Stat 117440568;
BA_ "FlexKomSigLaenge" SG_ 69 StW_Lvr_Stat 64;
BA_ "FlexKomSigName" SG_ 69 StW_Lvr_Stat "StW_Actn_Rq";
BA_ "FlexKomSigStartPos" SG_ 69 StW_Lvr_Stat 7;
BA_ "FlexKomSigStartValue" SG_ 69 StW_Lvr_Stat "00FF0000000007FFh";
BA_ "GenSigCycleTime" SG_ 69 StW_Lvr_Stat 100;
BA_ "GenSigSendType" SG_ 69 StW_Lvr_Stat 5;
BA_ "GenSigTimeout_CGW" SG_ 69 StW_Lvr_Stat 1050;
BA_ "GenSigTimeout_ESP_ABR" SG_ 69 StW_Lvr_Stat 550;
BA_ "GenSigTimeout_MPC" SG_ 69 StW_Lvr_Stat 1050;
BA_ "FlexKomComment" SG_ 69 StW_Cond_Flt "Steering wheel actuation request";
BA_ "FlexKomIsMotorola" SG_ 69 StW_Cond_Flt 1;
BA_ "FlexKomSID" SG_ 69 StW_Cond_Flt 117440568;
BA_ "FlexKomSigLaenge" SG_ 69 StW_Cond_Flt 64;
BA_ "FlexKomSigName" SG_ 69 StW_Cond_Flt "StW_Actn_Rq";
BA_ "FlexKomSigStartPos" SG_ 69 StW_Cond_Flt 7;
BA_ "FlexKomSigStartValue" SG_ 69 StW_Cond_Flt "00FF0000000007FFh";
BA_ "GenSigCycleTime" SG_ 69 StW_Cond_Flt 100;
BA_ "GenSigSendType" SG_ 69 StW_Cond_Flt 5;
BA_ "GenSigTimeout_CGW" SG_ 69 StW_Cond_Flt 1050;
BA_ "FlexKomComment" SG_ 69 StW_Cond_Psd "Steering wheel actuation request";
BA_ "FlexKomIsMotorola" SG_ 69 StW_Cond_Psd 1;
BA_ "FlexKomSID" SG_ 69 StW_Cond_Psd 117440568;
BA_ "FlexKomSigLaenge" SG_ 69 StW_Cond_Psd 64;
BA_ "FlexKomSigName" SG_ 69 StW_Cond_Psd "StW_Actn_Rq";
BA_ "FlexKomSigStartPos" SG_ 69 StW_Cond_Psd 7;
BA_ "FlexKomSigStartValue" SG_ 69 StW_Cond_Psd "00FF0000000007FFh";
BA_ "GenSigCycleTime" SG_ 69 StW_Cond_Psd 100;
BA_ "GenSigSNA" SG_ 69 StW_Cond_Psd "3";
BA_ "GenSigSendType" SG_ 69 StW_Cond_Psd 5;
BA_ "GenSigTimeout_CGW" SG_ 69 StW_Cond_Psd 1050;
BA_ "GenSigTimeout_ESP_ABR" SG_ 69 StW_Cond_Psd 550;
BA_ "GenSigTimeout_MPC" SG_ 69 StW_Cond_Psd 1050;
BA_ "FlexKomComment" SG_ 69 HrnSw_Psd "Steering wheel actuation request";
BA_ "FlexKomIsMotorola" SG_ 69 HrnSw_Psd 1;
BA_ "FlexKomSID" SG_ 69 HrnSw_Psd 117440568;
BA_ "FlexKomSigLaenge" SG_ 69 HrnSw_Psd 64;
BA_ "FlexKomSigName" SG_ 69 HrnSw_Psd "StW_Actn_Rq";
BA_ "FlexKomSigStartPos" SG_ 69 HrnSw_Psd 7;
BA_ "FlexKomSigStartValue" SG_ 69 HrnSw_Psd "00FF0000000007FFh";
BA_ "GenSigCycleTime" SG_ 69 HrnSw_Psd 100;
BA_ "GenSigSNA" SG_ 69 HrnSw_Psd "3";
BA_ "GenSigSendType" SG_ 69 HrnSw_Psd 5;
BA_ "GenSigTimeout_CGW" SG_ 69 HrnSw_Psd 1050;
BA_ "GenSigTimeout_ESP_ABR" SG_ 69 HrnSw_Psd 550;
BA_ "FlexKomComment" SG_ 69 StW_Sw00_Psd "Steering wheel actuation request";
BA_ "FlexKomIsMotorola" SG_ 69 StW_Sw00_Psd 1;
BA_ "FlexKomSID" SG_ 69 StW_Sw00_Psd 117440568;
BA_ "FlexKomSigLaenge" SG_ 69 StW_Sw00_Psd 64;
BA_ "FlexKomSigName" SG_ 69 StW_Sw00_Psd "StW_Actn_Rq";
BA_ "FlexKomSigStartPos" SG_ 69 StW_Sw00_Psd 7;
BA_ "FlexKomSigStartValue" SG_ 69 StW_Sw00_Psd "00FF0000000007FFh";
BA_ "GenSigCycleTime" SG_ 69 StW_Sw00_Psd 100;
BA_ "GenSigSendType" SG_ 69 StW_Sw00_Psd 5;
BA_ "GenSigTimeout_CGW" SG_ 69 StW_Sw00_Psd 1050;
BA_ "GenSigTimeout_ESP_ABR" SG_ 69 StW_Sw00_Psd 550;
BA_ "GenSigTimeout_IC" SG_ 69 StW_Sw00_Psd 1050;
BA_ "GenSigTimeout_MPC" SG_ 69 StW_Sw00_Psd 1050;
BA_ "FlexKomComment" SG_ 69 StW_Sw01_Psd "Steering wheel actuation request";
BA_ "FlexKomIsMotorola" SG_ 69 StW_Sw01_Psd 1;
BA_ "FlexKomSID" SG_ 69 StW_Sw01_Psd 117440568;
BA_ "FlexKomSigLaenge" SG_ 69 StW_Sw01_Psd 64;
BA_ "FlexKomSigName" SG_ 69 StW_Sw01_Psd "StW_Actn_Rq";
BA_ "FlexKomSigStartPos" SG_ 69 StW_Sw01_Psd 7;
BA_ "FlexKomSigStartValue" SG_ 69 StW_Sw01_Psd "00FF0000000007FFh";
BA_ "GenSigCycleTime" SG_ 69 StW_Sw01_Psd 100;
BA_ "GenSigSendType" SG_ 69 StW_Sw01_Psd 5;
BA_ "GenSigTimeout_CGW" SG_ 69 StW_Sw01_Psd 1050;
BA_ "GenSigTimeout_ESP_ABR" SG_ 69 StW_Sw01_Psd 550;
BA_ "GenSigTimeout_IC" SG_ 69 StW_Sw01_Psd 1050;
BA_ "GenSigTimeout_MPC" SG_ 69 StW_Sw01_Psd 1050;
BA_ "FlexKomComment" SG_ 69 StW_Sw02_Psd "Steering wheel actuation request";
BA_ "FlexKomIsMotorola" SG_ 69 StW_Sw02_Psd 1;
BA_ "FlexKomSID" SG_ 69 StW_Sw02_Psd 117440568;
BA_ "FlexKomSigLaenge" SG_ 69 StW_Sw02_Psd 64;
BA_ "FlexKomSigName" SG_ 69 StW_Sw02_Psd "StW_Actn_Rq";
BA_ "FlexKomSigStartPos" SG_ 69 StW_Sw02_Psd 7;
BA_ "FlexKomSigStartValue" SG_ 69 StW_Sw02_Psd "00FF0000000007FFh";
BA_ "GenSigCycleTime" SG_ 69 StW_Sw02_Psd 100;
BA_ "GenSigSendType" SG_ 69 StW_Sw02_Psd 5;
BA_ "GenSigTimeout_CGW" SG_ 69 StW_Sw02_Psd 1050;
BA_ "GenSigTimeout_ESP_ABR" SG_ 69 StW_Sw02_Psd 550;
BA_ "GenSigTimeout_IC" SG_ 69 StW_Sw02_Psd 1050;
BA_ "GenSigTimeout_MPC" SG_ 69 StW_Sw02_Psd 1050;
BA_ "FlexKomComment" SG_ 69 StW_Sw03_Psd "Steering wheel actuation request";
BA_ "FlexKomIsMotorola" SG_ 69 StW_Sw03_Psd 1;
BA_ "FlexKomSID" SG_ 69 StW_Sw03_Psd 117440568;
BA_ "FlexKomSigLaenge" SG_ 69 StW_Sw03_Psd 64;
BA_ "FlexKomSigName" SG_ 69 StW_Sw03_Psd "StW_Actn_Rq";
BA_ "FlexKomSigStartPos" SG_ 69 StW_Sw03_Psd 7;
BA_ "FlexKomSigStartValue" SG_ 69 StW_Sw03_Psd "00FF0000000007FFh";
BA_ "GenSigCycleTime" SG_ 69 StW_Sw03_Psd 100;
BA_ "GenSigSendType" SG_ 69 StW_Sw03_Psd 5;
BA_ "GenSigTimeout_CGW" SG_ 69 StW_Sw03_Psd 1050;
BA_ "GenSigTimeout_ESP_ABR" SG_ 69 StW_Sw03_Psd 550;
BA_ "GenSigTimeout_IC" SG_ 69 StW_Sw03_Psd 1050;
BA_ "GenSigTimeout_MPC" SG_ 69 StW_Sw03_Psd 1050;
BA_ "FlexKomComment" SG_ 69 StW_Sw04_Psd "Steering wheel actuation request";
BA_ "FlexKomIsMotorola" SG_ 69 StW_Sw04_Psd 1;
BA_ "FlexKomSID" SG_ 69 StW_Sw04_Psd 117440568;
BA_ "FlexKomSigLaenge" SG_ 69 StW_Sw04_Psd 64;
BA_ "FlexKomSigName" SG_ 69 StW_Sw04_Psd "StW_Actn_Rq";
BA_ "FlexKomSigStartPos" SG_ 69 StW_Sw04_Psd 7;
BA_ "FlexKomSigStartValue" SG_ 69 StW_Sw04_Psd "00FF0000000007FFh";
BA_ "GenSigCycleTime" SG_ 69 StW_Sw04_Psd 100;
BA_ "GenSigSendType" SG_ 69 StW_Sw04_Psd 5;
BA_ "GenSigTimeout_CGW" SG_ 69 StW_Sw04_Psd 1050;
BA_ "GenSigTimeout_ESP_ABR" SG_ 69 StW_Sw04_Psd 550;
BA_ "GenSigTimeout_IC" SG_ 69 StW_Sw04_Psd 1050;
BA_ "GenSigTimeout_MPC" SG_ 69 StW_Sw04_Psd 1050;
BA_ "FlexKomComment" SG_ 69 StW_Sw05_Psd "Steering wheel actuation request";
BA_ "FlexKomIsMotorola" SG_ 69 StW_Sw05_Psd 1;
BA_ "FlexKomSID" SG_ 69 StW_Sw05_Psd 117440568;
BA_ "FlexKomSigLaenge" SG_ 69 StW_Sw05_Psd 64;
BA_ "FlexKomSigName" SG_ 69 StW_Sw05_Psd "StW_Actn_Rq";
BA_ "FlexKomSigStartPos" SG_ 69 StW_Sw05_Psd 7;
BA_ "FlexKomSigStartValue" SG_ 69 StW_Sw05_Psd "00FF0000000007FFh";
BA_ "GenSigCycleTime" SG_ 69 StW_Sw05_Psd 100;
BA_ "GenSigSendType" SG_ 69 StW_Sw05_Psd 5;
BA_ "GenSigTimeout_CGW" SG_ 69 StW_Sw05_Psd 1050;
BA_ "GenSigTimeout_ESP_ABR" SG_ 69 StW_Sw05_Psd 550;
BA_ "GenSigTimeout_IC" SG_ 69 StW_Sw05_Psd 1050;
BA_ "GenSigTimeout_MPC" SG_ 69 StW_Sw05_Psd 1050;
BA_ "FlexKomComment" SG_ 69 StW_Sw06_Psd "Steering wheel actuation request";
BA_ "FlexKomIsMotorola" SG_ 69 StW_Sw06_Psd 1;
BA_ "FlexKomSID" SG_ 69 StW_Sw06_Psd 117440568;
BA_ "FlexKomSigLaenge" SG_ 69 StW_Sw06_Psd 64;
BA_ "FlexKomSigName" SG_ 69 StW_Sw06_Psd "StW_Actn_Rq";
BA_ "FlexKomSigStartPos" SG_ 69 StW_Sw06_Psd 7;
BA_ "FlexKomSigStartValue" SG_ 69 StW_Sw06_Psd "00FF0000000007FFh";
BA_ "GenSigCycleTime" SG_ 69 StW_Sw06_Psd 100;
BA_ "GenSigSendType" SG_ 69 StW_Sw06_Psd 5;
BA_ "GenSigTimeout_CGW" SG_ 69 StW_Sw06_Psd 1050;
BA_ "GenSigTimeout_ESP_ABR" SG_ 69 StW_Sw06_Psd 550;
BA_ "GenSigTimeout_IC" SG_ 69 StW_Sw06_Psd 1050;
BA_ "GenSigTimeout_MPC" SG_ 69 StW_Sw06_Psd 1050;
BA_ "FlexKomComment" SG_ 69 StW_Sw07_Psd "Steering wheel actuation request";
BA_ "FlexKomIsMotorola" SG_ 69 StW_Sw07_Psd 1;
BA_ "FlexKomSID" SG_ 69 StW_Sw07_Psd 117440568;
BA_ "FlexKomSigLaenge" SG_ 69 StW_Sw07_Psd 64;
BA_ "FlexKomSigName" SG_ 69 StW_Sw07_Psd "StW_Actn_Rq";
BA_ "FlexKomSigStartPos" SG_ 69 StW_Sw07_Psd 7;
BA_ "FlexKomSigStartValue" SG_ 69 StW_Sw07_Psd "00FF0000000007FFh";
BA_ "GenSigCycleTime" SG_ 69 StW_Sw07_Psd 100;
BA_ "GenSigSendType" SG_ 69 StW_Sw07_Psd 5;
BA_ "GenSigTimeout_CGW" SG_ 69 StW_Sw07_Psd 1050;
BA_ "GenSigTimeout_ESP_ABR" SG_ 69 StW_Sw07_Psd 550;
BA_ "GenSigTimeout_IC" SG_ 69 StW_Sw07_Psd 1050;
BA_ "GenSigTimeout_MPC" SG_ 69 StW_Sw07_Psd 1050;
BA_ "FlexKomComment" SG_ 69 StW_Sw08_Psd "Steering wheel actuation request";
BA_ "FlexKomIsMotorola" SG_ 69 StW_Sw08_Psd 1;
BA_ "FlexKomSID" SG_ 69 StW_Sw08_Psd 117440568;
BA_ "FlexKomSigLaenge" SG_ 69 StW_Sw08_Psd 64;
BA_ "FlexKomSigName" SG_ 69 StW_Sw08_Psd "StW_Actn_Rq";
BA_ "FlexKomSigStartPos" SG_ 69 StW_Sw08_Psd 7;
BA_ "FlexKomSigStartValue" SG_ 69 StW_Sw08_Psd "00FF0000000007FFh";
BA_ "GenSigCycleTime" SG_ 69 StW_Sw08_Psd 100;
BA_ "GenSigSendType" SG_ 69 StW_Sw08_Psd 5;
BA_ "GenSigTimeout_CGW" SG_ 69 StW_Sw08_Psd 1050;
BA_ "GenSigTimeout_ESP_ABR" SG_ 69 StW_Sw08_Psd 550;
BA_ "GenSigTimeout_IC" SG_ 69 StW_Sw08_Psd 1050;
BA_ "GenSigTimeout_MPC" SG_ 69 StW_Sw08_Psd 1050;
BA_ "FlexKomComment" SG_ 69 StW_Sw09_Psd "Steering wheel actuation request";
BA_ "FlexKomIsMotorola" SG_ 69 StW_Sw09_Psd 1;
BA_ "FlexKomSID" SG_ 69 StW_Sw09_Psd 117440568;
BA_ "FlexKomSigLaenge" SG_ 69 StW_Sw09_Psd 64;
BA_ "FlexKomSigName" SG_ 69 StW_Sw09_Psd "StW_Actn_Rq";
BA_ "FlexKomSigStartPos" SG_ 69 StW_Sw09_Psd 7;
BA_ "FlexKomSigStartValue" SG_ 69 StW_Sw09_Psd "00FF0000000007FFh";
BA_ "GenSigCycleTime" SG_ 69 StW_Sw09_Psd 100;
BA_ "GenSigSendType" SG_ 69 StW_Sw09_Psd 5;
BA_ "GenSigTimeout_CGW" SG_ 69 StW_Sw09_Psd 1050;
BA_ "GenSigTimeout_ESP_ABR" SG_ 69 StW_Sw09_Psd 550;
BA_ "GenSigTimeout_IC" SG_ 69 StW_Sw09_Psd 1050;
BA_ "GenSigTimeout_MPC" SG_ 69 StW_Sw09_Psd 1050;
BA_ "FlexKomComment" SG_ 69 StW_Sw10_Psd "Steering wheel actuation request";
BA_ "FlexKomIsMotorola" SG_ 69 StW_Sw10_Psd 1;
BA_ "FlexKomSID" SG_ 69 StW_Sw10_Psd 117440568;
BA_ "FlexKomSigLaenge" SG_ 69 StW_Sw10_Psd 64;
BA_ "FlexKomSigName" SG_ 69 StW_Sw10_Psd "StW_Actn_Rq";
BA_ "FlexKomSigStartPos" SG_ 69 StW_Sw10_Psd 7;
BA_ "FlexKomSigStartValue" SG_ 69 StW_Sw10_Psd "00FF0000000007FFh";
BA_ "GenSigCycleTime" SG_ 69 StW_Sw10_Psd 100;
BA_ "GenSigSendType" SG_ 69 StW_Sw10_Psd 5;
BA_ "GenSigTimeout_CGW" SG_ 69 StW_Sw10_Psd 1050;
BA_ "GenSigTimeout_ESP_ABR" SG_ 69 StW_Sw10_Psd 550;
BA_ "GenSigTimeout_IC" SG_ 69 StW_Sw10_Psd 1050;
BA_ "GenSigTimeout_MPC" SG_ 69 StW_Sw10_Psd 1050;
BA_ "FlexKomComment" SG_ 69 StW_Sw11_Psd "Steering wheel actuation request";
BA_ "FlexKomIsMotorola" SG_ 69 StW_Sw11_Psd 1;
BA_ "FlexKomSID" SG_ 69 StW_Sw11_Psd 117440568;
BA_ "FlexKomSigLaenge" SG_ 69 StW_Sw11_Psd 64;
BA_ "FlexKomSigName" SG_ 69 StW_Sw11_Psd "StW_Actn_Rq";
BA_ "FlexKomSigStartPos" SG_ 69 StW_Sw11_Psd 7;
BA_ "FlexKomSigStartValue" SG_ 69 StW_Sw11_Psd "00FF0000000007FFh";
BA_ "GenSigCycleTime" SG_ 69 StW_Sw11_Psd 100;
BA_ "GenSigSendType" SG_ 69 StW_Sw11_Psd 5;
BA_ "GenSigTimeout_CGW" SG_ 69 StW_Sw11_Psd 1050;
BA_ "GenSigTimeout_ESP_ABR" SG_ 69 StW_Sw11_Psd 550;
BA_ "GenSigTimeout_IC" SG_ 69 StW_Sw11_Psd 1050;
BA_ "GenSigTimeout_MPC" SG_ 69 StW_Sw11_Psd 1050;
BA_ "FlexKomComment" SG_ 69 StW_Sw12_Psd "Steering wheel actuation request";
BA_ "FlexKomIsMotorola" SG_ 69 StW_Sw12_Psd 1;
BA_ "FlexKomSID" SG_ 69 StW_Sw12_Psd 117440568;
BA_ "FlexKomSigLaenge" SG_ 69 StW_Sw12_Psd 64;
BA_ "FlexKomSigName" SG_ 69 StW_Sw12_Psd "StW_Actn_Rq";
BA_ "FlexKomSigStartPos" SG_ 69 StW_Sw12_Psd 7;
BA_ "FlexKomSigStartValue" SG_ 69 StW_Sw12_Psd "00FF0000000007FFh";
BA_ "GenSigCycleTime" SG_ 69 StW_Sw12_Psd 100;
BA_ "GenSigSendType" SG_ 69 StW_Sw12_Psd 5;
BA_ "GenSigTimeout_CGW" SG_ 69 StW_Sw12_Psd 1050;
BA_ "GenSigTimeout_ESP_ABR" SG_ 69 StW_Sw12_Psd 550;
BA_ "GenSigTimeout_IC" SG_ 69 StW_Sw12_Psd 1050;
BA_ "GenSigTimeout_MPC" SG_ 69 StW_Sw12_Psd 1050;
BA_ "FlexKomComment" SG_ 69 StW_Sw13_Psd "Steering wheel actuation request";
BA_ "FlexKomIsMotorola" SG_ 69 StW_Sw13_Psd 1;
BA_ "FlexKomSID" SG_ 69 StW_Sw13_Psd 117440568;
BA_ "FlexKomSigLaenge" SG_ 69 StW_Sw13_Psd 64;
BA_ "FlexKomSigName" SG_ 69 StW_Sw13_Psd "StW_Actn_Rq";
BA_ "FlexKomSigStartPos" SG_ 69 StW_Sw13_Psd 7;
BA_ "FlexKomSigStartValue" SG_ 69 StW_Sw13_Psd "00FF0000000007FFh";
BA_ "GenSigCycleTime" SG_ 69 StW_Sw13_Psd 100;
BA_ "GenSigSendType" SG_ 69 StW_Sw13_Psd 5;
BA_ "GenSigTimeout_CGW" SG_ 69 StW_Sw13_Psd 1050;
BA_ "GenSigTimeout_ESP_ABR" SG_ 69 StW_Sw13_Psd 550;
BA_ "GenSigTimeout_IC" SG_ 69 StW_Sw13_Psd 1050;
BA_ "GenSigTimeout_MPC" SG_ 69 StW_Sw13_Psd 1050;
BA_ "FlexKomComment" SG_ 69 StW_Sw14_Psd "Steering wheel actuation request";
BA_ "FlexKomIsMotorola" SG_ 69 StW_Sw14_Psd 1;
BA_ "FlexKomSID" SG_ 69 StW_Sw14_Psd 117440568;
BA_ "FlexKomSigLaenge" SG_ 69 StW_Sw14_Psd 64;
BA_ "FlexKomSigName" SG_ 69 StW_Sw14_Psd "StW_Actn_Rq";
BA_ "FlexKomSigStartPos" SG_ 69 StW_Sw14_Psd 7;
BA_ "FlexKomSigStartValue" SG_ 69 StW_Sw14_Psd "00FF0000000007FFh";
BA_ "GenSigCycleTime" SG_ 69 StW_Sw14_Psd 100;
BA_ "GenSigSendType" SG_ 69 StW_Sw14_Psd 5;
BA_ "GenSigTimeout_CGW" SG_ 69 StW_Sw14_Psd 1050;
BA_ "GenSigTimeout_ESP_ABR" SG_ 69 StW_Sw14_Psd 550;
BA_ "GenSigTimeout_IC" SG_ 69 StW_Sw14_Psd 1050;
BA_ "GenSigTimeout_MPC" SG_ 69 StW_Sw14_Psd 1050;
BA_ "FlexKomComment" SG_ 69 StW_Sw15_Psd "Steering wheel actuation request";
BA_ "FlexKomIsMotorola" SG_ 69 StW_Sw15_Psd 1;
BA_ "FlexKomSID" SG_ 69 StW_Sw15_Psd 117440568;
BA_ "FlexKomSigLaenge" SG_ 69 StW_Sw15_Psd 64;
BA_ "FlexKomSigName" SG_ 69 StW_Sw15_Psd "StW_Actn_Rq";
BA_ "FlexKomSigStartPos" SG_ 69 StW_Sw15_Psd 7;
BA_ "FlexKomSigStartValue" SG_ 69 StW_Sw15_Psd "00FF0000000007FFh";
BA_ "GenSigCycleTime" SG_ 69 StW_Sw15_Psd 100;
BA_ "GenSigSendType" SG_ 69 StW_Sw15_Psd 5;
BA_ "GenSigTimeout_CGW" SG_ 69 StW_Sw15_Psd 1050;
BA_ "GenSigTimeout_ESP_ABR" SG_ 69 StW_Sw15_Psd 550;
BA_ "GenSigTimeout_IC" SG_ 69 StW_Sw15_Psd 1050;
BA_ "GenSigTimeout_MPC" SG_ 69 StW_Sw15_Psd 1050;
BA_ "FlexKomComment" SG_ 69 WprSw6Posn "Steering wheel actuation request";
BA_ "FlexKomIsMotorola" SG_ 69 WprSw6Posn 1;
BA_ "FlexKomSID" SG_ 69 WprSw6Posn 117440568;
BA_ "FlexKomSigLaenge" SG_ 69 WprSw6Posn 64;
BA_ "FlexKomSigName" SG_ 69 WprSw6Posn "StW_Actn_Rq";
BA_ "FlexKomSigStartPos" SG_ 69 WprSw6Posn 7;
BA_ "FlexKomSigStartValue" SG_ 69 WprSw6Posn "00FF0000000007FFh";
BA_ "GenSigCycleTime" SG_ 69 WprSw6Posn 100;
BA_ "GenSigSNA" SG_ 69 WprSw6Posn "7";
BA_ "GenSigSendType" SG_ 69 WprSw6Posn 5;
BA_ "GenSigStartValue" SG_ 69 WprSw6Posn 7;
BA_ "GenSigTimeout_CGW" SG_ 69 WprSw6Posn 1050;
BA_ "GenSigTimeout_ESP_ABR" SG_ 69 WprSw6Posn 550;
BA_ "GenSigTimeout_MPC" SG_ 69 WprSw6Posn 1050;
BA_ "FlexKomComment" SG_ 69 MC_STW_ACTN_RQ "Steering wheel actuation request";
BA_ "FlexKomIsMotorola" SG_ 69 MC_STW_ACTN_RQ 1;
BA_ "FlexKomSID" SG_ 69 MC_STW_ACTN_RQ 117440568;
BA_ "FlexKomSigLaenge" SG_ 69 MC_STW_ACTN_RQ 64;
BA_ "FlexKomSigName" SG_ 69 MC_STW_ACTN_RQ "StW_Actn_Rq";
BA_ "FlexKomSigStartPos" SG_ 69 MC_STW_ACTN_RQ 7;
BA_ "FlexKomSigStartValue" SG_ 69 MC_STW_ACTN_RQ "00FF0000000007FFh";
BA_ "GenSigSendType" SG_ 69 MC_STW_ACTN_RQ 10;
BA_ "GenSigTimeout_CGW" SG_ 69 MC_STW_ACTN_RQ 1050;
BA_ "GenSigTimeout_ESP_ABR" SG_ 69 MC_STW_ACTN_RQ 550;
BA_ "GenSigTimeout_IC" SG_ 69 MC_STW_ACTN_RQ 1050;
BA_ "GenSigTimeout_MPC" SG_ 69 MC_STW_ACTN_RQ 1050;
BA_ "FlexKomComment" SG_ 69 CRC_STW_ACTN_RQ "Steering wheel actuation request";
BA_ "FlexKomIsMotorola" SG_ 69 CRC_STW_ACTN_RQ 1;
BA_ "FlexKomSID" SG_ 69 CRC_STW_ACTN_RQ 117440568;
BA_ "FlexKomSigLaenge" SG_ 69 CRC_STW_ACTN_RQ 64;
BA_ "FlexKomSigName" SG_ 69 CRC_STW_ACTN_RQ "StW_Actn_Rq";
BA_ "FlexKomSigStartPos" SG_ 69 CRC_STW_ACTN_RQ 7;
BA_ "FlexKomSigStartValue" SG_ 69 CRC_STW_ACTN_RQ "00FF0000000007FFh";
BA_ "GenSigSendType" SG_ 69 CRC_STW_ACTN_RQ 10;
BA_ "GenSigStartValue" SG_ 69 CRC_STW_ACTN_RQ 255;
BA_ "GenSigTimeout_CGW" SG_ 69 CRC_STW_ACTN_RQ 1050;
BA_ "GenSigTimeout_ESP_ABR" SG_ 69 CRC_STW_ACTN_RQ 550;
BA_ "GenSigTimeout_IC" SG_ 69 CRC_STW_ACTN_RQ 1050;
BA_ "GenSigTimeout_MPC" SG_ 69 CRC_STW_ACTN_RQ 1050;
BA_ "FlexKomComment" SG_ 14 StW_AnglHP "Steering wheel angle with high precision state";
BA_ "FlexKomIsMotorola" SG_ 14 StW_AnglHP 1;
BA_ "FlexKomSID" SG_ 14 StW_AnglHP 117443381;
BA_ "FlexKomSigLaenge" SG_ 14 StW_AnglHP 64;
BA_ "FlexKomSigName" SG_ 14 StW_AnglHP "StW_AnglHP_Stat";
BA_ "FlexKomSigStartPos" SG_ 14 StW_AnglHP 7;
BA_ "FlexKomSigStartValue" SG_ 14 StW_AnglHP "3FFF3FFF03FF00FFh";
BA_ "GenSigCycleTime" SG_ 14 StW_AnglHP 10;
BA_ "GenSigSNA" SG_ 14 StW_AnglHP "16383";
BA_ "GenSigStartValue" SG_ 14 StW_AnglHP 16383;
BA_ "GenSigTimeout_ESP_ABR" SG_ 14 StW_AnglHP 155;
BA_ "LogSignal" SG_ 14 StW_AnglHP "periodic POINT_NINE_SECONDS driveModeModelS";
BA_ "FlexKomComment" SG_ 14 StW_AnglHP_Spd "Steering wheel angle with high precision state";
BA_ "FlexKomIsMotorola" SG_ 14 StW_AnglHP_Spd 1;
BA_ "FlexKomSID" SG_ 14 StW_AnglHP_Spd 117443381;
BA_ "FlexKomSigLaenge" SG_ 14 StW_AnglHP_Spd 64;
BA_ "FlexKomSigName" SG_ 14 StW_AnglHP_Spd "StW_AnglHP_Stat";
BA_ "FlexKomSigStartPos" SG_ 14 StW_AnglHP_Spd 7;
BA_ "FlexKomSigStartValue" SG_ 14 StW_AnglHP_Spd "3FFF3FFF03FF00FFh";
BA_ "GenSigCycleTime" SG_ 14 StW_AnglHP_Spd 10;
BA_ "GenSigSNA" SG_ 14 StW_AnglHP_Spd "16383";
BA_ "GenSigStartValue" SG_ 14 StW_AnglHP_Spd 8192;
BA_ "GenSigTimeout_ESP_ABR" SG_ 14 StW_AnglHP_Spd 155;
BA_ "FlexKomComment" SG_ 14 StW_AnglHP_Sens_Stat "Steering wheel angle with high precision state";
BA_ "FlexKomIsMotorola" SG_ 14 StW_AnglHP_Sens_Stat 1;
BA_ "FlexKomSID" SG_ 14 StW_AnglHP_Sens_Stat 117443381;
BA_ "FlexKomSigLaenge" SG_ 14 StW_AnglHP_Sens_Stat 64;
BA_ "FlexKomSigName" SG_ 14 StW_AnglHP_Sens_Stat "StW_AnglHP_Stat";
BA_ "FlexKomSigStartPos" SG_ 14 StW_AnglHP_Sens_Stat 7;
BA_ "FlexKomSigStartValue" SG_ 14 StW_AnglHP_Sens_Stat "3FFF3FFF03FF00FFh";
BA_ "GenSigCycleTime" SG_ 14 StW_AnglHP_Sens_Stat 10;
BA_ "GenSigSNA" SG_ 14 StW_AnglHP_Sens_Stat "3";
BA_ "GenSigStartValue" SG_ 14 StW_AnglHP_Sens_Stat 3;
BA_ "GenSigTimeout_ESP_ABR" SG_ 14 StW_AnglHP_Sens_Stat 155;
BA_ "LogSignal" SG_ 14 StW_AnglHP_Sens_Stat "onChange";
BA_ "FlexKomComment" SG_ 14 StW_AnglHP_Sens_Id "Steering wheel angle with high precision state";
BA_ "FlexKomIsMotorola" SG_ 14 StW_AnglHP_Sens_Id 1;
BA_ "FlexKomSID" SG_ 14 StW_AnglHP_Sens_Id 117443381;
BA_ "FlexKomSigLaenge" SG_ 14 StW_AnglHP_Sens_Id 64;
BA_ "FlexKomSigName" SG_ 14 StW_AnglHP_Sens_Id "StW_AnglHP_Stat";
BA_ "FlexKomSigStartPos" SG_ 14 StW_AnglHP_Sens_Id 7;
BA_ "FlexKomSigStartValue" SG_ 14 StW_AnglHP_Sens_Id "3FFF3FFF03FF00FFh";
BA_ "GenSigCycleTime" SG_ 14 StW_AnglHP_Sens_Id 10;
BA_ "GenSigSNA" SG_ 14 StW_AnglHP_Sens_Id "3";
BA_ "GenSigTimeout_ESP_ABR" SG_ 14 StW_AnglHP_Sens_Id 155;
BA_ "FlexKomComment" SG_ 14 MC_STW_ANGLHP_STAT "Steering wheel angle with high precision state";
BA_ "FlexKomIsMotorola" SG_ 14 MC_STW_ANGLHP_STAT 1;
BA_ "FlexKomSID" SG_ 14 MC_STW_ANGLHP_STAT 117443381;
BA_ "FlexKomSigLaenge" SG_ 14 MC_STW_ANGLHP_STAT 64;
BA_ "FlexKomSigName" SG_ 14 MC_STW_ANGLHP_STAT "StW_AnglHP_Stat";
BA_ "FlexKomSigStartPos" SG_ 14 MC_STW_ANGLHP_STAT 7;
BA_ "FlexKomSigStartValue" SG_ 14 MC_STW_ANGLHP_STAT "3FFF3FFF03FF00FFh";
BA_ "GenSigCycleTime" SG_ 14 MC_STW_ANGLHP_STAT 10;
BA_ "FlexKomComment" SG_ 14 CRC_STW_ANGLHP_STAT "Steering wheel angle with high precision state";
BA_ "FlexKomIsMotorola" SG_ 14 CRC_STW_ANGLHP_STAT 1;
BA_ "FlexKomSID" SG_ 14 CRC_STW_ANGLHP_STAT 117443381;
BA_ "FlexKomSigLaenge" SG_ 14 CRC_STW_ANGLHP_STAT 64;
BA_ "FlexKomSigName" SG_ 14 CRC_STW_ANGLHP_STAT "StW_AnglHP_Stat";
BA_ "FlexKomSigStartPos" SG_ 14 CRC_STW_ANGLHP_STAT 7;
BA_ "FlexKomSigStartValue" SG_ 14 CRC_STW_ANGLHP_STAT "3FFF3FFF03FF00FFh";
BA_ "GenSigCycleTime" SG_ 14 CRC_STW_ANGLHP_STAT 10;
BA_ "GenSigStartValue" SG_ 14 CRC_STW_ANGLHP_STAT 255;
BA_ "FlexKomComment" SG_ 3 StW_Angl "Steering wheel angle state";
BA_ "FlexKomIsMotorola" SG_ 3 StW_Angl 1;
BA_ "FlexKomSID" SG_ 3 StW_Angl 117440569;
BA_ "FlexKomSigLaenge" SG_ 3 StW_Angl 64;
BA_ "FlexKomSigName" SG_ 3 StW_Angl "StW_Angl_Stat";
BA_ "FlexKomSigStartPos" SG_ 3 StW_Angl 7;
BA_ "FlexKomSigStartValue" SG_ 3 StW_Angl "3FFF3FFF03FF00FFh";
BA_ "GenSigCycleTime" SG_ 3 StW_Angl 10;
BA_ "GenSigSNA" SG_ 3 StW_Angl "16383";
BA_ "GenSigStartValue" SG_ 3 StW_Angl 16383;
BA_ "GenSigTimeout_CGW" SG_ 3 StW_Angl 105;
BA_ "GenSigTimeout_ECM" SG_ 3 StW_Angl 205;
BA_ "GenSigTimeout_ESP_ABR" SG_ 3 StW_Angl 155;
BA_ "GenSigTimeout_MPC" SG_ 3 StW_Angl 105;
BA_ "GenSigTimeout_PTS" SG_ 3 StW_Angl 105;
BA_ "GenSigTimeout_SPC" SG_ 3 StW_Angl 105;
BA_ "FlexKomComment" SG_ 3 StW_AnglSpd "Steering wheel angle state";
BA_ "FlexKomIsMotorola" SG_ 3 StW_AnglSpd 1;
BA_ "FlexKomSID" SG_ 3 StW_AnglSpd 117440569;
BA_ "FlexKomSigLaenge" SG_ 3 StW_AnglSpd 64;
BA_ "FlexKomSigName" SG_ 3 StW_AnglSpd "StW_Angl_Stat";
BA_ "FlexKomSigStartPos" SG_ 3 StW_AnglSpd 7;
BA_ "FlexKomSigStartValue" SG_ 3 StW_AnglSpd "3FFF3FFF03FF00FFh";
BA_ "GenSigCycleTime" SG_ 3 StW_AnglSpd 10;
BA_ "GenSigSNA" SG_ 3 StW_AnglSpd "16383";
BA_ "GenSigStartValue" SG_ 3 StW_AnglSpd 16383;
BA_ "GenSigTimeout_CGW" SG_ 3 StW_AnglSpd 105;
BA_ "GenSigTimeout_ECM" SG_ 3 StW_AnglSpd 205;
BA_ "GenSigTimeout_ESP_ABR" SG_ 3 StW_AnglSpd 155;
BA_ "GenSigTimeout_MPC" SG_ 3 StW_AnglSpd 105;
BA_ "GenSigTimeout_SPC" SG_ 3 StW_AnglSpd 105;
BA_ "FlexKomComment" SG_ 3 StW_AnglSens_Stat "Steering wheel angle state";
BA_ "FlexKomIsMotorola" SG_ 3 StW_AnglSens_Stat 1;
BA_ "FlexKomSID" SG_ 3 StW_AnglSens_Stat 117440569;
BA_ "FlexKomSigLaenge" SG_ 3 StW_AnglSens_Stat 64;
BA_ "FlexKomSigName" SG_ 3 StW_AnglSens_Stat "StW_Angl_Stat";
BA_ "FlexKomSigStartPos" SG_ 3 StW_AnglSens_Stat 7;
BA_ "FlexKomSigStartValue" SG_ 3 StW_AnglSens_Stat "3FFF3FFF03FF00FFh";
BA_ "GenSigCycleTime" SG_ 3 StW_AnglSens_Stat 10;
BA_ "GenSigSNA" SG_ 3 StW_AnglSens_Stat "3";
BA_ "GenSigStartValue" SG_ 3 StW_AnglSens_Stat 3;
BA_ "GenSigTimeout_CGW" SG_ 3 StW_AnglSens_Stat 105;
BA_ "GenSigTimeout_ECM" SG_ 3 StW_AnglSens_Stat 205;
BA_ "GenSigTimeout_ESP_ABR" SG_ 3 StW_AnglSens_Stat 155;
BA_ "GenSigTimeout_MPC" SG_ 3 StW_AnglSens_Stat 105;
BA_ "GenSigTimeout_SPC" SG_ 3 StW_AnglSens_Stat 105;
BA_ "FlexKomComment" SG_ 3 StW_AnglSens_Id "Steering wheel angle state";
BA_ "FlexKomIsMotorola" SG_ 3 StW_AnglSens_Id 1;
BA_ "FlexKomSID" SG_ 3 StW_AnglSens_Id 117440569;
BA_ "FlexKomSigLaenge" SG_ 3 StW_AnglSens_Id 64;
BA_ "FlexKomSigName" SG_ 3 StW_AnglSens_Id "StW_Angl_Stat";
BA_ "FlexKomSigStartPos" SG_ 3 StW_AnglSens_Id 7;
BA_ "FlexKomSigStartValue" SG_ 3 StW_AnglSens_Id "3FFF3FFF03FF00FFh";
BA_ "GenSigCycleTime" SG_ 3 StW_AnglSens_Id 10;
BA_ "GenSigTimeout_CGW" SG_ 3 StW_AnglSens_Id 105;
BA_ "GenSigTimeout_ECM" SG_ 3 StW_AnglSens_Id 205;
BA_ "GenSigTimeout_MPC" SG_ 3 StW_AnglSens_Id 105;
BA_ "FlexKomComment" SG_ 3 MC_STW_ANGL_STAT "Steering wheel angle state";
BA_ "FlexKomIsMotorola" SG_ 3 MC_STW_ANGL_STAT 1;
BA_ "FlexKomSID" SG_ 3 MC_STW_ANGL_STAT 117440569;
BA_ "FlexKomSigLaenge" SG_ 3 MC_STW_ANGL_STAT 64;
BA_ "FlexKomSigName" SG_ 3 MC_STW_ANGL_STAT "StW_Angl_Stat";
BA_ "FlexKomSigStartPos" SG_ 3 MC_STW_ANGL_STAT 7;
BA_ "FlexKomSigStartValue" SG_ 3 MC_STW_ANGL_STAT "3FFF3FFF03FF00FFh";
BA_ "GenSigCycleTime" SG_ 3 MC_STW_ANGL_STAT 10;
BA_ "GenSigTimeout_CGW" SG_ 3 MC_STW_ANGL_STAT 105;
BA_ "GenSigTimeout_ECM" SG_ 3 MC_STW_ANGL_STAT 205;
BA_ "GenSigTimeout_ESP_ABR" SG_ 3 MC_STW_ANGL_STAT 155;
BA_ "GenSigTimeout_MPC" SG_ 3 MC_STW_ANGL_STAT 105;
BA_ "FlexKomComment" SG_ 3 CRC_STW_ANGL_STAT "Steering wheel angle state";
BA_ "FlexKomIsMotorola" SG_ 3 CRC_STW_ANGL_STAT 1;
BA_ "FlexKomSID" SG_ 3 CRC_STW_ANGL_STAT 117440569;
BA_ "FlexKomSigLaenge" SG_ 3 CRC_STW_ANGL_STAT 64;
BA_ "FlexKomSigName" SG_ 3 CRC_STW_ANGL_STAT "StW_Angl_Stat";
BA_ "FlexKomSigStartPos" SG_ 3 CRC_STW_ANGL_STAT 7;
BA_ "FlexKomSigStartValue" SG_ 3 CRC_STW_ANGL_STAT "3FFF3FFF03FF00FFh";
BA_ "GenSigCycleTime" SG_ 3 CRC_STW_ANGL_STAT 10;
BA_ "GenSigStartValue" SG_ 3 CRC_STW_ANGL_STAT 255;
BA_ "GenSigTimeout_CGW" SG_ 3 CRC_STW_ANGL_STAT 105;
BA_ "GenSigTimeout_ECM" SG_ 3 CRC_STW_ANGL_STAT 205;
BA_ "GenSigTimeout_ESP_ABR" SG_ 3 CRC_STW_ANGL_STAT 155;
BA_ "GenSigTimeout_MPC" SG_ 3 CRC_STW_ANGL_STAT 105;
BA_ "FieldType" SG_ 1293 TAS2_alertID "TAS2_alerts";
BA_ "FieldType" SG_ 1293 TAS2_alertType "alertState";
BA_ "FieldType" SG_ 1293 TAS2_a030_PWMfaultFL "levelPWMFaultTypes";
BA_ "FieldType" SG_ 1293 TAS2_a031_PWMfaultFR "levelPWMFaultTypes";
BA_ "FieldType" SG_ 1293 TAS2_a032_PWMfaultRL "levelPWMFaultTypes";
BA_ "FieldType" SG_ 1293 TAS2_a033_PWMfaultRR "levelPWMFaultTypes";
BA_ "FieldType" SG_ 1293 TAS2_a034_PWMfaultFL "levelPWMFaultTypes";
BA_ "FieldType" SG_ 1293 TAS2_a035_PWMfaultFR "levelPWMFaultTypes";
BA_ "FieldType" SG_ 1293 TAS2_a036_PWMfaultRL "levelPWMFaultTypes";
BA_ "FieldType" SG_ 1293 TAS2_a037_PWMfaultRR "levelPWMFaultTypes";
BA_ "FieldType" SG_ 1293 TAS2_a038_PWMfaultFL "levelPWMFaultTypes";
BA_ "FieldType" SG_ 1293 TAS2_a039_PWMfaultFR "levelPWMFaultTypes";
BA_ "FieldType" SG_ 1293 TAS2_a040_PWMfaultRL "levelPWMFaultTypes";
BA_ "FieldType" SG_ 1293 TAS2_a041_PWMfaultRR "levelPWMFaultTypes";
BA_ "GenSigStartValue" SG_ 1293 TAS2_a121_ambientTemperature 40;
BA_ "GenSigStartValue" SG_ 1293 TAS2_a122_ambientTemperature 40;
BA_ "GenSigStartValue" SG_ 1293 TAS2_a123_ambientTemperature 40;
BA_ "GenSigStartValue" SG_ 1293 TAS2_a124_ambientTemperature 40;
BA_ "GenSigStartValue" SG_ 1293 TAS2_a125_ambientTemperature 40;
BA_ "GenSigStartValue" SG_ 1293 TAS2_a126_ambientTemperature 40;
BA_ "GenSigStartValue" SG_ 1293 TAS2_a127_ambientTemperature 40;
BA_ "GenSigStartValue" SG_ 1293 TAS2_a128_ambientTemperature 40;
BA_ "FieldType" SG_ 1293 TAS2_a129_valveFaultType "TAS_valveFaultTypes";
BA_ "FieldType" SG_ 1293 TAS2_a130_valveFaultType "TAS_valveFaultTypes";
BA_ "FieldType" SG_ 1293 TAS2_a131_valveFaultType "TAS_valveFaultTypes";
BA_ "FieldType" SG_ 1293 TAS2_a132_valveFaultType "TAS_valveFaultTypes";
BA_ "FieldType" SG_ 1293 TAS2_a133_valveFaultType "TAS_valveFaultTypes";
BA_ "FieldType" SG_ 1293 TAS2_a134_valveFaultType "TAS_valveFaultTypes";
BA_ "FieldType" SG_ 1293 TAS2_a135_valveFaultType "TAS_valveFaultTypes";
BA_ "FieldType" SG_ 1293 TAS2_a136_valveFaultType "TAS_valveFaultTypes";
BA_ "FieldType" SG_ 1293 TAS2_a137_valveFaultType "TAS_valveFaultTypes";
BA_ "FieldType" SG_ 1293 TAS2_a138_valveFaultType "TAS_valveFaultTypes";
BA_ "FieldType" SG_ 1293 TAS2_a139_valveFaultType "TAS_valveFaultTypes";
BA_ "FieldType" SG_ 1293 TAS2_a140_valveFaultType "TAS_valveFaultTypes";
BA_ "FieldType" SG_ 1293 TAS2_a141_valveFaultType "TAS_valveFaultTypes";
BA_ "FieldType" SG_ 1293 TAS2_a142_valveFaultType "TAS_valveFaultTypes";
BA_ "FieldType" SG_ 1293 TAS2_a143_valveFaultType "TAS_valveFaultTypes";
BA_ "FieldType" SG_ 1293 TAS2_a144_valveFaultType "TAS_valveFaultTypes";
BA_ "FieldType" SG_ 1293 TAS2_a145_valveFaultType "TAS_valveFaultTypes";
BA_ "FieldType" SG_ 1293 TAS2_a146_valveFaultType "TAS_valveFaultTypes";
BA_ "FieldType" SG_ 1293 TAS2_a147_valveFaultType "TAS_valveFaultTypes";
BA_ "FieldType" SG_ 1293 TAS2_a148_valveFaultType "TAS_valveFaultTypes";
BA_ "FieldType" SG_ 1293 TAS2_a149_valveFaultType "TAS_valveFaultTypes";
BA_ "FieldType" SG_ 1293 TAS2_a150_valveFaultType "TAS_valveFaultTypes";
BA_ "FieldType" SG_ 1293 TAS2_a151_valveFaultType "TAS_valveFaultTypes";
BA_ "FieldType" SG_ 1293 TAS2_a152_valveFaultType "TAS_valveFaultTypes";
BA_ "FieldType" SG_ 1293 TAS2_a153_valveFaultType "TAS_valveFaultTypes";
BA_ "FieldType" SG_ 1293 TAS2_a154_valveFaultType "TAS_valveFaultTypes";
BA_ "FieldType" SG_ 1293 TAS2_a155_valveFaultType "TAS_valveFaultTypes";
BA_ "FieldType" SG_ 1293 TAS2_a156_valveFaultType "TAS_valveFaultTypes";
BA_ "FieldType" SG_ 1293 TAS2_a157_valveFaultType "TAS_valveFaultTypes";
BA_ "FieldType" SG_ 1293 TAS2_a158_valveFaultType "TAS_valveFaultTypes";
BA_ "FieldType" SG_ 1293 TAS2_a159_valveFaultType "TAS_valveFaultTypes";
BA_ "FieldType" SG_ 1293 TAS2_a160_valveFaultType "TAS_valveFaultTypes";
BA_ "FieldType" SG_ 1293 TAS2_a165_damperValveFault "TAS_damperValveFaults";
BA_ "FieldType" SG_ 1293 TAS2_a166_damperValveFault "TAS_damperValveFaults";
BA_ "FieldType" SG_ 1293 TAS2_a167_damperValveFault "TAS_damperValveFaults";
BA_ "FieldType" SG_ 1293 TAS2_a168_damperValveFault "TAS_damperValveFaults";
BA_ "FieldType" SG_ 1293 TAS2_a169_damperValveFault "TAS_damperValveFaults";
BA_ "FieldType" SG_ 1293 TAS2_a170_damperValveFault "TAS_damperValveFaults";
BA_ "FieldType" SG_ 1293 TAS2_a171_damperValveFault "TAS_damperValveFaults";
BA_ "FieldType" SG_ 1293 TAS2_a172_damperValveFault "TAS_damperValveFaults";
BA_ "GenSigStartValue" SG_ 1293 TAS2_a173_heightDelta_mm 128;
BA_ "GenSigStartValue" SG_ 1293 TAS2_a174_heightDelta_mm 128;
BA_ "GenSigStartValue" SG_ 1293 TAS2_a175_heightDelta_mm 128;
BA_ "GenSigStartValue" SG_ 1293 TAS2_a176_heightDelta_mm 128;
BA_ "GenSigStartValue" SG_ 1293 TAS2_a210_heightSensorDeltaFL 128;
BA_ "GenSigStartValue" SG_ 1293 TAS2_a210_heightSensorDeltaFR 128;
BA_ "GenSigStartValue" SG_ 1293 TAS2_a210_heightSensorDeltaRL 128;
BA_ "GenSigStartValue" SG_ 1293 TAS2_a210_heightSensorDeltaRR 128;
BA_ "FieldType" SG_ 1293 TAS2_a226_PWMfaultFL "levelPWMFaultTypes";
BA_ "FieldType" SG_ 1293 TAS2_a227_PWMfaultFR "levelPWMFaultTypes";
BA_ "FieldType" SG_ 1293 TAS2_a228_PWMfaultRL "levelPWMFaultTypes";
BA_ "FieldType" SG_ 1293 TAS2_a229_PWMfaultRR "levelPWMFaultTypes";
BA_ "GenSigStartValue" SG_ 1293 TAS2_a287_crossPressure 128;
BA_ "GenSigStartValue" SG_ 1293 TAS2_a290_twistLevel 128;
BA_ "GenSigStartValue" SG_ 1293 TAS2_a291_frontAxleHeight 128;
BA_ "GenSigStartValue" SG_ 1293 TAS2_a292_rearAxleHeight 128;
BA_ "GenSigStartValue" SG_ 1293 TAS2_a293_frontAxleHeight 128;
BA_ "GenSigStartValue" SG_ 1293 TAS2_a294_rearAxleHeight 128;
BA_ "GenSigStartValue" SG_ 1293 TAS2_a295_targetHeight 128;
BA_ "FieldType" SG_ 1293 TAS2_a296_detectedChassisType "ChassisType";
BA_ "FieldType" SG_ 1293 TAS2_a296_expectedChassisType "ChassisType";
BA_ "FieldType" SG_ 1293 TAS2_a299_corner "SuspensionCorner";
BA_ "FieldType" SG_ 1293 TAS2_a299_type "TAS_estimateType";
BA_ "GenSigStartValue" SG_ 1293 TAS2_a299_massEstimate -1000;
BA_ "GenSigStartValue" SG_ 1293 TAS2_a299_vehicleSpeed 880;
BA_ "FieldType" SG_ 1293 TAS2_a299_currentRideHeight "TAS_level";
BA_ "GenSigStartValue" SG_ 1293 TAS2_a303_massEstimate -1000;
BA_ "FieldType" SG_ 1293 TAS2_a303_currentRideHeight "TAS_level";
BA_ "GenSigStartValue" SG_ 1293 TAS2_a304_springForceFL -1000;
BA_ "GenSigStartValue" SG_ 1293 TAS2_a304_springForceFR -1000;
BA_ "GenSigStartValue" SG_ 1293 TAS2_a304_springForceRL -1000;
BA_ "GenSigStartValue" SG_ 1293 TAS2_a304_springForceRR -1000;
BA_ "FieldType" SG_ 1293 TAS2_a305_corner "SuspensionCorner";
BA_ "FieldType" SG_ 1293 TAS2_a306_corner "SuspensionCorner";
BA_ "FieldType" SG_ 1293 TAS2_a306_direction "SuspensionDirection";
BA_ "FieldType" SG_ 1293 TAS2_a309_corner "SuspensionCorner";
BA_ "FieldType" SG_ 1293 TAS2_a309_direction "SuspensionDirection";
BA_ "FieldType" SG_ 1293 TAS2_a309_currentRideHeight "TAS_level";
BA_ "GenSigStartValue" SG_ 1293 TAS2_a315_temperature 40;
BA_ "FieldType" SG_ 1292 TAS2_matrixIndex "TAS2_AlertMatrixIndex";
BA_ "GenSigSNA" SG_ 1433 TAS2_current_FL_C "255";
BA_ "GenSigSNA" SG_ 1433 TAS2_current_FL_R "255";
BA_ "GenSigSNA" SG_ 1433 TAS2_current_FR_C "255";
BA_ "GenSigSNA" SG_ 1433 TAS2_current_FR_R "255";
BA_ "GenSigSNA" SG_ 1433 TAS2_current_RL_C "255";
BA_ "GenSigSNA" SG_ 1433 TAS2_current_RL_R "255";
BA_ "GenSigSNA" SG_ 1433 TAS2_current_RR_C "255";
BA_ "GenSigSNA" SG_ 1433 TAS2_current_RR_R "255";
BA_ "LogSignal" SG_ 1398 TAS2_endstopState "onChange";
BA_ "LogSignal" SG_ 1398 TAS2_continuousControlState "onChange";
BA_ "GenSigSNA" SG_ 1398 TAS2_roadCondition "255";
BA_ "LogSignal" SG_ 1398 TAS2_roadCondition "periodic ONE_SECOND driveModeModelS";
BA_ "LogSignal" SG_ 1398 TAS2_McQueenBoostAxleFront "onChange";
BA_ "LogSignal" SG_ 1398 TAS2_McQueenBoostAxleRear "onChange";
BA_ "LogSignal" SG_ 1398 TAS2_speedBumpAxleFront "onChange";
BA_ "LogSignal" SG_ 1398 TAS2_speedBumpAxleRear "onChange";
BA_ "LogSignal" SG_ 1398 TAS2_holeProtectFL "onChange";
BA_ "LogSignal" SG_ 1398 TAS2_holeProtectFR "onChange";
BA_ "LogSignal" SG_ 1398 TAS2_holeProtectRL "onChange";
BA_ "LogSignal" SG_ 1398 TAS2_holeProtectRR "onChange";
BA_ "LogSignal" SG_ 1398 TAS2_stepProtectFL "onChange";
BA_ "LogSignal" SG_ 1398 TAS2_stepProtectFR "onChange";
BA_ "LogSignal" SG_ 1398 TAS2_stepProtectRL "onChange";
BA_ "LogSignal" SG_ 1398 TAS2_stepProtectRR "onChange";
BA_ "GenSigSNA" SG_ 1398 TAS2_FDUTorqueCorruptionScale "15";
BA_ "GenSigSNA" SG_ 1019 TAS_CPULoad1msTask "255";
BA_ "GenSigSNA" SG_ 1019 TAS_CPULoad10msTask "255";
BA_ "GenSigSNA" SG_ 1019 TAS_CPULoad100msTask "255";
BA_ "GenSigSNA" SG_ 1019 TAS_CPULoad1000msTask "255";
BA_ "GenSigSNA" SG_ 1019 TAS_CPULoadTotal "255";
BA_ "FieldType" SG_ 1291 TAS_alertID "TAS_alerts";
BA_ "FieldType" SG_ 1291 TAS_alertType "alertState";
BA_ "FieldType" SG_ 1291 TAS_a030_PWMfaultFL "levelPWMFaultTypes";
BA_ "FieldType" SG_ 1291 TAS_a031_PWMfaultFR "levelPWMFaultTypes";
BA_ "FieldType" SG_ 1291 TAS_a032_PWMfaultRL "levelPWMFaultTypes";
BA_ "FieldType" SG_ 1291 TAS_a033_PWMfaultRR "levelPWMFaultTypes";
BA_ "FieldType" SG_ 1291 TAS_a034_PWMfaultFL "levelPWMFaultTypes";
BA_ "FieldType" SG_ 1291 TAS_a035_PWMfaultFR "levelPWMFaultTypes";
BA_ "FieldType" SG_ 1291 TAS_a036_PWMfaultRL "levelPWMFaultTypes";
BA_ "FieldType" SG_ 1291 TAS_a037_PWMfaultRR "levelPWMFaultTypes";
BA_ "FieldType" SG_ 1291 TAS_a038_PWMfaultFL "levelPWMFaultTypes";
BA_ "FieldType" SG_ 1291 TAS_a039_PWMfaultFR "levelPWMFaultTypes";
BA_ "FieldType" SG_ 1291 TAS_a040_PWMfaultRL "levelPWMFaultTypes";
BA_ "FieldType" SG_ 1291 TAS_a041_PWMfaultRR "levelPWMFaultTypes";
BA_ "GenSigStartValue" SG_ 1291 TAS_a121_ambientTemperature 40;
BA_ "GenSigStartValue" SG_ 1291 TAS_a122_ambientTemperature 40;
BA_ "GenSigStartValue" SG_ 1291 TAS_a123_ambientTemperature 40;
BA_ "GenSigStartValue" SG_ 1291 TAS_a124_ambientTemperature 40;
BA_ "GenSigStartValue" SG_ 1291 TAS_a125_ambientTemperature 40;
BA_ "GenSigStartValue" SG_ 1291 TAS_a126_ambientTemperature 40;
BA_ "GenSigStartValue" SG_ 1291 TAS_a127_ambientTemperature 40;
BA_ "GenSigStartValue" SG_ 1291 TAS_a128_ambientTemperature 40;
BA_ "FieldType" SG_ 1291 TAS_a129_valveFaultType "TAS_valveFaultTypes";
BA_ "FieldType" SG_ 1291 TAS_a130_valveFaultType "TAS_valveFaultTypes";
BA_ "FieldType" SG_ 1291 TAS_a131_valveFaultType "TAS_valveFaultTypes";
BA_ "FieldType" SG_ 1291 TAS_a132_valveFaultType "TAS_valveFaultTypes";
BA_ "FieldType" SG_ 1291 TAS_a133_valveFaultType "TAS_valveFaultTypes";
BA_ "FieldType" SG_ 1291 TAS_a134_valveFaultType "TAS_valveFaultTypes";
BA_ "FieldType" SG_ 1291 TAS_a135_valveFaultType "TAS_valveFaultTypes";
BA_ "FieldType" SG_ 1291 TAS_a136_valveFaultType "TAS_valveFaultTypes";
BA_ "FieldType" SG_ 1291 TAS_a137_valveFaultType "TAS_valveFaultTypes";
BA_ "FieldType" SG_ 1291 TAS_a138_valveFaultType "TAS_valveFaultTypes";
BA_ "FieldType" SG_ 1291 TAS_a139_valveFaultType "TAS_valveFaultTypes";
BA_ "FieldType" SG_ 1291 TAS_a140_valveFaultType "TAS_valveFaultTypes";
BA_ "FieldType" SG_ 1291 TAS_a141_valveFaultType "TAS_valveFaultTypes";
BA_ "FieldType" SG_ 1291 TAS_a142_valveFaultType "TAS_valveFaultTypes";
BA_ "FieldType" SG_ 1291 TAS_a143_valveFaultType "TAS_valveFaultTypes";
BA_ "FieldType" SG_ 1291 TAS_a144_valveFaultType "TAS_valveFaultTypes";
BA_ "FieldType" SG_ 1291 TAS_a145_valveFaultType "TAS_valveFaultTypes";
BA_ "FieldType" SG_ 1291 TAS_a146_valveFaultType "TAS_valveFaultTypes";
BA_ "FieldType" SG_ 1291 TAS_a147_valveFaultType "TAS_valveFaultTypes";
BA_ "FieldType" SG_ 1291 TAS_a148_valveFaultType "TAS_valveFaultTypes";
BA_ "FieldType" SG_ 1291 TAS_a149_valveFaultType "TAS_valveFaultTypes";
BA_ "FieldType" SG_ 1291 TAS_a150_valveFaultType "TAS_valveFaultTypes";
BA_ "FieldType" SG_ 1291 TAS_a151_valveFaultType "TAS_valveFaultTypes";
BA_ "FieldType" SG_ 1291 TAS_a152_valveFaultType "TAS_valveFaultTypes";
BA_ "FieldType" SG_ 1291 TAS_a153_valveFaultType "TAS_valveFaultTypes";
BA_ "FieldType" SG_ 1291 TAS_a154_valveFaultType "TAS_valveFaultTypes";
BA_ "FieldType" SG_ 1291 TAS_a155_valveFaultType "TAS_valveFaultTypes";
BA_ "FieldType" SG_ 1291 TAS_a156_valveFaultType "TAS_valveFaultTypes";
BA_ "FieldType" SG_ 1291 TAS_a157_valveFaultType "TAS_valveFaultTypes";
BA_ "FieldType" SG_ 1291 TAS_a158_valveFaultType "TAS_valveFaultTypes";
BA_ "FieldType" SG_ 1291 TAS_a159_valveFaultType "TAS_valveFaultTypes";
BA_ "FieldType" SG_ 1291 TAS_a160_valveFaultType "TAS_valveFaultTypes";
BA_ "GenSigStartValue" SG_ 1291 TAS_a173_heightDelta_mm 128;
BA_ "GenSigStartValue" SG_ 1291 TAS_a174_heightDelta_mm 128;
BA_ "GenSigStartValue" SG_ 1291 TAS_a175_heightDelta_mm 128;
BA_ "GenSigStartValue" SG_ 1291 TAS_a176_heightDelta_mm 128;
BA_ "GenSigStartValue" SG_ 1291 TAS_a210_heightSensorDeltaFL 128;
BA_ "GenSigStartValue" SG_ 1291 TAS_a210_heightSensorDeltaFR 128;
BA_ "GenSigStartValue" SG_ 1291 TAS_a210_heightSensorDeltaRL 128;
BA_ "GenSigStartValue" SG_ 1291 TAS_a210_heightSensorDeltaRR 128;
BA_ "FieldType" SG_ 1291 TAS_a226_PWMfaultFL "levelPWMFaultTypes";
BA_ "FieldType" SG_ 1291 TAS_a227_PWMfaultFR "levelPWMFaultTypes";
BA_ "FieldType" SG_ 1291 TAS_a228_PWMfaultRL "levelPWMFaultTypes";
BA_ "FieldType" SG_ 1291 TAS_a229_PWMfaultRR "levelPWMFaultTypes";
BA_ "GenSigStartValue" SG_ 1291 TAS_a287_crossPressure 128;
BA_ "GenSigStartValue" SG_ 1291 TAS_a290_twistLevel 128;
BA_ "GenSigStartValue" SG_ 1291 TAS_a291_frontAxleHeight 128;
BA_ "GenSigStartValue" SG_ 1291 TAS_a292_rearAxleHeight 128;
BA_ "GenSigStartValue" SG_ 1291 TAS_a293_frontAxleHeight 128;
BA_ "GenSigStartValue" SG_ 1291 TAS_a294_rearAxleHeight 128;
BA_ "GenSigStartValue" SG_ 1291 TAS_a295_targetHeight 128;
BA_ "FieldType" SG_ 523 TAS_axleIndex "TAS_axle";
BA_ "GenSigSNA" SG_ 523 TAS_fastFilteredHeightFL "255";
BA_ "LogSignal" SG_ 523 TAS_fastFilteredHeightFL "periodic ONE_SECOND tasLeveling0,periodic ONE_SECOND tasLeveling1,periodic ONE_SECOND tasLeveling2,periodic ONE_SECOND tasLeveling3,periodic ONE_SECOND tasLeveling4";
BA_ "GenSigSNA" SG_ 523 TAS_modeFilteredHeightFL "255";
BA_ "LogSignal" SG_ 523 TAS_modeFilteredHeightFL "periodic ONE_MINUTE Any";
BA_ "GenSigSNA" SG_ 523 TAS_componentPressureFL "255";
BA_ "GenSigSNA" SG_ 523 TAS_fastFilteredHeightFR "255";
BA_ "LogSignal" SG_ 523 TAS_fastFilteredHeightFR "periodic ONE_SECOND tasLeveling0,periodic ONE_SECOND tasLeveling1,periodic ONE_SECOND tasLeveling2,periodic ONE_SECOND tasLeveling3,periodic ONE_SECOND tasLeveling4";
BA_ "GenSigSNA" SG_ 523 TAS_modeFilteredHeightFR "255";
BA_ "LogSignal" SG_ 523 TAS_modeFilteredHeightFR "periodic ONE_MINUTE Any";
BA_ "GenSigSNA" SG_ 523 TAS_componentPressureFR "255";
BA_ "GenSigSNA" SG_ 523 TAS_fastFilteredHeightRL "255";
BA_ "LogSignal" SG_ 523 TAS_fastFilteredHeightRL "periodic ONE_SECOND tasLeveling0,periodic ONE_SECOND tasLeveling1,periodic ONE_SECOND tasLeveling2,periodic ONE_SECOND tasLeveling3,periodic ONE_SECOND tasLeveling4";
BA_ "GenSigSNA" SG_ 523 TAS_modeFilteredHeightRL "255";
BA_ "LogSignal" SG_ 523 TAS_modeFilteredHeightRL "periodic ONE_MINUTE Any";
BA_ "GenSigSNA" SG_ 523 TAS_componentPressureRL "255";
BA_ "GenSigSNA" SG_ 523 TAS_fastFilteredHeightRR "255";
BA_ "LogSignal" SG_ 523 TAS_fastFilteredHeightRR "periodic ONE_SECOND tasLeveling0,periodic ONE_SECOND tasLeveling1,periodic ONE_SECOND tasLeveling2,periodic ONE_SECOND tasLeveling3,periodic ONE_SECOND tasLeveling4";
BA_ "GenSigSNA" SG_ 523 TAS_modeFilteredHeightRR "255";
BA_ "LogSignal" SG_ 523 TAS_modeFilteredHeightRR "periodic ONE_MINUTE Any";
BA_ "GenSigSNA" SG_ 523 TAS_componentPressureRR "255";
BA_ "FieldType" SG_ 1313 TAS_firmwareType "firmwareType";
BA_ "FieldType" SG_ 1035 TAS_nmKeepAwakeReason "TAS_NM_keepAwakeReason";
BA_ "GenSigSNA" SG_ 1035 TAS_nmKeepAwakeReason "0";
BA_ "LogSignal" SG_ 1035 TAS_nmKeepAwakeReason "onChange";
BA_ "FieldType" SG_ 1035 TAS_nmWakeUpReason "CH_NM_wakeUpReason";
BA_ "LogSignal" SG_ 1035 TAS_nmWakeUpReason "onChange";
BA_ "LogSignal" SG_ 1035 TAS_nmDebugWakeUp "onChange";
BA_ "GenSigSNA" SG_ 546 TAS_compTempSensor "255";
BA_ "GenSigStartValue" SG_ 546 TAS_compTempSensor 40;
BA_ "LogSignal" SG_ 546 TAS_compTempSensor "periodic ONE_MINUTE Any";
BA_ "GenSigSNA" SG_ 546 TAS_compTempModel "255";
BA_ "GenSigStartValue" SG_ 546 TAS_compTempModel 40;
BA_ "LogSignal" SG_ 546 TAS_compTempModel "periodic ONE_MINUTE Any";
VAL_ 69 SpdCtrlLvr_Stat 32 "DN_1ST" 16 "UP_1ST" 8 "DN_2ND" 4 "UP_2ND" 2 "RWD" 1 "FWD" 0 "IDLE" ;
VAL_ 69 DTR_Dist_Rq 255 "SNA" 200 "ACC_DIST_7" 166 "ACC_DIST_6" 133 "ACC_DIST_5" 100 "ACC_DIST_4" 66 "ACC_DIST_3" 33 "ACC_DIST_2" 0 "ACC_DIST_1" ;
VAL_ 69 TurnIndLvr_Stat 3 "SNA" 2 "RIGHT" 1 "LEFT" 0 "IDLE" ;
VAL_ 69 HiBmLvr_Stat 3 "SNA" 2 "HIBM_FLSH_ON_PSD" 1 "HIBM_ON_PSD" 0 "IDLE" ;
VAL_ 69 WprWashSw_Psd 3 "SNA" 2 "WASH" 1 "TIPWIPE" 0 "NPSD" ;
VAL_ 69 WprWash_R_Sw_Posn_V2 3 "SNA" 2 "WASH" 1 "INTERVAL" 0 "OFF" ;
VAL_ 69 StW_Lvr_Stat 4 "STW_BACK" 3 "STW_FWD" 2 "STW_DOWN" 1 "STW_UP" 0 "NPSD" ;
VAL_ 69 StW_Cond_Psd 3 "SNA" 2 "DOWN" 1 "UP" 0 "NPSD" ;
VAL_ 69 HrnSw_Psd 3 "SNA" 2 "NDEF2" 1 "PSD" 0 "NPSD" ;
VAL_ 69 StW_Sw00_Psd 1 "PRESSED" 0 "NOT_PRESSED" ;
VAL_ 69 StW_Sw01_Psd 1 "PRESSED" 0 "NOT_PRESSED" ;
VAL_ 69 StW_Sw03_Psd 1 "PRESSED" 0 "NOT_PRESSED" ;
VAL_ 69 StW_Sw04_Psd 1 "PRESSED" 0 "NOT_PRESSED" ;
VAL_ 69 WprSw6Posn 7 "SNA" 6 "STAGE2" 5 "STAGE1" 4 "INTERVAL4" 3 "INTERVAL3" 2 "INTERVAL2" 1 "INTERVAL1" 0 "OFF" ;
VAL_ 14 StW_AnglHP 16383 "SNA" ;
VAL_ 14 StW_AnglHP_Spd 16383 "SNA" ;
VAL_ 14 StW_AnglHP_Sens_Stat 3 "SNA" 2 "ERR" 1 "INI" 0 "OK" ;
VAL_ 14 StW_AnglHP_Sens_Id 3 "SNA" 2 "KOSTAL" 1 "DELPHI" 0 "TEST" ;
VAL_ 3 StW_Angl 16383 "SNA" ;
VAL_ 3 StW_AnglSpd 16383 "SNA" ;
VAL_ 3 StW_AnglSens_Stat 3 "ERR_INI" 2 "ERR" 1 "INI" 0 "OK" ;
VAL_ 3 StW_AnglSens_Id 2 "INIT_MUST" 1 "INIT_SELF" 0 "INIT_PSBL" ;
VAL_ 1340 TAS2_alertClearedID 317 "TAS2_a317_offsetsRotationalRates" 316 "TAS2_a316_offsetsAccels" 315 "TAS2_a315_pcbaHighTemp" 314 "TAS2_a314_dampingReduced" 313 "TAS2_a313_dampingCntrlDisabled" 312 "TAS2_a312_rotationalRatesMIA" 311 "TAS2_a311_accelsMIA" 310 "TAS2_a310_controlFrozenData" 309 "TAS2_a309_controlFrozen" 308 "TAS2_a308_endstopBoundaryRbnd" 307 "TAS2_a307_endstopBoundaryComp" 306 "TAS2_a306_endstopProtectFrozen" 305 "TAS2_a305_newEndstopPosition" 304 "TAS2_a304_massEstimateFrozenData" 303 "TAS2_a303_massEstimateFrozen" 301 "TAS2_a301_offsetEstimateData2" 300 "TAS2_a300_offsetEstimateData1" 299 "TAS2_a299_offsetEstimateTooLarge" 298 "TAS2_a298_vinNotLearned" 297 "TAS2_a297_vinMismatch" 296 "TAS2_a296_chassisTypeMismatch" 295 "TAS2_a295_targetHeightNotMet" 294 "TAS2_a294_rearAxleTooLow" 293 "TAS2_a293_frontAxleTooLow" 292 "TAS2_a292_rearAxleTooHigh" 291 "TAS2_a291_frontAxleTooHigh" 290 "TAS2_a290_twistSustainedAtSpeed" 289 "TAS2_a289_driveCycleStats4" 288 "TAS2_a288_driveCycleStats3" 287 "TAS2_a287_driveCycleStats2" 286 "TAS2_a286_driveCycleStats1" 230 "TAS2_a230_geofenceNotification" 229 "TAS2_a229_PWMfastDetectRR" 228 "TAS2_a228_PWMfastDetectRL" 227 "TAS2_a227_PWMfastDetectFR" 226 "TAS2_a226_PWMfastDetectFL" 225 "TAS2_a225_galleryPressureTooHigh" 224 "TAS2_a224_openAirline" 223 "TAS2_a223_blockedAirline" 222 "TAS2_a222_compressorPrefillFault" 221 "TAS2_a221_valveLeakDetected" 220 "TAS2_a220_exhaustGalleryFault" 218 "TAS2_a218_limpHomeMode40" 217 "TAS2_a217_limpHomeMode30" 216 "TAS2_a216_limpHomeMode20" 215 "TAS2_a215_limpHomeMode10" 214 "TAS2_a214_redWarningLamp" 213 "TAS2_a213_yellowWarningLamp" 211 "TAS2_a211_noRideHeightCalib" 210 "TAS2_a210_outOfRangeCalibration" 201 "TAS2_a201_lowHVBattery" 200 "TAS2_a200_jackModeActive" 176 "TAS2_a176_staticLeakDetectRR" 175 "TAS2_a175_staticLeakDetectRL" 174 "TAS2_a174_staticLeakDetectFR" 173 "TAS2_a173_staticLeakDetectFL" 172 "TAS2_a172_damperValveRbndRR" 171 "TAS2_a171_damperValveCompRR" 170 "TAS2_a170_damperValveRbndRL" 169 "TAS2_a169_damperValveCompRL" 168 "TAS2_a168_damperValveRbndFR" 167 "TAS2_a167_damperValveCompFR" 166 "TAS2_a166_damperValveRbndFL" 165 "TAS2_a165_damperValveCompFL" 163 "TAS2_a163_reservoirFillDisabled" 162 "TAS2_a162_compressorValveOpenGND" 161 "TAS2_a161_valveBlockOpenGND" 160 "TAS2_a160_otherCircuitCompressor" 159 "TAS2_a159_otherCircuitBoost" 158 "TAS2_a158_otherCircuitExhaust" 157 "TAS2_a157_otherCircuitReservoir" 156 "TAS2_a156_otherCircuitRR" 155 "TAS2_a155_otherCircuitRL" 154 "TAS2_a154_otherCircuitFR" 153 "TAS2_a153_otherCircuitFL" 152 "TAS2_a152_boardFaultCompressor" 151 "TAS2_a151_boardFaultBoost" 150 "TAS2_a150_boardFaultExhaust" 149 "TAS2_a149_boardFaultReservoir" 148 "TAS2_a148_boardFaultRR" 147 "TAS2_a147_boardFaultRL" 146 "TAS2_a146_boardFaultFR" 145 "TAS2_a145_boardFaultFL" 144 "TAS2_a144_shortCircuitCompressor" 143 "TAS2_a143_shortCircuitBoost" 142 "TAS2_a142_shortCircuitExhaust" 141 "TAS2_a141_shortCircuitReservoir" 140 "TAS2_a140_shortCircuitRR" 139 "TAS2_a139_shortCircuitRL" 138 "TAS2_a138_shortCircuitFR" 137 "TAS2_a137_shortCircuitFL" 136 "TAS2_a136_openCircuitCompressor" 135 "TAS2_a135_openCircuitBoost" 134 "TAS2_a134_openCircuitExhaust" 133 "TAS2_a133_openCircuitReservoir" 132 "TAS2_a132_openCircuitRR" 131 "TAS2_a131_openCircuitRL" 130 "TAS2_a130_openCircuitFR" 129 "TAS2_a129_openCircuitFL" 128 "TAS2_a128_maxDutyCompressor" 127 "TAS2_a127_maxDutyBoost" 126 "TAS2_a126_maxDutyExhaust" 125 "TAS2_a125_maxDutyReservoir" 124 "TAS2_a124_maxDutyRR" 123 "TAS2_a123_maxDutyRL" 122 "TAS2_a122_maxDutyFR" 121 "TAS2_a121_maxDutyFL" 107 "TAS2_a107_HighStackUsage" 106 "TAS2_a106_HighCPULoad" 103 "TAS2_a103_GTW_MIA" 102 "TAS2_a102_DI_MIA" 101 "TAS2_a101_ESP_MIA" 100 "TAS2_a100_SCCM_MIA" 99 "TAS2_a099_EFUSE_MIA" 98 "TAS2_a098_MCU_MIA" 97 "TAS2_a097_RCM_MIA" 96 "TAS2_a096_IMU_MIA" 95 "TAS2_a095_DIS_MIA" 94 "TAS2_a094_DAS_MIA" 93 "TAS2_a093_OTPError" 87 "TAS2_a087_overVoltage12VSwtchd" 86 "TAS2_a086_underVoltage12VSwtchd" 85 "TAS2_a085_overVoltage5VAnalog" 84 "TAS2_a084_underVoltage5VAnalog" 83 "TAS2_a083_shortCircuit5VAnalog" 82 "TAS2_a082_overVoltage5VHeight" 81 "TAS2_a081_underVoltage5VHeight" 80 "TAS2_a080_shortCircuit5VHeight" 78 "TAS2_a078_pressureSigVTooHigh" 77 "TAS2_a077_pressureSigVTooLow" 73 "TAS2_a073_underVoltage5VOnBoard" 72 "TAS2_a072_shortCircuit5VOnBoard" 71 "TAS2_a071_overVoltage12V" 70 "TAS2_a070_underVoltage12V" 62 "TAS2_a062_XCPWasConnected" 61 "TAS2_a061_XCPConnected" 46 "TAS2_a046_Task1000msError" 45 "TAS2_a045_Task100msError" 44 "TAS2_a044_Task10msError" 43 "TAS2_a043_Task1msError" 41 "TAS2_a041_PWMopenRR" 40 "TAS2_a040_PWMopenRL" 39 "TAS2_a039_PWMopenFR" 38 "TAS2_a038_PWMopenFL" 37 "TAS2_a037_PWMshortRR" 36 "TAS2_a036_PWMshortRL" 35 "TAS2_a035_PWMshortFR" 34 "TAS2_a034_PWMshortFL" 33 "TAS2_a033_PWMerrorRR" 32 "TAS2_a032_PWMerrorRL" 31 "TAS2_a031_PWMerrorFR" 30 "TAS2_a030_PWMerrorFL" 25 "TAS2_a025_CrashEvent" 22 "TAS2_a022_TaskInitError" 21 "TAS2_a021_TaskSchedulerError" 15 "TAS2_a015_NVMMAlert" 12 "TAS2_a012_CPUReset" 3 "TAS2_a003_SWAssertion" 2 "TAS2_a002_PowerLossReset" 1 "TAS2_a001_WatchdogReset" 0 "TAS2_ALERT_DO_NOT_USE_ZERO" ;
VAL_ 1293 TAS2_alertID 317 "TAS2_a317_offsetsRotationalRates" 316 "TAS2_a316_offsetsAccels" 315 "TAS2_a315_pcbaHighTemp" 314 "TAS2_a314_dampingReduced" 313 "TAS2_a313_dampingCntrlDisabled" 312 "TAS2_a312_rotationalRatesMIA" 311 "TAS2_a311_accelsMIA" 310 "TAS2_a310_controlFrozenData" 309 "TAS2_a309_controlFrozen" 308 "TAS2_a308_endstopBoundaryRbnd" 307 "TAS2_a307_endstopBoundaryComp" 306 "TAS2_a306_endstopProtectFrozen" 305 "TAS2_a305_newEndstopPosition" 304 "TAS2_a304_massEstimateFrozenData" 303 "TAS2_a303_massEstimateFrozen" 301 "TAS2_a301_offsetEstimateData2" 300 "TAS2_a300_offsetEstimateData1" 299 "TAS2_a299_offsetEstimateTooLarge" 298 "TAS2_a298_vinNotLearned" 297 "TAS2_a297_vinMismatch" 296 "TAS2_a296_chassisTypeMismatch" 295 "TAS2_a295_targetHeightNotMet" 294 "TAS2_a294_rearAxleTooLow" 293 "TAS2_a293_frontAxleTooLow" 292 "TAS2_a292_rearAxleTooHigh" 291 "TAS2_a291_frontAxleTooHigh" 290 "TAS2_a290_twistSustainedAtSpeed" 289 "TAS2_a289_driveCycleStats4" 288 "TAS2_a288_driveCycleStats3" 287 "TAS2_a287_driveCycleStats2" 286 "TAS2_a286_driveCycleStats1" 230 "TAS2_a230_geofenceNotification" 229 "TAS2_a229_PWMfastDetectRR" 228 "TAS2_a228_PWMfastDetectRL" 227 "TAS2_a227_PWMfastDetectFR" 226 "TAS2_a226_PWMfastDetectFL" 225 "TAS2_a225_galleryPressureTooHigh" 224 "TAS2_a224_openAirline" 223 "TAS2_a223_blockedAirline" 222 "TAS2_a222_compressorPrefillFault" 221 "TAS2_a221_valveLeakDetected" 220 "TAS2_a220_exhaustGalleryFault" 218 "TAS2_a218_limpHomeMode40" 217 "TAS2_a217_limpHomeMode30" 216 "TAS2_a216_limpHomeMode20" 215 "TAS2_a215_limpHomeMode10" 214 "TAS2_a214_redWarningLamp" 213 "TAS2_a213_yellowWarningLamp" 211 "TAS2_a211_noRideHeightCalib" 210 "TAS2_a210_outOfRangeCalibration" 201 "TAS2_a201_lowHVBattery" 200 "TAS2_a200_jackModeActive" 176 "TAS2_a176_staticLeakDetectRR" 175 "TAS2_a175_staticLeakDetectRL" 174 "TAS2_a174_staticLeakDetectFR" 173 "TAS2_a173_staticLeakDetectFL" 172 "TAS2_a172_damperValveRbndRR" 171 "TAS2_a171_damperValveCompRR" 170 "TAS2_a170_damperValveRbndRL" 169 "TAS2_a169_damperValveCompRL" 168 "TAS2_a168_damperValveRbndFR" 167 "TAS2_a167_damperValveCompFR" 166 "TAS2_a166_damperValveRbndFL" 165 "TAS2_a165_damperValveCompFL" 163 "TAS2_a163_reservoirFillDisabled" 162 "TAS2_a162_compressorValveOpenGND" 161 "TAS2_a161_valveBlockOpenGND" 160 "TAS2_a160_otherCircuitCompressor" 159 "TAS2_a159_otherCircuitBoost" 158 "TAS2_a158_otherCircuitExhaust" 157 "TAS2_a157_otherCircuitReservoir" 156 "TAS2_a156_otherCircuitRR" 155 "TAS2_a155_otherCircuitRL" 154 "TAS2_a154_otherCircuitFR" 153 "TAS2_a153_otherCircuitFL" 152 "TAS2_a152_boardFaultCompressor" 151 "TAS2_a151_boardFaultBoost" 150 "TAS2_a150_boardFaultExhaust" 149 "TAS2_a149_boardFaultReservoir" 148 "TAS2_a148_boardFaultRR" 147 "TAS2_a147_boardFaultRL" 146 "TAS2_a146_boardFaultFR" 145 "TAS2_a145_boardFaultFL" 144 "TAS2_a144_shortCircuitCompressor" 143 "TAS2_a143_shortCircuitBoost" 142 "TAS2_a142_shortCircuitExhaust" 141 "TAS2_a141_shortCircuitReservoir" 140 "TAS2_a140_shortCircuitRR" 139 "TAS2_a139_shortCircuitRL" 138 "TAS2_a138_shortCircuitFR" 137 "TAS2_a137_shortCircuitFL" 136 "TAS2_a136_openCircuitCompressor" 135 "TAS2_a135_openCircuitBoost" 134 "TAS2_a134_openCircuitExhaust" 133 "TAS2_a133_openCircuitReservoir" 132 "TAS2_a132_openCircuitRR" 131 "TAS2_a131_openCircuitRL" 130 "TAS2_a130_openCircuitFR" 129 "TAS2_a129_openCircuitFL" 128 "TAS2_a128_maxDutyCompressor" 127 "TAS2_a127_maxDutyBoost" 126 "TAS2_a126_maxDutyExhaust" 125 "TAS2_a125_maxDutyReservoir" 124 "TAS2_a124_maxDutyRR" 123 "TAS2_a123_maxDutyRL" 122 "TAS2_a122_maxDutyFR" 121 "TAS2_a121_maxDutyFL" 107 "TAS2_a107_HighStackUsage" 106 "TAS2_a106_HighCPULoad" 103 "TAS2_a103_GTW_MIA" 102 "TAS2_a102_DI_MIA" 101 "TAS2_a101_ESP_MIA" 100 "TAS2_a100_SCCM_MIA" 99 "TAS2_a099_EFUSE_MIA" 98 "TAS2_a098_MCU_MIA" 97 "TAS2_a097_RCM_MIA" 96 "TAS2_a096_IMU_MIA" 95 "TAS2_a095_DIS_MIA" 94 "TAS2_a094_DAS_MIA" 93 "TAS2_a093_OTPError" 87 "TAS2_a087_overVoltage12VSwtchd" 86 "TAS2_a086_underVoltage12VSwtchd" 85 "TAS2_a085_overVoltage5VAnalog" 84 "TAS2_a084_underVoltage5VAnalog" 83 "TAS2_a083_shortCircuit5VAnalog" 82 "TAS2_a082_overVoltage5VHeight" 81 "TAS2_a081_underVoltage5VHeight" 80 "TAS2_a080_shortCircuit5VHeight" 78 "TAS2_a078_pressureSigVTooHigh" 77 "TAS2_a077_pressureSigVTooLow" 73 "TAS2_a073_underVoltage5VOnBoard" 72 "TAS2_a072_shortCircuit5VOnBoard" 71 "TAS2_a071_overVoltage12V" 70 "TAS2_a070_underVoltage12V" 62 "TAS2_a062_XCPWasConnected" 61 "TAS2_a061_XCPConnected" 46 "TAS2_a046_Task1000msError" 45 "TAS2_a045_Task100msError" 44 "TAS2_a044_Task10msError" 43 "TAS2_a043_Task1msError" 41 "TAS2_a041_PWMopenRR" 40 "TAS2_a040_PWMopenRL" 39 "TAS2_a039_PWMopenFR" 38 "TAS2_a038_PWMopenFL" 37 "TAS2_a037_PWMshortRR" 36 "TAS2_a036_PWMshortRL" 35 "TAS2_a035_PWMshortFR" 34 "TAS2_a034_PWMshortFL" 33 "TAS2_a033_PWMerrorRR" 32 "TAS2_a032_PWMerrorRL" 31 "TAS2_a031_PWMerrorFR" 30 "TAS2_a030_PWMerrorFL" 25 "TAS2_a025_CrashEvent" 22 "TAS2_a022_TaskInitError" 21 "TAS2_a021_TaskSchedulerError" 15 "TAS2_a015_NVMMAlert" 12 "TAS2_a012_CPUReset" 3 "TAS2_a003_SWAssertion" 2 "TAS2_a002_PowerLossReset" 1 "TAS2_a001_WatchdogReset" 0 "TAS2_ALERT_DO_NOT_USE_ZERO" ;
VAL_ 1293 TAS2_alertType 1 "ALERT_SET" 0 "ALERT_CLEARED" ;
VAL_ 1293 TAS2_a030_PWMfaultFL 6 "PWM_OPEN_CIRCUIT" 5 "PWM_SHORT_CIRCUIT" 4 "PWM_OVER_MAX_DELTA_DUTY" 3 "PWM_UNDER_MIN_PERIOD" 2 "PWM_OVER_MAX_PERIOD" 1 "PWM_UNDER_MIN_DUTY" 0 "PWM_OVER_MAX_DUTY" ;
VAL_ 1293 TAS2_a031_PWMfaultFR 6 "PWM_OPEN_CIRCUIT" 5 "PWM_SHORT_CIRCUIT" 4 "PWM_OVER_MAX_DELTA_DUTY" 3 "PWM_UNDER_MIN_PERIOD" 2 "PWM_OVER_MAX_PERIOD" 1 "PWM_UNDER_MIN_DUTY" 0 "PWM_OVER_MAX_DUTY" ;
VAL_ 1293 TAS2_a032_PWMfaultRL 6 "PWM_OPEN_CIRCUIT" 5 "PWM_SHORT_CIRCUIT" 4 "PWM_OVER_MAX_DELTA_DUTY" 3 "PWM_UNDER_MIN_PERIOD" 2 "PWM_OVER_MAX_PERIOD" 1 "PWM_UNDER_MIN_DUTY" 0 "PWM_OVER_MAX_DUTY" ;
VAL_ 1293 TAS2_a033_PWMfaultRR 6 "PWM_OPEN_CIRCUIT" 5 "PWM_SHORT_CIRCUIT" 4 "PWM_OVER_MAX_DELTA_DUTY" 3 "PWM_UNDER_MIN_PERIOD" 2 "PWM_OVER_MAX_PERIOD" 1 "PWM_UNDER_MIN_DUTY" 0 "PWM_OVER_MAX_DUTY" ;
VAL_ 1293 TAS2_a034_PWMfaultFL 6 "PWM_OPEN_CIRCUIT" 5 "PWM_SHORT_CIRCUIT" 4 "PWM_OVER_MAX_DELTA_DUTY" 3 "PWM_UNDER_MIN_PERIOD" 2 "PWM_OVER_MAX_PERIOD" 1 "PWM_UNDER_MIN_DUTY" 0 "PWM_OVER_MAX_DUTY" ;
VAL_ 1293 TAS2_a035_PWMfaultFR 6 "PWM_OPEN_CIRCUIT" 5 "PWM_SHORT_CIRCUIT" 4 "PWM_OVER_MAX_DELTA_DUTY" 3 "PWM_UNDER_MIN_PERIOD" 2 "PWM_OVER_MAX_PERIOD" 1 "PWM_UNDER_MIN_DUTY" 0 "PWM_OVER_MAX_DUTY" ;
VAL_ 1293 TAS2_a036_PWMfaultRL 6 "PWM_OPEN_CIRCUIT" 5 "PWM_SHORT_CIRCUIT" 4 "PWM_OVER_MAX_DELTA_DUTY" 3 "PWM_UNDER_MIN_PERIOD" 2 "PWM_OVER_MAX_PERIOD" 1 "PWM_UNDER_MIN_DUTY" 0 "PWM_OVER_MAX_DUTY" ;
VAL_ 1293 TAS2_a037_PWMfaultRR 6 "PWM_OPEN_CIRCUIT" 5 "PWM_SHORT_CIRCUIT" 4 "PWM_OVER_MAX_DELTA_DUTY" 3 "PWM_UNDER_MIN_PERIOD" 2 "PWM_OVER_MAX_PERIOD" 1 "PWM_UNDER_MIN_DUTY" 0 "PWM_OVER_MAX_DUTY" ;
VAL_ 1293 TAS2_a038_PWMfaultFL 6 "PWM_OPEN_CIRCUIT" 5 "PWM_SHORT_CIRCUIT" 4 "PWM_OVER_MAX_DELTA_DUTY" 3 "PWM_UNDER_MIN_PERIOD" 2 "PWM_OVER_MAX_PERIOD" 1 "PWM_UNDER_MIN_DUTY" 0 "PWM_OVER_MAX_DUTY" ;
VAL_ 1293 TAS2_a039_PWMfaultFR 6 "PWM_OPEN_CIRCUIT" 5 "PWM_SHORT_CIRCUIT" 4 "PWM_OVER_MAX_DELTA_DUTY" 3 "PWM_UNDER_MIN_PERIOD" 2 "PWM_OVER_MAX_PERIOD" 1 "PWM_UNDER_MIN_DUTY" 0 "PWM_OVER_MAX_DUTY" ;
VAL_ 1293 TAS2_a040_PWMfaultRL 6 "PWM_OPEN_CIRCUIT" 5 "PWM_SHORT_CIRCUIT" 4 "PWM_OVER_MAX_DELTA_DUTY" 3 "PWM_UNDER_MIN_PERIOD" 2 "PWM_OVER_MAX_PERIOD" 1 "PWM_UNDER_MIN_DUTY" 0 "PWM_OVER_MAX_DUTY" ;
VAL_ 1293 TAS2_a041_PWMfaultRR 6 "PWM_OPEN_CIRCUIT" 5 "PWM_SHORT_CIRCUIT" 4 "PWM_OVER_MAX_DELTA_DUTY" 3 "PWM_UNDER_MIN_PERIOD" 2 "PWM_OVER_MAX_PERIOD" 1 "PWM_UNDER_MIN_DUTY" 0 "PWM_OVER_MAX_DUTY" ;
VAL_ 1293 TAS2_a129_valveFaultType 7 "VALVE_OTHER_CIRCUIT" 6 "VALVE_SENSOR_ERROR" 5 "VALVE_HS_DRIVE_STUCK_OFF" 4 "VALVE_HS_DRIVE_STUCK_ON" 3 "VALVE_SHORT_CIRCUIT_12V" 2 "VALVE_SHORT_CIRCUIT_GND" 1 "VALVE_OPEN_CIRCUIT" 0 "VALVE_OVER_DUTY_CYCLE_LIMIT" ;
VAL_ 1293 TAS2_a130_valveFaultType 7 "VALVE_OTHER_CIRCUIT" 6 "VALVE_SENSOR_ERROR" 5 "VALVE_HS_DRIVE_STUCK_OFF" 4 "VALVE_HS_DRIVE_STUCK_ON" 3 "VALVE_SHORT_CIRCUIT_12V" 2 "VALVE_SHORT_CIRCUIT_GND" 1 "VALVE_OPEN_CIRCUIT" 0 "VALVE_OVER_DUTY_CYCLE_LIMIT" ;
VAL_ 1293 TAS2_a131_valveFaultType 7 "VALVE_OTHER_CIRCUIT" 6 "VALVE_SENSOR_ERROR" 5 "VALVE_HS_DRIVE_STUCK_OFF" 4 "VALVE_HS_DRIVE_STUCK_ON" 3 "VALVE_SHORT_CIRCUIT_12V" 2 "VALVE_SHORT_CIRCUIT_GND" 1 "VALVE_OPEN_CIRCUIT" 0 "VALVE_OVER_DUTY_CYCLE_LIMIT" ;
VAL_ 1293 TAS2_a132_valveFaultType 7 "VALVE_OTHER_CIRCUIT" 6 "VALVE_SENSOR_ERROR" 5 "VALVE_HS_DRIVE_STUCK_OFF" 4 "VALVE_HS_DRIVE_STUCK_ON" 3 "VALVE_SHORT_CIRCUIT_12V" 2 "VALVE_SHORT_CIRCUIT_GND" 1 "VALVE_OPEN_CIRCUIT" 0 "VALVE_OVER_DUTY_CYCLE_LIMIT" ;
VAL_ 1293 TAS2_a133_valveFaultType 7 "VALVE_OTHER_CIRCUIT" 6 "VALVE_SENSOR_ERROR" 5 "VALVE_HS_DRIVE_STUCK_OFF" 4 "VALVE_HS_DRIVE_STUCK_ON" 3 "VALVE_SHORT_CIRCUIT_12V" 2 "VALVE_SHORT_CIRCUIT_GND" 1 "VALVE_OPEN_CIRCUIT" 0 "VALVE_OVER_DUTY_CYCLE_LIMIT" ;
VAL_ 1293 TAS2_a134_valveFaultType 7 "VALVE_OTHER_CIRCUIT" 6 "VALVE_SENSOR_ERROR" 5 "VALVE_HS_DRIVE_STUCK_OFF" 4 "VALVE_HS_DRIVE_STUCK_ON" 3 "VALVE_SHORT_CIRCUIT_12V" 2 "VALVE_SHORT_CIRCUIT_GND" 1 "VALVE_OPEN_CIRCUIT" 0 "VALVE_OVER_DUTY_CYCLE_LIMIT" ;
VAL_ 1293 TAS2_a135_valveFaultType 7 "VALVE_OTHER_CIRCUIT" 6 "VALVE_SENSOR_ERROR" 5 "VALVE_HS_DRIVE_STUCK_OFF" 4 "VALVE_HS_DRIVE_STUCK_ON" 3 "VALVE_SHORT_CIRCUIT_12V" 2 "VALVE_SHORT_CIRCUIT_GND" 1 "VALVE_OPEN_CIRCUIT" 0 "VALVE_OVER_DUTY_CYCLE_LIMIT" ;
VAL_ 1293 TAS2_a136_valveFaultType 7 "VALVE_OTHER_CIRCUIT" 6 "VALVE_SENSOR_ERROR" 5 "VALVE_HS_DRIVE_STUCK_OFF" 4 "VALVE_HS_DRIVE_STUCK_ON" 3 "VALVE_SHORT_CIRCUIT_12V" 2 "VALVE_SHORT_CIRCUIT_GND" 1 "VALVE_OPEN_CIRCUIT" 0 "VALVE_OVER_DUTY_CYCLE_LIMIT" ;
VAL_ 1293 TAS2_a137_valveFaultType 7 "VALVE_OTHER_CIRCUIT" 6 "VALVE_SENSOR_ERROR" 5 "VALVE_HS_DRIVE_STUCK_OFF" 4 "VALVE_HS_DRIVE_STUCK_ON" 3 "VALVE_SHORT_CIRCUIT_12V" 2 "VALVE_SHORT_CIRCUIT_GND" 1 "VALVE_OPEN_CIRCUIT" 0 "VALVE_OVER_DUTY_CYCLE_LIMIT" ;
VAL_ 1293 TAS2_a138_valveFaultType 7 "VALVE_OTHER_CIRCUIT" 6 "VALVE_SENSOR_ERROR" 5 "VALVE_HS_DRIVE_STUCK_OFF" 4 "VALVE_HS_DRIVE_STUCK_ON" 3 "VALVE_SHORT_CIRCUIT_12V" 2 "VALVE_SHORT_CIRCUIT_GND" 1 "VALVE_OPEN_CIRCUIT" 0 "VALVE_OVER_DUTY_CYCLE_LIMIT" ;
VAL_ 1293 TAS2_a139_valveFaultType 7 "VALVE_OTHER_CIRCUIT" 6 "VALVE_SENSOR_ERROR" 5 "VALVE_HS_DRIVE_STUCK_OFF" 4 "VALVE_HS_DRIVE_STUCK_ON" 3 "VALVE_SHORT_CIRCUIT_12V" 2 "VALVE_SHORT_CIRCUIT_GND" 1 "VALVE_OPEN_CIRCUIT" 0 "VALVE_OVER_DUTY_CYCLE_LIMIT" ;
VAL_ 1293 TAS2_a140_valveFaultType 7 "VALVE_OTHER_CIRCUIT" 6 "VALVE_SENSOR_ERROR" 5 "VALVE_HS_DRIVE_STUCK_OFF" 4 "VALVE_HS_DRIVE_STUCK_ON" 3 "VALVE_SHORT_CIRCUIT_12V" 2 "VALVE_SHORT_CIRCUIT_GND" 1 "VALVE_OPEN_CIRCUIT" 0 "VALVE_OVER_DUTY_CYCLE_LIMIT" ;
VAL_ 1293 TAS2_a141_valveFaultType 7 "VALVE_OTHER_CIRCUIT" 6 "VALVE_SENSOR_ERROR" 5 "VALVE_HS_DRIVE_STUCK_OFF" 4 "VALVE_HS_DRIVE_STUCK_ON" 3 "VALVE_SHORT_CIRCUIT_12V" 2 "VALVE_SHORT_CIRCUIT_GND" 1 "VALVE_OPEN_CIRCUIT" 0 "VALVE_OVER_DUTY_CYCLE_LIMIT" ;
VAL_ 1293 TAS2_a142_valveFaultType 7 "VALVE_OTHER_CIRCUIT" 6 "VALVE_SENSOR_ERROR" 5 "VALVE_HS_DRIVE_STUCK_OFF" 4 "VALVE_HS_DRIVE_STUCK_ON" 3 "VALVE_SHORT_CIRCUIT_12V" 2 "VALVE_SHORT_CIRCUIT_GND" 1 "VALVE_OPEN_CIRCUIT" 0 "VALVE_OVER_DUTY_CYCLE_LIMIT" ;
VAL_ 1293 TAS2_a143_valveFaultType 7 "VALVE_OTHER_CIRCUIT" 6 "VALVE_SENSOR_ERROR" 5 "VALVE_HS_DRIVE_STUCK_OFF" 4 "VALVE_HS_DRIVE_STUCK_ON" 3 "VALVE_SHORT_CIRCUIT_12V" 2 "VALVE_SHORT_CIRCUIT_GND" 1 "VALVE_OPEN_CIRCUIT" 0 "VALVE_OVER_DUTY_CYCLE_LIMIT" ;
VAL_ 1293 TAS2_a144_valveFaultType 7 "VALVE_OTHER_CIRCUIT" 6 "VALVE_SENSOR_ERROR" 5 "VALVE_HS_DRIVE_STUCK_OFF" 4 "VALVE_HS_DRIVE_STUCK_ON" 3 "VALVE_SHORT_CIRCUIT_12V" 2 "VALVE_SHORT_CIRCUIT_GND" 1 "VALVE_OPEN_CIRCUIT" 0 "VALVE_OVER_DUTY_CYCLE_LIMIT" ;
VAL_ 1293 TAS2_a145_valveFaultType 7 "VALVE_OTHER_CIRCUIT" 6 "VALVE_SENSOR_ERROR" 5 "VALVE_HS_DRIVE_STUCK_OFF" 4 "VALVE_HS_DRIVE_STUCK_ON" 3 "VALVE_SHORT_CIRCUIT_12V" 2 "VALVE_SHORT_CIRCUIT_GND" 1 "VALVE_OPEN_CIRCUIT" 0 "VALVE_OVER_DUTY_CYCLE_LIMIT" ;
VAL_ 1293 TAS2_a146_valveFaultType 7 "VALVE_OTHER_CIRCUIT" 6 "VALVE_SENSOR_ERROR" 5 "VALVE_HS_DRIVE_STUCK_OFF" 4 "VALVE_HS_DRIVE_STUCK_ON" 3 "VALVE_SHORT_CIRCUIT_12V" 2 "VALVE_SHORT_CIRCUIT_GND" 1 "VALVE_OPEN_CIRCUIT" 0 "VALVE_OVER_DUTY_CYCLE_LIMIT" ;
VAL_ 1293 TAS2_a147_valveFaultType 7 "VALVE_OTHER_CIRCUIT" 6 "VALVE_SENSOR_ERROR" 5 "VALVE_HS_DRIVE_STUCK_OFF" 4 "VALVE_HS_DRIVE_STUCK_ON" 3 "VALVE_SHORT_CIRCUIT_12V" 2 "VALVE_SHORT_CIRCUIT_GND" 1 "VALVE_OPEN_CIRCUIT" 0 "VALVE_OVER_DUTY_CYCLE_LIMIT" ;
VAL_ 1293 TAS2_a148_valveFaultType 7 "VALVE_OTHER_CIRCUIT" 6 "VALVE_SENSOR_ERROR" 5 "VALVE_HS_DRIVE_STUCK_OFF" 4 "VALVE_HS_DRIVE_STUCK_ON" 3 "VALVE_SHORT_CIRCUIT_12V" 2 "VALVE_SHORT_CIRCUIT_GND" 1 "VALVE_OPEN_CIRCUIT" 0 "VALVE_OVER_DUTY_CYCLE_LIMIT" ;
VAL_ 1293 TAS2_a149_valveFaultType 7 "VALVE_OTHER_CIRCUIT" 6 "VALVE_SENSOR_ERROR" 5 "VALVE_HS_DRIVE_STUCK_OFF" 4 "VALVE_HS_DRIVE_STUCK_ON" 3 "VALVE_SHORT_CIRCUIT_12V" 2 "VALVE_SHORT_CIRCUIT_GND" 1 "VALVE_OPEN_CIRCUIT" 0 "VALVE_OVER_DUTY_CYCLE_LIMIT" ;
VAL_ 1293 TAS2_a150_valveFaultType 7 "VALVE_OTHER_CIRCUIT" 6 "VALVE_SENSOR_ERROR" 5 "VALVE_HS_DRIVE_STUCK_OFF" 4 "VALVE_HS_DRIVE_STUCK_ON" 3 "VALVE_SHORT_CIRCUIT_12V" 2 "VALVE_SHORT_CIRCUIT_GND" 1 "VALVE_OPEN_CIRCUIT" 0 "VALVE_OVER_DUTY_CYCLE_LIMIT" ;
VAL_ 1293 TAS2_a151_valveFaultType 7 "VALVE_OTHER_CIRCUIT" 6 "VALVE_SENSOR_ERROR" 5 "VALVE_HS_DRIVE_STUCK_OFF" 4 "VALVE_HS_DRIVE_STUCK_ON" 3 "VALVE_SHORT_CIRCUIT_12V" 2 "VALVE_SHORT_CIRCUIT_GND" 1 "VALVE_OPEN_CIRCUIT" 0 "VALVE_OVER_DUTY_CYCLE_LIMIT" ;
VAL_ 1293 TAS2_a152_valveFaultType 7 "VALVE_OTHER_CIRCUIT" 6 "VALVE_SENSOR_ERROR" 5 "VALVE_HS_DRIVE_STUCK_OFF" 4 "VALVE_HS_DRIVE_STUCK_ON" 3 "VALVE_SHORT_CIRCUIT_12V" 2 "VALVE_SHORT_CIRCUIT_GND" 1 "VALVE_OPEN_CIRCUIT" 0 "VALVE_OVER_DUTY_CYCLE_LIMIT" ;
VAL_ 1293 TAS2_a153_valveFaultType 7 "VALVE_OTHER_CIRCUIT" 6 "VALVE_SENSOR_ERROR" 5 "VALVE_HS_DRIVE_STUCK_OFF" 4 "VALVE_HS_DRIVE_STUCK_ON" 3 "VALVE_SHORT_CIRCUIT_12V" 2 "VALVE_SHORT_CIRCUIT_GND" 1 "VALVE_OPEN_CIRCUIT" 0 "VALVE_OVER_DUTY_CYCLE_LIMIT" ;
VAL_ 1293 TAS2_a154_valveFaultType 7 "VALVE_OTHER_CIRCUIT" 6 "VALVE_SENSOR_ERROR" 5 "VALVE_HS_DRIVE_STUCK_OFF" 4 "VALVE_HS_DRIVE_STUCK_ON" 3 "VALVE_SHORT_CIRCUIT_12V" 2 "VALVE_SHORT_CIRCUIT_GND" 1 "VALVE_OPEN_CIRCUIT" 0 "VALVE_OVER_DUTY_CYCLE_LIMIT" ;
VAL_ 1293 TAS2_a155_valveFaultType 7 "VALVE_OTHER_CIRCUIT" 6 "VALVE_SENSOR_ERROR" 5 "VALVE_HS_DRIVE_STUCK_OFF" 4 "VALVE_HS_DRIVE_STUCK_ON" 3 "VALVE_SHORT_CIRCUIT_12V" 2 "VALVE_SHORT_CIRCUIT_GND" 1 "VALVE_OPEN_CIRCUIT" 0 "VALVE_OVER_DUTY_CYCLE_LIMIT" ;
VAL_ 1293 TAS2_a156_valveFaultType 7 "VALVE_OTHER_CIRCUIT" 6 "VALVE_SENSOR_ERROR" 5 "VALVE_HS_DRIVE_STUCK_OFF" 4 "VALVE_HS_DRIVE_STUCK_ON" 3 "VALVE_SHORT_CIRCUIT_12V" 2 "VALVE_SHORT_CIRCUIT_GND" 1 "VALVE_OPEN_CIRCUIT" 0 "VALVE_OVER_DUTY_CYCLE_LIMIT" ;
VAL_ 1293 TAS2_a157_valveFaultType 7 "VALVE_OTHER_CIRCUIT" 6 "VALVE_SENSOR_ERROR" 5 "VALVE_HS_DRIVE_STUCK_OFF" 4 "VALVE_HS_DRIVE_STUCK_ON" 3 "VALVE_SHORT_CIRCUIT_12V" 2 "VALVE_SHORT_CIRCUIT_GND" 1 "VALVE_OPEN_CIRCUIT" 0 "VALVE_OVER_DUTY_CYCLE_LIMIT" ;
VAL_ 1293 TAS2_a158_valveFaultType 7 "VALVE_OTHER_CIRCUIT" 6 "VALVE_SENSOR_ERROR" 5 "VALVE_HS_DRIVE_STUCK_OFF" 4 "VALVE_HS_DRIVE_STUCK_ON" 3 "VALVE_SHORT_CIRCUIT_12V" 2 "VALVE_SHORT_CIRCUIT_GND" 1 "VALVE_OPEN_CIRCUIT" 0 "VALVE_OVER_DUTY_CYCLE_LIMIT" ;
VAL_ 1293 TAS2_a159_valveFaultType 7 "VALVE_OTHER_CIRCUIT" 6 "VALVE_SENSOR_ERROR" 5 "VALVE_HS_DRIVE_STUCK_OFF" 4 "VALVE_HS_DRIVE_STUCK_ON" 3 "VALVE_SHORT_CIRCUIT_12V" 2 "VALVE_SHORT_CIRCUIT_GND" 1 "VALVE_OPEN_CIRCUIT" 0 "VALVE_OVER_DUTY_CYCLE_LIMIT" ;
VAL_ 1293 TAS2_a160_valveFaultType 7 "VALVE_OTHER_CIRCUIT" 6 "VALVE_SENSOR_ERROR" 5 "VALVE_HS_DRIVE_STUCK_OFF" 4 "VALVE_HS_DRIVE_STUCK_ON" 3 "VALVE_SHORT_CIRCUIT_12V" 2 "VALVE_SHORT_CIRCUIT_GND" 1 "VALVE_OPEN_CIRCUIT" 0 "VALVE_OVER_DUTY_CYCLE_LIMIT" ;
VAL_ 1293 TAS2_a165_damperValveFault 10 "LOW_SIDE_STATUS_IMPLAUSIBLE" 9 "CURRENT_MISMATCH" 8 "CURRENT_IMPLAUSIBLE" 7 "HIGH_RESISTANCE" 6 "LOW_RESISTANCE" 5 "CROSS_CONNECTION_SHORT" 4 "OPEN_CIRCUIT" 3 "VOLTAGE_ON_CIRCUIT" 2 "SHORT_TO_GND" 1 "SHORT_TO_VBAT" 0 "NONE_UNUSED" ;
VAL_ 1293 TAS2_a166_damperValveFault 10 "LOW_SIDE_STATUS_IMPLAUSIBLE" 9 "CURRENT_MISMATCH" 8 "CURRENT_IMPLAUSIBLE" 7 "HIGH_RESISTANCE" 6 "LOW_RESISTANCE" 5 "CROSS_CONNECTION_SHORT" 4 "OPEN_CIRCUIT" 3 "VOLTAGE_ON_CIRCUIT" 2 "SHORT_TO_GND" 1 "SHORT_TO_VBAT" 0 "NONE_UNUSED" ;
VAL_ 1293 TAS2_a167_damperValveFault 10 "LOW_SIDE_STATUS_IMPLAUSIBLE" 9 "CURRENT_MISMATCH" 8 "CURRENT_IMPLAUSIBLE" 7 "HIGH_RESISTANCE" 6 "LOW_RESISTANCE" 5 "CROSS_CONNECTION_SHORT" 4 "OPEN_CIRCUIT" 3 "VOLTAGE_ON_CIRCUIT" 2 "SHORT_TO_GND" 1 "SHORT_TO_VBAT" 0 "NONE_UNUSED" ;
VAL_ 1293 TAS2_a168_damperValveFault 10 "LOW_SIDE_STATUS_IMPLAUSIBLE" 9 "CURRENT_MISMATCH" 8 "CURRENT_IMPLAUSIBLE" 7 "HIGH_RESISTANCE" 6 "LOW_RESISTANCE" 5 "CROSS_CONNECTION_SHORT" 4 "OPEN_CIRCUIT" 3 "VOLTAGE_ON_CIRCUIT" 2 "SHORT_TO_GND" 1 "SHORT_TO_VBAT" 0 "NONE_UNUSED" ;
VAL_ 1293 TAS2_a169_damperValveFault 10 "LOW_SIDE_STATUS_IMPLAUSIBLE" 9 "CURRENT_MISMATCH" 8 "CURRENT_IMPLAUSIBLE" 7 "HIGH_RESISTANCE" 6 "LOW_RESISTANCE" 5 "CROSS_CONNECTION_SHORT" 4 "OPEN_CIRCUIT" 3 "VOLTAGE_ON_CIRCUIT" 2 "SHORT_TO_GND" 1 "SHORT_TO_VBAT" 0 "NONE_UNUSED" ;
VAL_ 1293 TAS2_a170_damperValveFault 10 "LOW_SIDE_STATUS_IMPLAUSIBLE" 9 "CURRENT_MISMATCH" 8 "CURRENT_IMPLAUSIBLE" 7 "HIGH_RESISTANCE" 6 "LOW_RESISTANCE" 5 "CROSS_CONNECTION_SHORT" 4 "OPEN_CIRCUIT" 3 "VOLTAGE_ON_CIRCUIT" 2 "SHORT_TO_GND" 1 "SHORT_TO_VBAT" 0 "NONE_UNUSED" ;
VAL_ 1293 TAS2_a171_damperValveFault 10 "LOW_SIDE_STATUS_IMPLAUSIBLE" 9 "CURRENT_MISMATCH" 8 "CURRENT_IMPLAUSIBLE" 7 "HIGH_RESISTANCE" 6 "LOW_RESISTANCE" 5 "CROSS_CONNECTION_SHORT" 4 "OPEN_CIRCUIT" 3 "VOLTAGE_ON_CIRCUIT" 2 "SHORT_TO_GND" 1 "SHORT_TO_VBAT" 0 "NONE_UNUSED" ;
VAL_ 1293 TAS2_a172_damperValveFault 10 "LOW_SIDE_STATUS_IMPLAUSIBLE" 9 "CURRENT_MISMATCH" 8 "CURRENT_IMPLAUSIBLE" 7 "HIGH_RESISTANCE" 6 "LOW_RESISTANCE" 5 "CROSS_CONNECTION_SHORT" 4 "OPEN_CIRCUIT" 3 "VOLTAGE_ON_CIRCUIT" 2 "SHORT_TO_GND" 1 "SHORT_TO_VBAT" 0 "NONE_UNUSED" ;
VAL_ 1293 TAS2_a226_PWMfaultFL 6 "PWM_OPEN_CIRCUIT" 5 "PWM_SHORT_CIRCUIT" 4 "PWM_OVER_MAX_DELTA_DUTY" 3 "PWM_UNDER_MIN_PERIOD" 2 "PWM_OVER_MAX_PERIOD" 1 "PWM_UNDER_MIN_DUTY" 0 "PWM_OVER_MAX_DUTY" ;
VAL_ 1293 TAS2_a227_PWMfaultFR 6 "PWM_OPEN_CIRCUIT" 5 "PWM_SHORT_CIRCUIT" 4 "PWM_OVER_MAX_DELTA_DUTY" 3 "PWM_UNDER_MIN_PERIOD" 2 "PWM_OVER_MAX_PERIOD" 1 "PWM_UNDER_MIN_DUTY" 0 "PWM_OVER_MAX_DUTY" ;
VAL_ 1293 TAS2_a228_PWMfaultRL 6 "PWM_OPEN_CIRCUIT" 5 "PWM_SHORT_CIRCUIT" 4 "PWM_OVER_MAX_DELTA_DUTY" 3 "PWM_UNDER_MIN_PERIOD" 2 "PWM_OVER_MAX_PERIOD" 1 "PWM_UNDER_MIN_DUTY" 0 "PWM_OVER_MAX_DUTY" ;
VAL_ 1293 TAS2_a229_PWMfaultRR 6 "PWM_OPEN_CIRCUIT" 5 "PWM_SHORT_CIRCUIT" 4 "PWM_OVER_MAX_DELTA_DUTY" 3 "PWM_UNDER_MIN_PERIOD" 2 "PWM_OVER_MAX_PERIOD" 1 "PWM_UNDER_MIN_DUTY" 0 "PWM_OVER_MAX_DUTY" ;
VAL_ 1293 TAS2_a296_detectedChassisType 3 "CHASSIS_MODEL3" 2 "CHASSIS_MODELX" 1 "CHASSIS_MODELS" 0 "CHASSIS_UNKNOWN" ;
VAL_ 1293 TAS2_a296_expectedChassisType 3 "CHASSIS_MODEL3" 2 "CHASSIS_MODELX" 1 "CHASSIS_MODELS" 0 "CHASSIS_UNKNOWN" ;
VAL_ 1293 TAS2_a299_corner 3 "REAR_RIGHT" 2 "REAR_LEFT" 1 "FRONT_RIGHT" 0 "FRONT_LEFT" ;
VAL_ 1293 TAS2_a299_type 1 "STEADY_STATE" 0 "DYNAMIC" ;
VAL_ 1293 TAS2_a299_currentRideHeight 4 "TAS_VERY_LOW" 3 "TAS_LOW" 2 "TAS_STANDARD" 1 "TAS_HIGH" 0 "TAS_VERY_HIGH" ;
VAL_ 1293 TAS2_a303_currentRideHeight 4 "TAS_VERY_LOW" 3 "TAS_LOW" 2 "TAS_STANDARD" 1 "TAS_HIGH" 0 "TAS_VERY_HIGH" ;
VAL_ 1293 TAS2_a305_corner 3 "REAR_RIGHT" 2 "REAR_LEFT" 1 "FRONT_RIGHT" 0 "FRONT_LEFT" ;
VAL_ 1293 TAS2_a306_corner 3 "REAR_RIGHT" 2 "REAR_LEFT" 1 "FRONT_RIGHT" 0 "FRONT_LEFT" ;
VAL_ 1293 TAS2_a306_direction 1 "COMPRESSION" 0 "REBOUND" ;
VAL_ 1293 TAS2_a309_corner 3 "REAR_RIGHT" 2 "REAR_LEFT" 1 "FRONT_RIGHT" 0 "FRONT_LEFT" ;
VAL_ 1293 TAS2_a309_direction 1 "COMPRESSION" 0 "REBOUND" ;
VAL_ 1293 TAS2_a309_currentRideHeight 4 "TAS_VERY_LOW" 3 "TAS_LOW" 2 "TAS_STANDARD" 1 "TAS_HIGH" 0 "TAS_VERY_HIGH" ;
VAL_ 1292 TAS2_matrixIndex 5 "TAS2_AlertMatrix5" 4 "TAS2_AlertMatrix4" 3 "TAS2_AlertMatrix3" 2 "TAS2_AlertMatrix2" 1 "TAS2_AlertMatrix1" 0 "TAS2_AlertMatrix0" ;
VAL_ 1433 TAS2_current_FL_C 255 "SNA" ;
VAL_ 1433 TAS2_current_FL_R 255 "SNA" ;
VAL_ 1433 TAS2_current_FR_C 255 "SNA" ;
VAL_ 1433 TAS2_current_FR_R 255 "SNA" ;
VAL_ 1433 TAS2_current_RL_C 255 "SNA" ;
VAL_ 1433 TAS2_current_RL_R 255 "SNA" ;
VAL_ 1433 TAS2_current_RR_C 255 "SNA" ;
VAL_ 1433 TAS2_current_RR_R 255 "SNA" ;
VAL_ 1398 TAS2_endstopState 1 "TAS_DAMPING_STATE_ACTIVE" 0 "TAS_DAMPING_STATE_STANDBY" ;
VAL_ 1398 TAS2_continuousControlState 1 "TAS_DAMPING_STATE_ACTIVE" 0 "TAS_DAMPING_STATE_STANDBY" ;
VAL_ 1398 TAS2_roadCondition 255 "SNA" ;
VAL_ 1398 TAS2_McQueenBoostAxleFront 3 "TAS_ACTION_ACTIVE" 2 "TAS_ACTION_ARMED" 1 "TAS_ACTION_STANDBY" 0 "TAS_ACTION_DISABLED" ;
VAL_ 1398 TAS2_McQueenBoostAxleRear 3 "TAS_ACTION_ACTIVE" 2 "TAS_ACTION_ARMED" 1 "TAS_ACTION_STANDBY" 0 "TAS_ACTION_DISABLED" ;
VAL_ 1398 TAS2_speedBumpAxleFront 3 "TAS_ACTION_ACTIVE" 2 "TAS_ACTION_ARMED" 1 "TAS_ACTION_STANDBY" 0 "TAS_ACTION_DISABLED" ;
VAL_ 1398 TAS2_speedBumpAxleRear 3 "TAS_ACTION_ACTIVE" 2 "TAS_ACTION_ARMED" 1 "TAS_ACTION_STANDBY" 0 "TAS_ACTION_DISABLED" ;
VAL_ 1398 TAS2_holeProtectFL 3 "TAS_ACTION_ACTIVE" 2 "TAS_ACTION_ARMED" 1 "TAS_ACTION_STANDBY" 0 "TAS_ACTION_DISABLED" ;
VAL_ 1398 TAS2_holeProtectFR 3 "TAS_ACTION_ACTIVE" 2 "TAS_ACTION_ARMED" 1 "TAS_ACTION_STANDBY" 0 "TAS_ACTION_DISABLED" ;
VAL_ 1398 TAS2_holeProtectRL 3 "TAS_ACTION_ACTIVE" 2 "TAS_ACTION_ARMED" 1 "TAS_ACTION_STANDBY" 0 "TAS_ACTION_DISABLED" ;
VAL_ 1398 TAS2_holeProtectRR 3 "TAS_ACTION_ACTIVE" 2 "TAS_ACTION_ARMED" 1 "TAS_ACTION_STANDBY" 0 "TAS_ACTION_DISABLED" ;
VAL_ 1398 TAS2_stepProtectFL 3 "TAS_ACTION_ACTIVE" 2 "TAS_ACTION_ARMED" 1 "TAS_ACTION_STANDBY" 0 "TAS_ACTION_DISABLED" ;
VAL_ 1398 TAS2_stepProtectFR 3 "TAS_ACTION_ACTIVE" 2 "TAS_ACTION_ARMED" 1 "TAS_ACTION_STANDBY" 0 "TAS_ACTION_DISABLED" ;
VAL_ 1398 TAS2_stepProtectRL 3 "TAS_ACTION_ACTIVE" 2 "TAS_ACTION_ARMED" 1 "TAS_ACTION_STANDBY" 0 "TAS_ACTION_DISABLED" ;
VAL_ 1398 TAS2_stepProtectRR 3 "TAS_ACTION_ACTIVE" 2 "TAS_ACTION_ARMED" 1 "TAS_ACTION_STANDBY" 0 "TAS_ACTION_DISABLED" ;
VAL_ 1398 TAS2_FDUTorqueCorruptionScale 15 "SNA" ;
VAL_ 1019 TAS_CPULoad1msTask 255 "SNA" ;
VAL_ 1019 TAS_CPULoad10msTask 255 "SNA" ;
VAL_ 1019 TAS_CPULoad100msTask 255 "SNA" ;
VAL_ 1019 TAS_CPULoad1000msTask 255 "SNA" ;
VAL_ 1019 TAS_CPULoadTotal 255 "SNA" ;
VAL_ 1291 TAS_alertID 295 "TAS_a295_targetHeightNotMet" 294 "TAS_a294_rearAxleTooLow" 293 "TAS_a293_frontAxleTooLow" 292 "TAS_a292_rearAxleTooHigh" 291 "TAS_a291_frontAxleTooHigh" 290 "TAS_a290_twistSustainedAtSpeed" 289 "TAS_a289_driveCycleStats4" 288 "TAS_a288_driveCycleStats3" 287 "TAS_a287_driveCycleStats2" 286 "TAS_a286_driveCycleStats1" 230 "TAS_a230_geofenceNotification" 229 "TAS_a229_PWMfastDetectRR" 228 "TAS_a228_PWMfastDetectRL" 227 "TAS_a227_PWMfastDetectFR" 226 "TAS_a226_PWMfastDetectFL" 225 "TAS_a225_galleryPressureTooHigh" 224 "TAS_a224_openAirline" 223 "TAS_a223_blockedAirline" 222 "TAS_a222_compressorPrefillFault" 221 "TAS_a221_valveLeakDetected" 220 "TAS_a220_exhaustGalleryFault" 218 "TAS_a218_limpHomeMode40" 217 "TAS_a217_limpHomeMode30" 216 "TAS_a216_limpHomeMode20" 215 "TAS_a215_limpHomeMode10" 214 "TAS_a214_redWarningLamp" 213 "TAS_a213_yellowWarningLamp" 211 "TAS_a211_noRideHeightCalib" 210 "TAS_a210_outOfRangeCalibration" 201 "TAS_a201_lowHVBattery" 200 "TAS_a200_jackModeActive" 176 "TAS_a176_staticLeakDetectRR" 175 "TAS_a175_staticLeakDetectRL" 174 "TAS_a174_staticLeakDetectFR" 173 "TAS_a173_staticLeakDetectFL" 163 "TAS_a163_reservoirFillDisabled" 162 "TAS_a162_compressorValveOpenGND" 161 "TAS_a161_valveBlockOpenGND" 160 "TAS_a160_otherCircuitCompressor" 159 "TAS_a159_otherCircuitBoost" 158 "TAS_a158_otherCircuitExhaust" 157 "TAS_a157_otherCircuitReservoir" 156 "TAS_a156_otherCircuitRR" 155 "TAS_a155_otherCircuitRL" 154 "TAS_a154_otherCircuitFR" 153 "TAS_a153_otherCircuitFL" 152 "TAS_a152_boardFaultCompressor" 151 "TAS_a151_boardFaultBoost" 150 "TAS_a150_boardFaultExhaust" 149 "TAS_a149_boardFaultReservoir" 148 "TAS_a148_boardFaultRR" 147 "TAS_a147_boardFaultRL" 146 "TAS_a146_boardFaultFR" 145 "TAS_a145_boardFaultFL" 144 "TAS_a144_shortCircuitCompressor" 143 "TAS_a143_shortCircuitBoost" 142 "TAS_a142_shortCircuitExhaust" 141 "TAS_a141_shortCircuitReservoir" 140 "TAS_a140_shortCircuitRR" 139 "TAS_a139_shortCircuitRL" 138 "TAS_a138_shortCircuitFR" 137 "TAS_a137_shortCircuitFL" 136 "TAS_a136_openCircuitCompressor" 135 "TAS_a135_openCircuitBoost" 134 "TAS_a134_openCircuitExhaust" 133 "TAS_a133_openCircuitReservoir" 132 "TAS_a132_openCircuitRR" 131 "TAS_a131_openCircuitRL" 130 "TAS_a130_openCircuitFR" 129 "TAS_a129_openCircuitFL" 128 "TAS_a128_maxDutyCompressor" 127 "TAS_a127_maxDutyBoost" 126 "TAS_a126_maxDutyExhaust" 125 "TAS_a125_maxDutyReservoir" 124 "TAS_a124_maxDutyRR" 123 "TAS_a123_maxDutyRL" 122 "TAS_a122_maxDutyFR" 121 "TAS_a121_maxDutyFL" 107 "TAS_a107_HighStackUsage" 106 "TAS_a106_HighCPULoad" 105 "TAS_a105_ECUDebugMode" 103 "TAS_a103_GTW_MIA" 102 "TAS_a102_DI_MIA" 101 "TAS_a101_ESP_MIA" 100 "TAS_a100_SCCM_MIA" 99 "TAS_a099_EFUSE_MIA" 98 "TAS_a098_MCU_MIA" 93 "TAS_a093_OTPError" 78 "TAS_a078_pressureSigVTooHigh" 77 "TAS_a077_pressureSigVTooLow" 76 "TAS_a076_overVoltage5VOffBoard" 75 "TAS_a075_underVoltage5VOffBoard" 74 "TAS_a074_shortCircuit5VOffBoard" 73 "TAS_a073_underVoltage5VOnBoard" 72 "TAS_a072_shortCircuit5VOnBoard" 71 "TAS_a071_overVoltage12V" 70 "TAS_a070_underVoltage12V" 62 "TAS_a062_XCPWasConnected" 61 "TAS_a061_XCPConnected" 46 "TAS_a046_Task1000msError" 45 "TAS_a045_Task100msError" 44 "TAS_a044_Task10msError" 43 "TAS_a043_Task1msError" 41 "TAS_a041_PWMopenRR" 40 "TAS_a040_PWMopenRL" 39 "TAS_a039_PWMopenFR" 38 "TAS_a038_PWMopenFL" 37 "TAS_a037_PWMshortRR" 36 "TAS_a036_PWMshortRL" 35 "TAS_a035_PWMshortFR" 34 "TAS_a034_PWMshortFL" 33 "TAS_a033_PWMerrorRR" 32 "TAS_a032_PWMerrorRL" 31 "TAS_a031_PWMerrorFR" 30 "TAS_a030_PWMerrorFL" 25 "TAS_a025_CrashEvent" 22 "TAS_a022_TaskInitError" 21 "TAS_a021_TaskSchedulerError" 15 "TAS_a015_NVMMAlert" 12 "TAS_a012_CPUReset" 3 "TAS_a003_SWAssertion" 2 "TAS_a002_PowerLossReset" 1 "TAS_a001_WatchdogReset" 0 "TAS_ALERT_DO_NOT_USE_ZERO" ;
VAL_ 1291 TAS_alertType 1 "ALERT_SET" 0 "ALERT_CLEARED" ;
VAL_ 1291 TAS_a030_PWMfaultFL 6 "PWM_OPEN_CIRCUIT" 5 "PWM_SHORT_CIRCUIT" 4 "PWM_OVER_MAX_DELTA_DUTY" 3 "PWM_UNDER_MIN_PERIOD" 2 "PWM_OVER_MAX_PERIOD" 1 "PWM_UNDER_MIN_DUTY" 0 "PWM_OVER_MAX_DUTY" ;
VAL_ 1291 TAS_a031_PWMfaultFR 6 "PWM_OPEN_CIRCUIT" 5 "PWM_SHORT_CIRCUIT" 4 "PWM_OVER_MAX_DELTA_DUTY" 3 "PWM_UNDER_MIN_PERIOD" 2 "PWM_OVER_MAX_PERIOD" 1 "PWM_UNDER_MIN_DUTY" 0 "PWM_OVER_MAX_DUTY" ;
VAL_ 1291 TAS_a032_PWMfaultRL 6 "PWM_OPEN_CIRCUIT" 5 "PWM_SHORT_CIRCUIT" 4 "PWM_OVER_MAX_DELTA_DUTY" 3 "PWM_UNDER_MIN_PERIOD" 2 "PWM_OVER_MAX_PERIOD" 1 "PWM_UNDER_MIN_DUTY" 0 "PWM_OVER_MAX_DUTY" ;
VAL_ 1291 TAS_a033_PWMfaultRR 6 "PWM_OPEN_CIRCUIT" 5 "PWM_SHORT_CIRCUIT" 4 "PWM_OVER_MAX_DELTA_DUTY" 3 "PWM_UNDER_MIN_PERIOD" 2 "PWM_OVER_MAX_PERIOD" 1 "PWM_UNDER_MIN_DUTY" 0 "PWM_OVER_MAX_DUTY" ;
VAL_ 1291 TAS_a034_PWMfaultFL 6 "PWM_OPEN_CIRCUIT" 5 "PWM_SHORT_CIRCUIT" 4 "PWM_OVER_MAX_DELTA_DUTY" 3 "PWM_UNDER_MIN_PERIOD" 2 "PWM_OVER_MAX_PERIOD" 1 "PWM_UNDER_MIN_DUTY" 0 "PWM_OVER_MAX_DUTY" ;
VAL_ 1291 TAS_a035_PWMfaultFR 6 "PWM_OPEN_CIRCUIT" 5 "PWM_SHORT_CIRCUIT" 4 "PWM_OVER_MAX_DELTA_DUTY" 3 "PWM_UNDER_MIN_PERIOD" 2 "PWM_OVER_MAX_PERIOD" 1 "PWM_UNDER_MIN_DUTY" 0 "PWM_OVER_MAX_DUTY" ;
VAL_ 1291 TAS_a036_PWMfaultRL 6 "PWM_OPEN_CIRCUIT" 5 "PWM_SHORT_CIRCUIT" 4 "PWM_OVER_MAX_DELTA_DUTY" 3 "PWM_UNDER_MIN_PERIOD" 2 "PWM_OVER_MAX_PERIOD" 1 "PWM_UNDER_MIN_DUTY" 0 "PWM_OVER_MAX_DUTY" ;
VAL_ 1291 TAS_a037_PWMfaultRR 6 "PWM_OPEN_CIRCUIT" 5 "PWM_SHORT_CIRCUIT" 4 "PWM_OVER_MAX_DELTA_DUTY" 3 "PWM_UNDER_MIN_PERIOD" 2 "PWM_OVER_MAX_PERIOD" 1 "PWM_UNDER_MIN_DUTY" 0 "PWM_OVER_MAX_DUTY" ;
VAL_ 1291 TAS_a038_PWMfaultFL 6 "PWM_OPEN_CIRCUIT" 5 "PWM_SHORT_CIRCUIT" 4 "PWM_OVER_MAX_DELTA_DUTY" 3 "PWM_UNDER_MIN_PERIOD" 2 "PWM_OVER_MAX_PERIOD" 1 "PWM_UNDER_MIN_DUTY" 0 "PWM_OVER_MAX_DUTY" ;
VAL_ 1291 TAS_a039_PWMfaultFR 6 "PWM_OPEN_CIRCUIT" 5 "PWM_SHORT_CIRCUIT" 4 "PWM_OVER_MAX_DELTA_DUTY" 3 "PWM_UNDER_MIN_PERIOD" 2 "PWM_OVER_MAX_PERIOD" 1 "PWM_UNDER_MIN_DUTY" 0 "PWM_OVER_MAX_DUTY" ;
VAL_ 1291 TAS_a040_PWMfaultRL 6 "PWM_OPEN_CIRCUIT" 5 "PWM_SHORT_CIRCUIT" 4 "PWM_OVER_MAX_DELTA_DUTY" 3 "PWM_UNDER_MIN_PERIOD" 2 "PWM_OVER_MAX_PERIOD" 1 "PWM_UNDER_MIN_DUTY" 0 "PWM_OVER_MAX_DUTY" ;
VAL_ 1291 TAS_a041_PWMfaultRR 6 "PWM_OPEN_CIRCUIT" 5 "PWM_SHORT_CIRCUIT" 4 "PWM_OVER_MAX_DELTA_DUTY" 3 "PWM_UNDER_MIN_PERIOD" 2 "PWM_OVER_MAX_PERIOD" 1 "PWM_UNDER_MIN_DUTY" 0 "PWM_OVER_MAX_DUTY" ;
VAL_ 1291 TAS_a129_valveFaultType 7 "VALVE_OTHER_CIRCUIT" 6 "VALVE_SENSOR_ERROR" 5 "VALVE_HS_DRIVE_STUCK_OFF" 4 "VALVE_HS_DRIVE_STUCK_ON" 3 "VALVE_SHORT_CIRCUIT_12V" 2 "VALVE_SHORT_CIRCUIT_GND" 1 "VALVE_OPEN_CIRCUIT" 0 "VALVE_OVER_DUTY_CYCLE_LIMIT" ;
VAL_ 1291 TAS_a130_valveFaultType 7 "VALVE_OTHER_CIRCUIT" 6 "VALVE_SENSOR_ERROR" 5 "VALVE_HS_DRIVE_STUCK_OFF" 4 "VALVE_HS_DRIVE_STUCK_ON" 3 "VALVE_SHORT_CIRCUIT_12V" 2 "VALVE_SHORT_CIRCUIT_GND" 1 "VALVE_OPEN_CIRCUIT" 0 "VALVE_OVER_DUTY_CYCLE_LIMIT" ;
VAL_ 1291 TAS_a131_valveFaultType 7 "VALVE_OTHER_CIRCUIT" 6 "VALVE_SENSOR_ERROR" 5 "VALVE_HS_DRIVE_STUCK_OFF" 4 "VALVE_HS_DRIVE_STUCK_ON" 3 "VALVE_SHORT_CIRCUIT_12V" 2 "VALVE_SHORT_CIRCUIT_GND" 1 "VALVE_OPEN_CIRCUIT" 0 "VALVE_OVER_DUTY_CYCLE_LIMIT" ;
VAL_ 1291 TAS_a132_valveFaultType 7 "VALVE_OTHER_CIRCUIT" 6 "VALVE_SENSOR_ERROR" 5 "VALVE_HS_DRIVE_STUCK_OFF" 4 "VALVE_HS_DRIVE_STUCK_ON" 3 "VALVE_SHORT_CIRCUIT_12V" 2 "VALVE_SHORT_CIRCUIT_GND" 1 "VALVE_OPEN_CIRCUIT" 0 "VALVE_OVER_DUTY_CYCLE_LIMIT" ;
VAL_ 1291 TAS_a133_valveFaultType 7 "VALVE_OTHER_CIRCUIT" 6 "VALVE_SENSOR_ERROR" 5 "VALVE_HS_DRIVE_STUCK_OFF" 4 "VALVE_HS_DRIVE_STUCK_ON" 3 "VALVE_SHORT_CIRCUIT_12V" 2 "VALVE_SHORT_CIRCUIT_GND" 1 "VALVE_OPEN_CIRCUIT" 0 "VALVE_OVER_DUTY_CYCLE_LIMIT" ;
VAL_ 1291 TAS_a134_valveFaultType 7 "VALVE_OTHER_CIRCUIT" 6 "VALVE_SENSOR_ERROR" 5 "VALVE_HS_DRIVE_STUCK_OFF" 4 "VALVE_HS_DRIVE_STUCK_ON" 3 "VALVE_SHORT_CIRCUIT_12V" 2 "VALVE_SHORT_CIRCUIT_GND" 1 "VALVE_OPEN_CIRCUIT" 0 "VALVE_OVER_DUTY_CYCLE_LIMIT" ;
VAL_ 1291 TAS_a135_valveFaultType 7 "VALVE_OTHER_CIRCUIT" 6 "VALVE_SENSOR_ERROR" 5 "VALVE_HS_DRIVE_STUCK_OFF" 4 "VALVE_HS_DRIVE_STUCK_ON" 3 "VALVE_SHORT_CIRCUIT_12V" 2 "VALVE_SHORT_CIRCUIT_GND" 1 "VALVE_OPEN_CIRCUIT" 0 "VALVE_OVER_DUTY_CYCLE_LIMIT" ;
VAL_ 1291 TAS_a136_valveFaultType 7 "VALVE_OTHER_CIRCUIT" 6 "VALVE_SENSOR_ERROR" 5 "VALVE_HS_DRIVE_STUCK_OFF" 4 "VALVE_HS_DRIVE_STUCK_ON" 3 "VALVE_SHORT_CIRCUIT_12V" 2 "VALVE_SHORT_CIRCUIT_GND" 1 "VALVE_OPEN_CIRCUIT" 0 "VALVE_OVER_DUTY_CYCLE_LIMIT" ;
VAL_ 1291 TAS_a137_valveFaultType 7 "VALVE_OTHER_CIRCUIT" 6 "VALVE_SENSOR_ERROR" 5 "VALVE_HS_DRIVE_STUCK_OFF" 4 "VALVE_HS_DRIVE_STUCK_ON" 3 "VALVE_SHORT_CIRCUIT_12V" 2 "VALVE_SHORT_CIRCUIT_GND" 1 "VALVE_OPEN_CIRCUIT" 0 "VALVE_OVER_DUTY_CYCLE_LIMIT" ;
VAL_ 1291 TAS_a138_valveFaultType 7 "VALVE_OTHER_CIRCUIT" 6 "VALVE_SENSOR_ERROR" 5 "VALVE_HS_DRIVE_STUCK_OFF" 4 "VALVE_HS_DRIVE_STUCK_ON" 3 "VALVE_SHORT_CIRCUIT_12V" 2 "VALVE_SHORT_CIRCUIT_GND" 1 "VALVE_OPEN_CIRCUIT" 0 "VALVE_OVER_DUTY_CYCLE_LIMIT" ;
VAL_ 1291 TAS_a139_valveFaultType 7 "VALVE_OTHER_CIRCUIT" 6 "VALVE_SENSOR_ERROR" 5 "VALVE_HS_DRIVE_STUCK_OFF" 4 "VALVE_HS_DRIVE_STUCK_ON" 3 "VALVE_SHORT_CIRCUIT_12V" 2 "VALVE_SHORT_CIRCUIT_GND" 1 "VALVE_OPEN_CIRCUIT" 0 "VALVE_OVER_DUTY_CYCLE_LIMIT" ;
VAL_ 1291 TAS_a140_valveFaultType 7 "VALVE_OTHER_CIRCUIT" 6 "VALVE_SENSOR_ERROR" 5 "VALVE_HS_DRIVE_STUCK_OFF" 4 "VALVE_HS_DRIVE_STUCK_ON" 3 "VALVE_SHORT_CIRCUIT_12V" 2 "VALVE_SHORT_CIRCUIT_GND" 1 "VALVE_OPEN_CIRCUIT" 0 "VALVE_OVER_DUTY_CYCLE_LIMIT" ;
VAL_ 1291 TAS_a141_valveFaultType 7 "VALVE_OTHER_CIRCUIT" 6 "VALVE_SENSOR_ERROR" 5 "VALVE_HS_DRIVE_STUCK_OFF" 4 "VALVE_HS_DRIVE_STUCK_ON" 3 "VALVE_SHORT_CIRCUIT_12V" 2 "VALVE_SHORT_CIRCUIT_GND" 1 "VALVE_OPEN_CIRCUIT" 0 "VALVE_OVER_DUTY_CYCLE_LIMIT" ;
VAL_ 1291 TAS_a142_valveFaultType 7 "VALVE_OTHER_CIRCUIT" 6 "VALVE_SENSOR_ERROR" 5 "VALVE_HS_DRIVE_STUCK_OFF" 4 "VALVE_HS_DRIVE_STUCK_ON" 3 "VALVE_SHORT_CIRCUIT_12V" 2 "VALVE_SHORT_CIRCUIT_GND" 1 "VALVE_OPEN_CIRCUIT" 0 "VALVE_OVER_DUTY_CYCLE_LIMIT" ;
VAL_ 1291 TAS_a143_valveFaultType 7 "VALVE_OTHER_CIRCUIT" 6 "VALVE_SENSOR_ERROR" 5 "VALVE_HS_DRIVE_STUCK_OFF" 4 "VALVE_HS_DRIVE_STUCK_ON" 3 "VALVE_SHORT_CIRCUIT_12V" 2 "VALVE_SHORT_CIRCUIT_GND" 1 "VALVE_OPEN_CIRCUIT" 0 "VALVE_OVER_DUTY_CYCLE_LIMIT" ;
VAL_ 1291 TAS_a144_valveFaultType 7 "VALVE_OTHER_CIRCUIT" 6 "VALVE_SENSOR_ERROR" 5 "VALVE_HS_DRIVE_STUCK_OFF" 4 "VALVE_HS_DRIVE_STUCK_ON" 3 "VALVE_SHORT_CIRCUIT_12V" 2 "VALVE_SHORT_CIRCUIT_GND" 1 "VALVE_OPEN_CIRCUIT" 0 "VALVE_OVER_DUTY_CYCLE_LIMIT" ;
VAL_ 1291 TAS_a145_valveFaultType 7 "VALVE_OTHER_CIRCUIT" 6 "VALVE_SENSOR_ERROR" 5 "VALVE_HS_DRIVE_STUCK_OFF" 4 "VALVE_HS_DRIVE_STUCK_ON" 3 "VALVE_SHORT_CIRCUIT_12V" 2 "VALVE_SHORT_CIRCUIT_GND" 1 "VALVE_OPEN_CIRCUIT" 0 "VALVE_OVER_DUTY_CYCLE_LIMIT" ;
VAL_ 1291 TAS_a146_valveFaultType 7 "VALVE_OTHER_CIRCUIT" 6 "VALVE_SENSOR_ERROR" 5 "VALVE_HS_DRIVE_STUCK_OFF" 4 "VALVE_HS_DRIVE_STUCK_ON" 3 "VALVE_SHORT_CIRCUIT_12V" 2 "VALVE_SHORT_CIRCUIT_GND" 1 "VALVE_OPEN_CIRCUIT" 0 "VALVE_OVER_DUTY_CYCLE_LIMIT" ;
VAL_ 1291 TAS_a147_valveFaultType 7 "VALVE_OTHER_CIRCUIT" 6 "VALVE_SENSOR_ERROR" 5 "VALVE_HS_DRIVE_STUCK_OFF" 4 "VALVE_HS_DRIVE_STUCK_ON" 3 "VALVE_SHORT_CIRCUIT_12V" 2 "VALVE_SHORT_CIRCUIT_GND" 1 "VALVE_OPEN_CIRCUIT" 0 "VALVE_OVER_DUTY_CYCLE_LIMIT" ;
VAL_ 1291 TAS_a148_valveFaultType 7 "VALVE_OTHER_CIRCUIT" 6 "VALVE_SENSOR_ERROR" 5 "VALVE_HS_DRIVE_STUCK_OFF" 4 "VALVE_HS_DRIVE_STUCK_ON" 3 "VALVE_SHORT_CIRCUIT_12V" 2 "VALVE_SHORT_CIRCUIT_GND" 1 "VALVE_OPEN_CIRCUIT" 0 "VALVE_OVER_DUTY_CYCLE_LIMIT" ;
VAL_ 1291 TAS_a149_valveFaultType 7 "VALVE_OTHER_CIRCUIT" 6 "VALVE_SENSOR_ERROR" 5 "VALVE_HS_DRIVE_STUCK_OFF" 4 "VALVE_HS_DRIVE_STUCK_ON" 3 "VALVE_SHORT_CIRCUIT_12V" 2 "VALVE_SHORT_CIRCUIT_GND" 1 "VALVE_OPEN_CIRCUIT" 0 "VALVE_OVER_DUTY_CYCLE_LIMIT" ;
VAL_ 1291 TAS_a150_valveFaultType 7 "VALVE_OTHER_CIRCUIT" 6 "VALVE_SENSOR_ERROR" 5 "VALVE_HS_DRIVE_STUCK_OFF" 4 "VALVE_HS_DRIVE_STUCK_ON" 3 "VALVE_SHORT_CIRCUIT_12V" 2 "VALVE_SHORT_CIRCUIT_GND" 1 "VALVE_OPEN_CIRCUIT" 0 "VALVE_OVER_DUTY_CYCLE_LIMIT" ;
VAL_ 1291 TAS_a151_valveFaultType 7 "VALVE_OTHER_CIRCUIT" 6 "VALVE_SENSOR_ERROR" 5 "VALVE_HS_DRIVE_STUCK_OFF" 4 "VALVE_HS_DRIVE_STUCK_ON" 3 "VALVE_SHORT_CIRCUIT_12V" 2 "VALVE_SHORT_CIRCUIT_GND" 1 "VALVE_OPEN_CIRCUIT" 0 "VALVE_OVER_DUTY_CYCLE_LIMIT" ;
VAL_ 1291 TAS_a152_valveFaultType 7 "VALVE_OTHER_CIRCUIT" 6 "VALVE_SENSOR_ERROR" 5 "VALVE_HS_DRIVE_STUCK_OFF" 4 "VALVE_HS_DRIVE_STUCK_ON" 3 "VALVE_SHORT_CIRCUIT_12V" 2 "VALVE_SHORT_CIRCUIT_GND" 1 "VALVE_OPEN_CIRCUIT" 0 "VALVE_OVER_DUTY_CYCLE_LIMIT" ;
VAL_ 1291 TAS_a153_valveFaultType 7 "VALVE_OTHER_CIRCUIT" 6 "VALVE_SENSOR_ERROR" 5 "VALVE_HS_DRIVE_STUCK_OFF" 4 "VALVE_HS_DRIVE_STUCK_ON" 3 "VALVE_SHORT_CIRCUIT_12V" 2 "VALVE_SHORT_CIRCUIT_GND" 1 "VALVE_OPEN_CIRCUIT" 0 "VALVE_OVER_DUTY_CYCLE_LIMIT" ;
VAL_ 1291 TAS_a154_valveFaultType 7 "VALVE_OTHER_CIRCUIT" 6 "VALVE_SENSOR_ERROR" 5 "VALVE_HS_DRIVE_STUCK_OFF" 4 "VALVE_HS_DRIVE_STUCK_ON" 3 "VALVE_SHORT_CIRCUIT_12V" 2 "VALVE_SHORT_CIRCUIT_GND" 1 "VALVE_OPEN_CIRCUIT" 0 "VALVE_OVER_DUTY_CYCLE_LIMIT" ;
VAL_ 1291 TAS_a155_valveFaultType 7 "VALVE_OTHER_CIRCUIT" 6 "VALVE_SENSOR_ERROR" 5 "VALVE_HS_DRIVE_STUCK_OFF" 4 "VALVE_HS_DRIVE_STUCK_ON" 3 "VALVE_SHORT_CIRCUIT_12V" 2 "VALVE_SHORT_CIRCUIT_GND" 1 "VALVE_OPEN_CIRCUIT" 0 "VALVE_OVER_DUTY_CYCLE_LIMIT" ;
VAL_ 1291 TAS_a156_valveFaultType 7 "VALVE_OTHER_CIRCUIT" 6 "VALVE_SENSOR_ERROR" 5 "VALVE_HS_DRIVE_STUCK_OFF" 4 "VALVE_HS_DRIVE_STUCK_ON" 3 "VALVE_SHORT_CIRCUIT_12V" 2 "VALVE_SHORT_CIRCUIT_GND" 1 "VALVE_OPEN_CIRCUIT" 0 "VALVE_OVER_DUTY_CYCLE_LIMIT" ;
VAL_ 1291 TAS_a157_valveFaultType 7 "VALVE_OTHER_CIRCUIT" 6 "VALVE_SENSOR_ERROR" 5 "VALVE_HS_DRIVE_STUCK_OFF" 4 "VALVE_HS_DRIVE_STUCK_ON" 3 "VALVE_SHORT_CIRCUIT_12V" 2 "VALVE_SHORT_CIRCUIT_GND" 1 "VALVE_OPEN_CIRCUIT" 0 "VALVE_OVER_DUTY_CYCLE_LIMIT" ;
VAL_ 1291 TAS_a158_valveFaultType 7 "VALVE_OTHER_CIRCUIT" 6 "VALVE_SENSOR_ERROR" 5 "VALVE_HS_DRIVE_STUCK_OFF" 4 "VALVE_HS_DRIVE_STUCK_ON" 3 "VALVE_SHORT_CIRCUIT_12V" 2 "VALVE_SHORT_CIRCUIT_GND" 1 "VALVE_OPEN_CIRCUIT" 0 "VALVE_OVER_DUTY_CYCLE_LIMIT" ;
VAL_ 1291 TAS_a159_valveFaultType 7 "VALVE_OTHER_CIRCUIT" 6 "VALVE_SENSOR_ERROR" 5 "VALVE_HS_DRIVE_STUCK_OFF" 4 "VALVE_HS_DRIVE_STUCK_ON" 3 "VALVE_SHORT_CIRCUIT_12V" 2 "VALVE_SHORT_CIRCUIT_GND" 1 "VALVE_OPEN_CIRCUIT" 0 "VALVE_OVER_DUTY_CYCLE_LIMIT" ;
VAL_ 1291 TAS_a160_valveFaultType 7 "VALVE_OTHER_CIRCUIT" 6 "VALVE_SENSOR_ERROR" 5 "VALVE_HS_DRIVE_STUCK_OFF" 4 "VALVE_HS_DRIVE_STUCK_ON" 3 "VALVE_SHORT_CIRCUIT_12V" 2 "VALVE_SHORT_CIRCUIT_GND" 1 "VALVE_OPEN_CIRCUIT" 0 "VALVE_OVER_DUTY_CYCLE_LIMIT" ;
VAL_ 1291 TAS_a226_PWMfaultFL 6 "PWM_OPEN_CIRCUIT" 5 "PWM_SHORT_CIRCUIT" 4 "PWM_OVER_MAX_DELTA_DUTY" 3 "PWM_UNDER_MIN_PERIOD" 2 "PWM_OVER_MAX_PERIOD" 1 "PWM_UNDER_MIN_DUTY" 0 "PWM_OVER_MAX_DUTY" ;
VAL_ 1291 TAS_a227_PWMfaultFR 6 "PWM_OPEN_CIRCUIT" 5 "PWM_SHORT_CIRCUIT" 4 "PWM_OVER_MAX_DELTA_DUTY" 3 "PWM_UNDER_MIN_PERIOD" 2 "PWM_OVER_MAX_PERIOD" 1 "PWM_UNDER_MIN_DUTY" 0 "PWM_OVER_MAX_DUTY" ;
VAL_ 1291 TAS_a228_PWMfaultRL 6 "PWM_OPEN_CIRCUIT" 5 "PWM_SHORT_CIRCUIT" 4 "PWM_OVER_MAX_DELTA_DUTY" 3 "PWM_UNDER_MIN_PERIOD" 2 "PWM_OVER_MAX_PERIOD" 1 "PWM_UNDER_MIN_DUTY" 0 "PWM_OVER_MAX_DUTY" ;
VAL_ 1291 TAS_a229_PWMfaultRR 6 "PWM_OPEN_CIRCUIT" 5 "PWM_SHORT_CIRCUIT" 4 "PWM_OVER_MAX_DELTA_DUTY" 3 "PWM_UNDER_MIN_PERIOD" 2 "PWM_OVER_MAX_PERIOD" 1 "PWM_UNDER_MIN_DUTY" 0 "PWM_OVER_MAX_DUTY" ;
VAL_ 523 TAS_axleIndex 10 "TAS_axleRear" 5 "TAS_axleFront" ;
VAL_ 523 TAS_fastFilteredHeightFL 255 "SNA" ;
VAL_ 523 TAS_modeFilteredHeightFL 255 "SNA" ;
VAL_ 523 TAS_componentPressureFL 255 "SNA" ;
VAL_ 523 TAS_fastFilteredHeightFR 255 "SNA" ;
VAL_ 523 TAS_modeFilteredHeightFR 255 "SNA" ;
VAL_ 523 TAS_componentPressureFR 255 "SNA" ;
VAL_ 523 TAS_fastFilteredHeightRL 255 "SNA" ;
VAL_ 523 TAS_modeFilteredHeightRL 255 "SNA" ;
VAL_ 523 TAS_componentPressureRL 255 "SNA" ;
VAL_ 523 TAS_fastFilteredHeightRR 255 "SNA" ;
VAL_ 523 TAS_modeFilteredHeightRR 255 "SNA" ;
VAL_ 523 TAS_componentPressureRR 255 "SNA" ;
VAL_ 1313 TAS_firmwareType 2 "BOOTLOADER_UPDATER" 1 "BOOTLOADER" 0 "APPLICATION" ;
VAL_ 1035 TAS_nmKeepAwakeReason 15 "TAS_KEEPAWAKE_REASON_MULTIPLE" 1 "TAS_KEEPAWAKE_REASON_LEVELING_IN_PROGRESS" 0 "TAS_KEEPAWAKE_REASON_NONE_SNA" ;
VAL_ 1035 TAS_nmWakeUpReason 3 "CH_WAKEUP_REASON_RESET" 2 "CH_WAKEUP_REASON_SWITCH_INPUT" 1 "CH_WAKEUP_REASON_ECU_SPECIFIC" 0 "CH_WAKEUP_REASON_NONE" ;
VAL_ 546 TAS_compTempSensor 255 "SNA" ;
VAL_ 546 TAS_compTempModel 255 "SNA" ;
SIG_GROUP_ 69 StW_Actn_Rq 1 : CRC_STW_ACTN_RQ DTR_Dist_Rq HiBmLvr_Stat HrnSw_Psd MC_STW_ACTN_RQ SpdCtrlLvrStat_Inv SpdCtrlLvr_Stat StW_Cond_Flt StW_Cond_Psd StW_Lvr_Stat StW_Sw00_Psd StW_Sw01_Psd StW_Sw02_Psd StW_Sw03_Psd StW_Sw04_Psd StW_Sw05_Psd StW_Sw06_Psd StW_Sw07_Psd StW_Sw08_Psd StW_Sw09_Psd StW_Sw10_Psd StW_Sw11_Psd StW_Sw12_Psd StW_Sw13_Psd StW_Sw14_Psd StW_Sw15_Psd TurnIndLvr_Stat VSL_Enbl_Rq WprSw6Posn WprWashSw_Psd WprWash_R_Sw_Posn_V2;
